VERSION "dbc-export 1 2026.26.6.5"

NS_ :

BS_:

BU_: APP APS BMS CC CMP CMPD CP DAS DI DIF DIR EPBL EPBR EVSE FC GTW HCML HCMR HVP ICR PCS PCS2 PLG PM PMF PMR PTC SCCM SCM SCS SDCR TAS UMC V2G VC VCBATT VCBATT0 VCBATT1 VCBATT2 VCFRONT VCFRONT1 VCFRONT2 VCLEFT VCRIGHT VCSEC

BO_ 1017 VCSEC_alertMatrix: 8 VCSEC
 SG_ VCSEC_matrixIndex M : 0|4@1+ (1,0) [0|15] "" Vector__XXX
 SG_ VCSEC_a001_WatchdogReset m0 : 4|1@1+ (1,0) [0|1] "" Vector__XXX
 SG_ VCSEC_a002_PowerLossReset m0 : 5|1@1+ (1,0) [0|1] "" Vector__XXX
 SG_ VCSEC_a003_SWAssertion m0 : 6|1@1+ (1,0) [0|1] "" Vector__XXX
 SG_ VCSEC_a005_CANTXError m0 : 8|1@1+ (1,0) [0|1] "" Vector__XXX
 SG_ VCSEC_a006_CANTX_cyclicError m0 : 9|1@1+ (1,0) [0|1] "" Vector__XXX
 SG_ VCSEC_a010_ExtSupplyVoltError m0 : 13|1@1+ (1,0) [0|1] "" Vector__XXX
 SG_ VCSEC_a012_CPUReset m0 : 15|1@1+ (1,0) [0|1] "" Vector__XXX
 SG_ VCSEC_a013_AlertManagerFault m0 : 16|1@1+ (1,0) [0|1] "" Vector__XXX
 SG_ VCSEC_a015_NVMMError m0 : 18|1@1+ (1,0) [0|1] "" Vector__XXX
 SG_ VCSEC_a016_NVMMRecordError m0 : 19|1@1+ (1,0) [0|1] "" Vector__XXX
 SG_ VCSEC_a017_NVMMStatusDbg m0 : 20|1@1+ (1,0) [0|1] "" Vector__XXX
 SG_ VCSEC_a021_TaskSchedulerError m0 : 24|1@1+ (1,0) [0|1] "" Vector__XXX
 SG_ VCSEC_a022_TaskInitError m0 : 25|1@1+ (1,0) [0|1] "" Vector__XXX
 SG_ VCSEC_a029_CoreDump m0 : 32|1@1+ (1,0) [0|1] "" Vector__XXX
 SG_ VCSEC_a030_ECULogUploadRequest m0 : 33|1@1+ (1,0) [0|1] "" Vector__XXX
 SG_ VCSEC_a031_UDSActive m0 : 34|1@1+ (1,0) [0|1] "" Vector__XXX
 SG_ VCSEC_a041_HighCPULoad m0 : 44|1@1+ (1,0) [0|1] "" Vector__XXX
 SG_ VCSEC_a042_HighStackUsage m0 : 45|1@1+ (1,0) [0|1] "" Vector__XXX
 SG_ VCSEC_a043_Task1msError m0 : 46|1@1+ (1,0) [0|1] "" Vector__XXX
 SG_ VCSEC_a044_Task10msError m0 : 47|1@1+ (1,0) [0|1] "" Vector__XXX
 SG_ VCSEC_a045_Task100msError m0 : 48|1@1+ (1,0) [0|1] "" Vector__XXX
 SG_ VCSEC_a046_Task1000msError m0 : 49|1@1+ (1,0) [0|1] "" Vector__XXX
 SG_ VCSEC_a057_HVP_MIA m0 : 60|1@1+ (1,0) [0|1] "" Vector__XXX
 SG_ VCSEC_a058_inputRHighSyncDebug m0 : 61|1@1+ (1,0) [0|1] "" Vector__XXX
 SG_ VCSEC_a059_inputResistanceHigh m0 : 62|1@1+ (1,0) [0|1] "" Vector__XXX
 SG_ VCSEC_a060_engineeringBuild m0 : 63|1@1+ (1,0) [0|1] "" Vector__XXX
 SG_ VCSEC_a061_XCPConnected m1 : 4|1@1+ (1,0) [0|1] "" Vector__XXX
 SG_ VCSEC_a062_XCPWasConnected m1 : 5|1@1+ (1,0) [0|1] "" Vector__XXX
 SG_ VCSEC_a063_SwitchFault m1 : 6|1@1+ (1,0) [0|1] "" Vector__XXX
 SG_ VCSEC_a064_busSleepReqTimeout m1 : 7|1@1+ (1,0) [0|1] "" Vector__XXX
 SG_ VCSEC_a082_VCRIGHT_IPC_MIA m1 : 25|1@1+ (1,0) [0|1] "" Vector__XXX
 SG_ VCSEC_a083_VCLEFT_IPC_MIA m1 : 26|1@1+ (1,0) [0|1] "" Vector__XXX
 SG_ VCSEC_a084_TPMS_MIA m1 : 27|1@1+ (1,0) [0|1] "" Vector__XXX
 SG_ VCSEC_a085_CCCM_MIA m1 : 28|1@1+ (1,0) [0|1] "" Vector__XXX
 SG_ VCSEC_a086_VCBATT_MIA m1 : 29|1@1+ (1,0) [0|1] "" Vector__XXX
 SG_ VCSEC_a087_DIREL_MIA m1 : 30|1@1+ (1,0) [0|1] "" Vector__XXX
 SG_ VCSEC_a088_DIRER_MIA m1 : 31|1@1+ (1,0) [0|1] "" Vector__XXX
 SG_ VCSEC_a089_IBST_MIA m1 : 32|1@1+ (1,0) [0|1] "" Vector__XXX
 SG_ VCSEC_a090_APS_MIA m1 : 33|1@1+ (1,0) [0|1] "" Vector__XXX
 SG_ VCSEC_a091_CMPD_MIA m1 : 34|1@1+ (1,0) [0|1] "" Vector__XXX
 SG_ VCSEC_a092_VCSEATD_MIA m1 : 35|1@1+ (1,0) [0|1] "" Vector__XXX
 SG_ VCSEC_a093_VCSEATP_MIA m1 : 36|1@1+ (1,0) [0|1] "" Vector__XXX
 SG_ VCSEC_a094_EPAS3P_MIA m1 : 37|1@1+ (1,0) [0|1] "" Vector__XXX
 SG_ VCSEC_a095_CHG_MIA m1 : 38|1@1+ (1,0) [0|1] "" Vector__XXX
 SG_ VCSEC_a096_OCS1P_MIA m1 : 39|1@1+ (1,0) [0|1] "" Vector__XXX
 SG_ VCSEC_a097_CMP_MIA m1 : 40|1@1+ (1,0) [0|1] "" Vector__XXX
 SG_ VCSEC_a098_DIR_MIA m1 : 41|1@1+ (1,0) [0|1] "" Vector__XXX
 SG_ VCSEC_a099_PARK_MIA m1 : 42|1@1+ (1,0) [0|1] "" Vector__XXX
 SG_ VCSEC_a100_CANbus_MIA m1 : 43|1@1+ (1,0) [0|1] "" Vector__XXX
 SG_ VCSEC_a101_PM_MIA m1 : 44|1@1+ (1,0) [0|1] "" Vector__XXX
 SG_ VCSEC_a102_PTC_MIA m1 : 45|1@1+ (1,0) [0|1] "" Vector__XXX
 SG_ VCSEC_a103_CP_MIA m1 : 46|1@1+ (1,0) [0|1] "" Vector__XXX
 SG_ VCSEC_a104_DAS_MIA m1 : 47|1@1+ (1,0) [0|1] "" Vector__XXX
 SG_ VCSEC_a105_TAS_MIA m1 : 48|1@1+ (1,0) [0|1] "" Vector__XXX
 SG_ VCSEC_a106_PCS_MIA m1 : 49|1@1+ (1,0) [0|1] "" Vector__XXX
 SG_ VCSEC_a107_BMS_MIA m1 : 50|1@1+ (1,0) [0|1] "" Vector__XXX
 SG_ VCSEC_a108_DIF_MIA m1 : 51|1@1+ (1,0) [0|1] "" Vector__XXX
 SG_ VCSEC_a109_RCM_MIA m1 : 52|1@1+ (1,0) [0|1] "" Vector__XXX
 SG_ VCSEC_a110_GTW_MIA m1 : 53|1@1+ (1,0) [0|1] "" Vector__XXX
 SG_ VCSEC_a111_EPBR_MIA m1 : 54|1@1+ (1,0) [0|1] "" Vector__XXX
 SG_ VCSEC_a112_EPBL_MIA m1 : 55|1@1+ (1,0) [0|1] "" Vector__XXX
 SG_ VCSEC_a113_UI_MIA m1 : 56|1@1+ (1,0) [0|1] "" Vector__XXX
 SG_ VCSEC_a114_ESP_MIA m1 : 57|1@1+ (1,0) [0|1] "" Vector__XXX
 SG_ VCSEC_a115_VCSEC_MIA m1 : 58|1@1+ (1,0) [0|1] "" Vector__XXX
 SG_ VCSEC_a116_VCRIGHT_MIA m1 : 59|1@1+ (1,0) [0|1] "" Vector__XXX
 SG_ VCSEC_a117_VCLEFT_MIA m1 : 60|1@1+ (1,0) [0|1] "" Vector__XXX
 SG_ VCSEC_a118_VCFRONT_MIA m1 : 61|1@1+ (1,0) [0|1] "" Vector__XXX
 SG_ VCSEC_a119_SCCM_MIA m1 : 62|1@1+ (1,0) [0|1] "" Vector__XXX
 SG_ VCSEC_a120_DI_DRIVE_MIA m1 : 63|1@1+ (1,0) [0|1] "" Vector__XXX
 SG_ VCSEC_a121_ICR_MIA m2 : 4|1@1+ (1,0) [0|1] "" Vector__XXX
 SG_ VCSEC_a133_alarmTriggered m2 : 16|1@1+ (1,0) [0|1] "" Vector__XXX
 SG_ VCSEC_a134_noVINLoaded m2 : 17|1@1+ (1,0) [0|1] "" Vector__XXX
 SG_ VCSEC_a135_centerEndpointBusy m2 : 18|1@1+ (1,0) [0|1] "" Vector__XXX
 SG_ VCSEC_a136_leftEndpointBusy m2 : 19|1@1+ (1,0) [0|1] "" Vector__XXX
 SG_ VCSEC_a137_rightEndpointBusy m2 : 20|1@1+ (1,0) [0|1] "" Vector__XXX
 SG_ VCSEC_a138_rearEndpointBusy m2 : 21|1@1+ (1,0) [0|1] "" Vector__XXX
 SG_ VCSEC_a140_nfcAuthentication m2 : 23|1@1+ (1,0) [0|1] "" Vector__XXX
 SG_ VCSEC_a141_tooFewKeysOnWhitelist m2 : 24|1@1+ (1,0) [0|1] "" Vector__XXX
 SG_ VCSEC_a142_bleGattAlertC m2 : 25|1@1+ (1,0) [0|1] "" Vector__XXX
 SG_ VCSEC_a143_bleGattAlertL m2 : 26|1@1+ (1,0) [0|1] "" Vector__XXX
 SG_ VCSEC_a144_bleGattAlertR m2 : 27|1@1+ (1,0) [0|1] "" Vector__XXX
 SG_ VCSEC_a145_bleGattAlertRe m2 : 28|1@1+ (1,0) [0|1] "" Vector__XXX
 SG_ VCSEC_a147_protobufRXTimeout m2 : 30|1@1+ (1,0) [0|1] "" Vector__XXX
 SG_ VCSEC_a148_keyWhitelistFull m2 : 31|1@1+ (1,0) [0|1] "" Vector__XXX
 SG_ VCSEC_a149_attrsWentMissingL m2 : 32|1@1+ (1,0) [0|1] "" Vector__XXX
 SG_ VCSEC_a150_attrsWentMissingR m2 : 33|1@1+ (1,0) [0|1] "" Vector__XXX
 SG_ VCSEC_a151_attrsWentMissingRe m2 : 34|1@1+ (1,0) [0|1] "" Vector__XXX
 SG_ VCSEC_a153_srvcCmdTimeoutC m2 : 36|1@1+ (1,0) [0|1] "" Vector__XXX
 SG_ VCSEC_a154_srvcCmdTimeoutL m2 : 37|1@1+ (1,0) [0|1] "" Vector__XXX
 SG_ VCSEC_a155_srvcCmdTimeoutR m2 : 38|1@1+ (1,0) [0|1] "" Vector__XXX
 SG_ VCSEC_a156_srvcCmdTimeoutRe m2 : 39|1@1+ (1,0) [0|1] "" Vector__XXX
 SG_ VCSEC_a158_hciDebugC m2 : 41|1@1+ (1,0) [0|1] "" Vector__XXX
 SG_ VCSEC_a159_hciDebugL m2 : 42|1@1+ (1,0) [0|1] "" Vector__XXX
 SG_ VCSEC_a161_hciDebugR m2 : 44|1@1+ (1,0) [0|1] "" Vector__XXX
 SG_ VCSEC_a162_hciDebugRe m2 : 45|1@1+ (1,0) [0|1] "" Vector__XXX
 SG_ VCSEC_a164_attrsWentMissingC m2 : 47|1@1+ (1,0) [0|1] "" Vector__XXX
 SG_ VCSEC_a165_ephemeralKeyGenerated m2 : 48|1@1+ (1,0) [0|1] "" Vector__XXX
 SG_ VCSEC_a166_BLECenterPowerCycled m2 : 49|1@1+ (1,0) [0|1] "" Vector__XXX
 SG_ VCSEC_a167_BLECenterSoftReset m2 : 50|1@1+ (1,0) [0|1] "" Vector__XXX
 SG_ VCSEC_a168_BLELeftSoftReset m2 : 51|1@1+ (1,0) [0|1] "" Vector__XXX
 SG_ VCSEC_a169_BLERightSoftReset m2 : 52|1@1+ (1,0) [0|1] "" Vector__XXX
 SG_ VCSEC_a170_BLERearSoftReset m2 : 53|1@1+ (1,0) [0|1] "" Vector__XXX
 SG_ VCSEC_a172_BLEUnexpectedResetC m2 : 55|1@1+ (1,0) [0|1] "" Vector__XXX
 SG_ VCSEC_a173_BLEUnexpectedResetL m2 : 56|1@1+ (1,0) [0|1] "" Vector__XXX
 SG_ VCSEC_a174_BLEUnexpectedResetRi m2 : 57|1@1+ (1,0) [0|1] "" Vector__XXX
 SG_ VCSEC_a175_BLEUnexpectedResetRe m2 : 58|1@1+ (1,0) [0|1] "" Vector__XXX
 SG_ VCSEC_a177_whitelistAddedKey m2 : 60|1@1+ (1,0) [0|1] "" Vector__XXX
 SG_ VCSEC_a178_whitelistRemovedKey m2 : 61|1@1+ (1,0) [0|1] "" Vector__XXX
 SG_ VCSEC_a179_InfotainmentNotPaired m2 : 62|1@1+ (1,0) [0|1] "" Vector__XXX
 SG_ VCSEC_a180_wlistRemovedPermissio m2 : 63|1@1+ (1,0) [0|1] "" Vector__XXX
 SG_ VCSEC_a181_signedMessageFault m3 : 4|1@1+ (1,0) [0|1] "" Vector__XXX
 SG_ VCSEC_a182_cryptoHighStackUsage m3 : 5|1@1+ (1,0) [0|1] "" Vector__XXX
 SG_ VCSEC_a183_centerEndpointRFMia m3 : 6|1@1+ (1,0) [0|1] "" Vector__XXX
 SG_ VCSEC_a184_driverEndpointRFMia m3 : 7|1@1+ (1,0) [0|1] "" Vector__XXX
 SG_ VCSEC_a185_passengerEndpointRFMi m3 : 8|1@1+ (1,0) [0|1] "" Vector__XXX
 SG_ VCSEC_a186_rearEndpointRFMia m3 : 9|1@1+ (1,0) [0|1] "" Vector__XXX
 SG_ VCSEC_a187_badConnectionDropped m3 : 10|1@1+ (1,0) [0|1] "" Vector__XXX
 SG_ VCSEC_a188_protobufDecodeError m3 : 11|1@1+ (1,0) [0|1] "" Vector__XXX
 SG_ VCSEC_a189_protoExpLengthTooLarg m3 : 12|1@1+ (1,0) [0|1] "" Vector__XXX
 SG_ VCSEC_a190_protoTooManyBytes m3 : 13|1@1+ (1,0) [0|1] "" Vector__XXX
 SG_ VCSEC_a191_macIDWlistingFailedC m3 : 14|1@1+ (1,0) [0|1] "" Vector__XXX
 SG_ VCSEC_a192_macIDWlistingFailedL m3 : 15|1@1+ (1,0) [0|1] "" Vector__XXX
 SG_ VCSEC_a193_macIDWlistingFailedRi m3 : 16|1@1+ (1,0) [0|1] "" Vector__XXX
 SG_ VCSEC_a194_macIDWlistingFailedRe m3 : 17|1@1+ (1,0) [0|1] "" Vector__XXX
 SG_ VCSEC_a195_keyMissingInDrive m3 : 18|1@1+ (1,0) [0|1] "" Vector__XXX
 SG_ VCSEC_a196_protobufTXTimeout m3 : 19|1@1+ (1,0) [0|1] "" Vector__XXX
 SG_ VCSEC_a197_indicationFault m3 : 20|1@1+ (1,0) [0|1] "" Vector__XXX
 SG_ VCSEC_a198_BPillarNFCReaderMIA m3 : 21|1@1+ (1,0) [0|1] "" Vector__XXX
 SG_ VCSEC_a199_CenterNFCReaderMIA m3 : 22|1@1+ (1,0) [0|1] "" Vector__XXX
 SG_ VCSEC_a200_centerEndpointLostCom m3 : 23|1@1+ (1,0) [0|1] "" Vector__XXX
 SG_ VCSEC_a201_leftEndpointLostComm m3 : 24|1@1+ (1,0) [0|1] "" Vector__XXX
 SG_ VCSEC_a202_rightEndpointLostComm m3 : 25|1@1+ (1,0) [0|1] "" Vector__XXX
 SG_ VCSEC_a203_rearEndpointLostComm m3 : 26|1@1+ (1,0) [0|1] "" Vector__XXX
 SG_ VCSEC_a204_SharedSecretsWritten m3 : 27|1@1+ (1,0) [0|1] "" Vector__XXX
 SG_ VCSEC_a205_MTUUpdateNotConfirmed m3 : 28|1@1+ (1,0) [0|1] "" Vector__XXX
 SG_ VCSEC_a206_BLELeftAssertFailure m3 : 29|1@1+ (1,0) [0|1] "" Vector__XXX
 SG_ VCSEC_a207_BLERightAssertFailure m3 : 30|1@1+ (1,0) [0|1] "" Vector__XXX
 SG_ VCSEC_a208_BLERearAssertFailure m3 : 31|1@1+ (1,0) [0|1] "" Vector__XXX
 SG_ VCSEC_a209_BLECenterAssertFailur m3 : 32|1@1+ (1,0) [0|1] "" Vector__XXX
 SG_ VCSEC_a210_keyDeviceBatteryLow m3 : 33|1@1+ (1,0) [0|1] "" Vector__XXX
 SG_ VCSEC_a211_handlePullWithoutAuth m3 : 34|1@1+ (1,0) [0|1] "" Vector__XXX
 SG_ VCSEC_a212_snifferRSSIMIA m3 : 35|1@1+ (1,0) [0|1] "" Vector__XXX
 SG_ VCSEC_a213_gattTimeoutWithExptdC m3 : 36|1@1+ (1,0) [0|1] "" Vector__XXX
 SG_ VCSEC_a214_gattServFalseWaitToBo m3 : 37|1@1+ (1,0) [0|1] "" Vector__XXX
 SG_ VCSEC_a215_TPMSUnexpectedDisconn m3 : 38|1@1+ (1,0) [0|1] "" Vector__XXX
 SG_ VCSEC_a216_TPMSUnexpectedDisconn m3 : 39|1@1+ (1,0) [0|1] "" Vector__XXX
 SG_ VCSEC_a217_TPMSUnexpectedDisconn m3 : 40|1@1+ (1,0) [0|1] "" Vector__XXX
 SG_ VCSEC_a218_TPMSUnexpectedDisconn m3 : 41|1@1+ (1,0) [0|1] "" Vector__XXX
 SG_ VCSEC_a219_TPMSSensorPairingRemo m3 : 42|1@1+ (1,0) [0|1] "" Vector__XXX
 SG_ VCSEC_a220_TPMSSensorPairingNotC m3 : 43|1@1+ (1,0) [0|1] "" Vector__XXX
 SG_ VCSEC_a221_TPMSSoftWarning m3 : 44|1@1+ (1,0) [0|1] "" Vector__XXX
 SG_ VCSEC_a222_TPMSSystemMalfunction m3 : 45|1@1+ (1,0) [0|1] "" Vector__XXX
 SG_ VCSEC_a223_TPMSSensorConnectionC m3 : 46|1@1+ (1,0) [0|1] "" Vector__XXX
 SG_ VCSEC_a224_TPMSSensorConnectionC m3 : 47|1@1+ (1,0) [0|1] "" Vector__XXX
 SG_ VCSEC_a225_TPMSSensorConnectionC m3 : 48|1@1+ (1,0) [0|1] "" Vector__XXX
 SG_ VCSEC_a226_TPMSSensorConnectionC m3 : 49|1@1+ (1,0) [0|1] "" Vector__XXX
 SG_ VCSEC_a227_connectionWithoutLink m3 : 50|1@1+ (1,0) [0|1] "" Vector__XXX
 SG_ VCSEC_a228_TPMSHardWarning m3 : 51|1@1+ (1,0) [0|1] "" Vector__XXX
 SG_ VCSEC_a235_presentWithoutHandleP m3 : 58|1@1+ (1,0) [0|1] "" Vector__XXX
 SG_ VCSEC_a236_keyIdentificationMaxA m3 : 59|1@1+ (1,0) [0|1] "" Vector__XXX
 SG_ VCSEC_a237_keyNotReadyToReceiveI m3 : 60|1@1+ (1,0) [0|1] "" Vector__XXX
 SG_ VCSEC_a238_TPMSLocationsUpdated m3 : 61|1@1+ (1,0) [0|1] "" Vector__XXX
 SG_ VCSEC_a239_TPMSIdleConnection m3 : 62|1@1+ (1,0) [0|1] "" Vector__XXX
 SG_ VCSEC_a240_noKeysPaired m3 : 63|1@1+ (1,0) [0|1] "" Vector__XXX
 SG_ VCSEC_a241_TPMSUpdateStartedSens m4 : 4|1@1+ (1,0) [0|1] "" Vector__XXX
 SG_ VCSEC_a242_TPMSUpdateStartedSens m4 : 5|1@1+ (1,0) [0|1] "" Vector__XXX
 SG_ VCSEC_a243_TPMSUpdateStartedSens m4 : 6|1@1+ (1,0) [0|1] "" Vector__XXX
 SG_ VCSEC_a244_TPMSUpdateStartedSens m4 : 7|1@1+ (1,0) [0|1] "" Vector__XXX
 SG_ VCSEC_a245_TPMSUpdateInterrupted m4 : 8|1@1+ (1,0) [0|1] "" Vector__XXX
 SG_ VCSEC_a246_TPMSUpdateInterrupted m4 : 9|1@1+ (1,0) [0|1] "" Vector__XXX
 SG_ VCSEC_a247_TPMSUpdateInterrupted m4 : 10|1@1+ (1,0) [0|1] "" Vector__XXX
 SG_ VCSEC_a248_TPMSUpdateInterrupted m4 : 11|1@1+ (1,0) [0|1] "" Vector__XXX
 SG_ VCSEC_a249_TPMSUpdateCompleteSen m4 : 12|1@1+ (1,0) [0|1] "" Vector__XXX
 SG_ VCSEC_a250_TPMSUpdateCompleteSen m4 : 13|1@1+ (1,0) [0|1] "" Vector__XXX
 SG_ VCSEC_a251_TPMSUpdateCompleteSen m4 : 14|1@1+ (1,0) [0|1] "" Vector__XXX
 SG_ VCSEC_a252_TPMSUpdateCompleteSen m4 : 15|1@1+ (1,0) [0|1] "" Vector__XXX
 SG_ VCSEC_a254_whitelistUpdatedKey m4 : 17|1@1+ (1,0) [0|1] "" Vector__XXX
 SG_ VCSEC_a255_wlistUpdatedPermissio m4 : 18|1@1+ (1,0) [0|1] "" Vector__XXX
 SG_ VCSEC_a256_whitelistOperationFai m4 : 19|1@1+ (1,0) [0|1] "" Vector__XXX
 SG_ VCSEC_a257_connectedKeyIsExpirin m4 : 20|1@1+ (1,0) [0|1] "" Vector__XXX
 SG_ VCSEC_a258_keyIsExpiring m4 : 21|1@1+ (1,0) [0|1] "" Vector__XXX
 SG_ VCSEC_a260_prsntPhoneKeyDisconne m4 : 23|1@1+ (1,0) [0|1] "" Vector__XXX
 SG_ VCSEC_a261_TPMSFactoryLearnActiv m4 : 24|1@1+ (1,0) [0|1] "" Vector__XXX
 SG_ VCSEC_a262_flowControlBackedUp m4 : 25|1@1+ (1,0) [0|1] "" Vector__XXX
 SG_ VCSEC_a263_dispatchCouldNotBeCom m4 : 26|1@1+ (1,0) [0|1] "" Vector__XXX
 SG_ VCSEC_a264_noOnePopulatedMessage m4 : 27|1@1+ (1,0) [0|1] "" Vector__XXX
 SG_ VCSEC_a265_tooManyPopulatedMessa m4 : 28|1@1+ (1,0) [0|1] "" Vector__XXX
 SG_ VCSEC_a266_TPMSSoftWarningFrontL m4 : 29|1@1+ (1,0) [0|1] "" Vector__XXX
 SG_ VCSEC_a267_TPMSSoftWarningFrontR m4 : 30|1@1+ (1,0) [0|1] "" Vector__XXX
 SG_ VCSEC_a268_TPMSSoftWarningRearLe m4 : 31|1@1+ (1,0) [0|1] "" Vector__XXX
 SG_ VCSEC_a269_TPMSSoftWarningRearRi m4 : 32|1@1+ (1,0) [0|1] "" Vector__XXX
 SG_ VCSEC_a270_TPMSHardWarningFrontL m4 : 33|1@1+ (1,0) [0|1] "" Vector__XXX
 SG_ VCSEC_a271_TPMSHardWarningFrontR m4 : 34|1@1+ (1,0) [0|1] "" Vector__XXX
 SG_ VCSEC_a272_TPMSHardWarningRearLe m4 : 35|1@1+ (1,0) [0|1] "" Vector__XXX
 SG_ VCSEC_a273_TPMSHardWarningRearRi m4 : 36|1@1+ (1,0) [0|1] "" Vector__XXX
 SG_ VCSEC_a274_handlePullWithoutAuth m4 : 37|1@1+ (1,0) [0|1] "" Vector__XXX
 SG_ VCSEC_a275_childSeatNotConnected m4 : 38|1@1+ (1,0) [0|1] "" Vector__XXX
 SG_ VCSEC_a276_childSeatNotConnected m4 : 39|1@1+ (1,0) [0|1] "" Vector__XXX
 SG_ VCSEC_a277_childSeatBatteryIsLow m4 : 40|1@1+ (1,0) [0|1] "" Vector__XXX
 SG_ VCSEC_a280_TPMSLowBattery0 m4 : 43|1@1+ (1,0) [0|1] "" Vector__XXX
 SG_ VCSEC_a281_TPMSLowBattery1 m4 : 44|1@1+ (1,0) [0|1] "" Vector__XXX
 SG_ VCSEC_a282_TPMSLowBattery2 m4 : 45|1@1+ (1,0) [0|1] "" Vector__XXX
 SG_ VCSEC_a283_TPMSLowBattery3 m4 : 46|1@1+ (1,0) [0|1] "" Vector__XXX
 SG_ VCSEC_a300_scheduleItKeyAdded m4 : 63|1@1+ (1,0) [0|1] "" Vector__XXX
 SG_ VCSEC_a301_imposterDetected m5 : 4|1@1+ (1,0) [0|1] "" Vector__XXX
 SG_ VCSEC_a302_unfused m5 : 5|1@1+ (1,0) [0|1] "" Vector__XXX
 SG_ VCSEC_a303_KeyfobUpdateInterrupt m5 : 6|1@1+ (1,0) [0|1] "" Vector__XXX
 SG_ VCSEC_a304_KeyfobUpdateComplete m5 : 7|1@1+ (1,0) [0|1] "" Vector__XXX
 SG_ VCSEC_a305_ATTFlowControlViolate m5 : 8|1@1+ (1,0) [0|1] "" Vector__XXX
 SG_ VCSEC_a306_KeyfobAdvReceivedWhil m5 : 9|1@1+ (1,0) [0|1] "" Vector__XXX
 SG_ VCSEC_a307_ATTTimeout m5 : 10|1@1+ (1,0) [0|1] "" Vector__XXX
 SG_ VCSEC_a308_NonConnectableAdvRece m5 : 11|1@1+ (1,0) [0|1] "" Vector__XXX
 SG_ VCSEC_a309_serviceKeyConditionsN m5 : 12|1@1+ (1,0) [0|1] "" Vector__XXX
 SG_ VCSEC_a310_chargePortFilterFalse m5 : 13|1@1+ (1,0) [0|1] "" Vector__XXX
 SG_ VCSEC_a311_moreThanThreeKeysPres m5 : 14|1@1+ (1,0) [0|1] "" Vector__XXX
 SG_ VCSEC_a312_unexpectedBLEDisconne m5 : 15|1@1+ (1,0) [0|1] "" Vector__XXX
 SG_ VCSEC_a315_bleBondingEvent m5 : 18|1@1+ (1,0) [0|1] "" Vector__XXX
 SG_ VCSEC_a316_ltkRequestRejected m5 : 19|1@1+ (1,0) [0|1] "" Vector__XXX
 SG_ VCSEC_a401_rearLeftEndpointLostC m6 : 44|1@1+ (1,0) [0|1] "" Vector__XXX
 SG_ VCSEC_a402_rearRightEndpointLost m6 : 45|1@1+ (1,0) [0|1] "" Vector__XXX
 SG_ VCSEC_a404_NFCCradleEndpointLost m6 : 47|1@1+ (1,0) [0|1] "" Vector__XXX
 SG_ VCSEC_a406_hciDebugRL m6 : 49|1@1+ (1,0) [0|1] "" Vector__XXX
 SG_ VCSEC_a407_hciDebugRR m6 : 50|1@1+ (1,0) [0|1] "" Vector__XXX
 SG_ VCSEC_a408_hciDebugNFCC m6 : 51|1@1+ (1,0) [0|1] "" Vector__XXX
 SG_ VCSEC_a411_leftRearEndpointBusy m6 : 54|1@1+ (1,0) [0|1] "" Vector__XXX
 SG_ VCSEC_a412_rightRearEndpointBusy m6 : 55|1@1+ (1,0) [0|1] "" Vector__XXX
 SG_ VCSEC_a413_NFCCradleEndpointBusy m6 : 56|1@1+ (1,0) [0|1] "" Vector__XXX
 SG_ VCSEC_a416_BLECradleNFCSoftReset m6 : 59|1@1+ (1,0) [0|1] "" Vector__XXX
 SG_ VCSEC_a417_BLERearLeftSoftReset m6 : 60|1@1+ (1,0) [0|1] "" Vector__XXX
 SG_ VCSEC_a418_BLERearRightSoftReset m6 : 61|1@1+ (1,0) [0|1] "" Vector__XXX
 SG_ VCSEC_a420_BLEUnexpectedResetNFC m6 : 63|1@1+ (1,0) [0|1] "" Vector__XXX
 SG_ VCSEC_a421_BLEUnexpectedResetRL m7 : 4|1@1+ (1,0) [0|1] "" Vector__XXX
 SG_ VCSEC_a422_BLEUnexpectedResetRR m7 : 5|1@1+ (1,0) [0|1] "" Vector__XXX
 SG_ VCSEC_a425_BLENFCCradleAssertFai m7 : 8|1@1+ (1,0) [0|1] "" Vector__XXX
 SG_ VCSEC_a426_BLERearLeftAssertFail m7 : 9|1@1+ (1,0) [0|1] "" Vector__XXX
 SG_ VCSEC_a427_BLERearRightAssertFai m7 : 10|1@1+ (1,0) [0|1] "" Vector__XXX
 SG_ VCSEC_a428_UWBCenterUpdateInterr m7 : 11|1@1+ (1,0) [0|1] "" Vector__XXX
 SG_ VCSEC_a429_UWBLeftUpdateInterrup m7 : 12|1@1+ (1,0) [0|1] "" Vector__XXX
 SG_ VCSEC_a430_UWBRightUpdateInterru m7 : 13|1@1+ (1,0) [0|1] "" Vector__XXX
 SG_ VCSEC_a432_UWBRearLeftUpdateInte m7 : 15|1@1+ (1,0) [0|1] "" Vector__XXX
 SG_ VCSEC_a433_UWBRearRightUpdateInt m7 : 16|1@1+ (1,0) [0|1] "" Vector__XXX
 SG_ VCSEC_a434_UWBRadioConfigUpdated m7 : 17|1@1+ (1,0) [0|1] "" Vector__XXX
 SG_ VCSEC_a435_NFCCardPresentWhileCh m7 : 18|1@1+ (1,0) [0|1] "" Vector__XXX
 SG_ VCSEC_a436_uhfHWDoesNotMatchCoun m7 : 19|1@1+ (1,0) [0|1] "" Vector__XXX
 SG_ VCSEC_a437_NearbyInteractionDebu m7 : 20|1@1+ (1,0) [0|1] "" Vector__XXX
 SG_ VCSEC_a438_UWBRearUpdateInterrup m7 : 21|1@1+ (1,0) [0|1] "" Vector__XXX
 SG_ VCSEC_a453_passiveDisabled m7 : 36|1@1+ (1,0) [0|1] "" Vector__XXX
 SG_ VCSEC_a454_TPMSOverPressureWarni m7 : 37|1@1+ (1,0) [0|1] "" Vector__XXX
 SG_ VCSEC_a455_TPMSOverPressureWarni m7 : 38|1@1+ (1,0) [0|1] "" Vector__XXX
 SG_ VCSEC_a456_TPMSOverPressureWarni m7 : 39|1@1+ (1,0) [0|1] "" Vector__XXX
 SG_ VCSEC_a457_TPMSOverPressureWarni m7 : 40|1@1+ (1,0) [0|1] "" Vector__XXX
 SG_ VCSEC_a458_TPMSOverPressureWarni m7 : 41|1@1+ (1,0) [0|1] "" Vector__XXX
 SG_ VCSEC_a459_TPMSCertCheckFailedSe m7 : 42|1@1+ (1,0) [0|1] "" Vector__XXX
 SG_ VCSEC_a460_TPMSCertCheckFailedSe m7 : 43|1@1+ (1,0) [0|1] "" Vector__XXX
 SG_ VCSEC_a461_TPMSCertCheckFailedSe m7 : 44|1@1+ (1,0) [0|1] "" Vector__XXX
 SG_ VCSEC_a462_TPMSCertCheckFailedSe m7 : 45|1@1+ (1,0) [0|1] "" Vector__XXX
 SG_ VCSEC_a465_UWBRearLeftKeyVerific m7 : 48|1@1+ (1,0) [0|1] "" Vector__XXX
 SG_ VCSEC_a466_UWBRearRightKeyVerifi m7 : 49|1@1+ (1,0) [0|1] "" Vector__XXX
 SG_ VCSEC_a467_UWBCenterKeyVerificat m7 : 50|1@1+ (1,0) [0|1] "" Vector__XXX
 SG_ VCSEC_a468_UWBRearKeyVerificatio m7 : 51|1@1+ (1,0) [0|1] "" Vector__XXX
 SG_ VCSEC_a469_UWBLeftKeyVerificatio m7 : 52|1@1+ (1,0) [0|1] "" Vector__XXX
 SG_ VCSEC_a470_UWBRightKeyVerificati m7 : 53|1@1+ (1,0) [0|1] "" Vector__XXX
 SG_ VCSEC_a472_peerRemovedInformatio m7 : 55|1@1+ (1,0) [0|1] "" Vector__XXX
 SG_ VCSEC_a473_handlePullWithoutAuth m7 : 56|1@1+ (1,0) [0|1] "" Vector__XXX
 SG_ VCSEC_a474_handlePullWithoutAuth m7 : 57|1@1+ (1,0) [0|1] "" Vector__XXX
 SG_ VCSEC_a475_handlePullWithoutAuth m7 : 58|1@1+ (1,0) [0|1] "" Vector__XXX
 SG_ VCSEC_a476_handlePullWithoutAuth m7 : 59|1@1+ (1,0) [0|1] "" Vector__XXX
 SG_ VCSEC_a477_phoneStartedBonding m7 : 60|1@1+ (1,0) [0|1] "" Vector__XXX
 SG_ VCSEC_a478_handlePullWithoutAuth m7 : 61|1@1+ (1,0) [0|1] "" Vector__XXX
 SG_ VCSEC_a479_handlePullWithoutAuth m7 : 62|1@1+ (1,0) [0|1] "" Vector__XXX
 SG_ VCSEC_a480_handlePullWithoutAuth m7 : 63|1@1+ (1,0) [0|1] "" Vector__XXX
 SG_ VCSEC_a481_handlePullWithoutAuth m8 : 4|1@1+ (1,0) [0|1] "" Vector__XXX
 SG_ VCSEC_a482_VINChanged m8 : 5|1@1+ (1,0) [0|1] "" Vector__XXX
 SG_ VCSEC_a483_highThermalGradiantDe m8 : 6|1@1+ (1,0) [0|1] "" Vector__XXX
 SG_ VCSEC_a484_UWBLeftUpdateTriggere m8 : 7|1@1+ (1,0) [0|1] "" Vector__XXX
 SG_ VCSEC_a485_UWBCenterUpdateTrigge m8 : 8|1@1+ (1,0) [0|1] "" Vector__XXX
 SG_ VCSEC_a486_UWBRightUpdateTrigger m8 : 9|1@1+ (1,0) [0|1] "" Vector__XXX
 SG_ VCSEC_a487_unrecognizedProto m8 : 10|1@1+ (1,0) [0|1] "" Vector__XXX
 SG_ VCSEC_a488_FiraRangingRejected m8 : 11|1@1+ (1,0) [0|1] "" Vector__XXX
 SG_ VCSEC_a489_UWBRearLeftUpdateTrig m8 : 12|1@1+ (1,0) [0|1] "" Vector__XXX
 SG_ VCSEC_a490_UWBRearRightUpdateTri m8 : 13|1@1+ (1,0) [0|1] "" Vector__XXX
 SG_ VCSEC_a494_UWBRearUpdateTriggere m8 : 17|1@1+ (1,0) [0|1] "" Vector__XXX
 SG_ VCSEC_a495_handlePullWithoutAuth m8 : 18|1@1+ (1,0) [0|1] "" Vector__XXX
 SG_ VCSEC_a496_handlePullWithoutAuth m8 : 19|1@1+ (1,0) [0|1] "" Vector__XXX
 SG_ VCSEC_a497_incorrectEndpointInst m8 : 20|1@1+ (1,0) [0|1] "" Vector__XXX
 SG_ VCSEC_a498_TPMSFeature0Reached m8 : 21|1@1+ (1,0) [0|1] "" Vector__XXX
 SG_ VCSEC_a499_TPMSAssertFailure0 m8 : 22|1@1+ (1,0) [0|1] "" Vector__XXX
 SG_ VCSEC_a500_TPMSAssertFailure1 m8 : 23|1@1+ (1,0) [0|1] "" Vector__XXX
 SG_ VCSEC_a501_TPMSAssertFailure2 m8 : 24|1@1+ (1,0) [0|1] "" Vector__XXX
 SG_ VCSEC_a502_TPMSAssertFailure3 m8 : 25|1@1+ (1,0) [0|1] "" Vector__XXX
 SG_ VCSEC_a503_CANMsgMACVerification m8 : 26|1@1+ (1,0) [0|1] "" Vector__XXX
 SG_ VCSEC_a504_CANMsgMACVerification m8 : 27|1@1+ (1,0) [0|1] "" Vector__XXX
 SG_ VCSEC_a505_CANMsgMACVerification m8 : 28|1@1+ (1,0) [0|1] "" Vector__XXX
 SG_ VCSEC_a510_watchKeyOffWrist m8 : 33|1@1+ (1,0) [0|1] "" Vector__XXX
 SG_ VCSEC_a511_phoneKeyStationary m8 : 34|1@1+ (1,0) [0|1] "" Vector__XXX
 SG_ VCSEC_a513_TPMSConnectionStatsNo m8 : 36|1@1+ (1,0) [0|1] "" Vector__XXX
 SG_ VCSEC_a514_TPMSConnectionStatsNo m8 : 37|1@1+ (1,0) [0|1] "" Vector__XXX
 SG_ VCSEC_a515_TPMSConnectionStatsNo m8 : 38|1@1+ (1,0) [0|1] "" Vector__XXX
 SG_ VCSEC_a516_TPMSConnectionStatsNo m8 : 39|1@1+ (1,0) [0|1] "" Vector__XXX
 SG_ VCSEC_a517_TPMSOutOfRangePressur m8 : 40|1@1+ (1,0) [0|1] "" Vector__XXX
 SG_ VCSEC_a518_TPMSOutOfRangePressur m8 : 41|1@1+ (1,0) [0|1] "" Vector__XXX
 SG_ VCSEC_a519_TPMSOutOfRangePressur m8 : 42|1@1+ (1,0) [0|1] "" Vector__XXX
 SG_ VCSEC_a520_TPMSOutOfRangePressur m8 : 43|1@1+ (1,0) [0|1] "" Vector__XXX
 SG_ VCSEC_a521_TPMSSensorLowConfiden m8 : 44|1@1+ (1,0) [0|1] "" Vector__XXX
 SG_ VCSEC_a522_TPMSSensorLowConfiden m8 : 45|1@1+ (1,0) [0|1] "" Vector__XXX
 SG_ VCSEC_a523_TPMSSensorLowConfiden m8 : 46|1@1+ (1,0) [0|1] "" Vector__XXX
 SG_ VCSEC_a524_TPMSSensorLowConfiden m8 : 47|1@1+ (1,0) [0|1] "" Vector__XXX
 SG_ VCSEC_a525_TPMSLocalizationMulti m8 : 48|1@1+ (1,0) [0|1] "" Vector__XXX
 SG_ VCSEC_a526_TPMSLocalizationMulti m8 : 49|1@1+ (1,0) [0|1] "" Vector__XXX
 SG_ VCSEC_a527_TPMSLocalizationMulti m8 : 50|1@1+ (1,0) [0|1] "" Vector__XXX
 SG_ VCSEC_a528_TPMSLocalizationMulti m8 : 51|1@1+ (1,0) [0|1] "" Vector__XXX
 SG_ VCSEC_a529_TPMSTireServiceDetect m8 : 52|1@1+ (1,0) [0|1] "" Vector__XXX
 SG_ VCSEC_a540_dummyAlertMax m8 : 63|1@1+ (1,0) [0|1] "" Vector__XXX

BO_ 825 VCSEC_authentication: 8 VCSEC
 SG_ VCSEC_BLEConnectionCounter : 0|4@1+ (1,0) [0|15] "" Vector__XXX
 SG_ VCSEC_authRejectionReason : 4|3@1+ (1,0) [0|7] "" Vector__XXX
 SG_ VCSEC_IDRequested : 7|1@1+ (1,0) [0|1] "" Vector__XXX
 SG_ VCSEC_operationMode : 8|2@1+ (1,0) [0|3] "" Vector__XXX
 SG_ VCSEC_vehicleLockStatus : 12|4@1+ (1,0) [1|15] "" Vector__XXX
 SG_ VCSEC_authenticationStatus : 16|2@1+ (1,0) [0|3] "" Vector__XXX
 SG_ VCSEC_chargePortLockStatus : 18|1@1+ (1,0) [0|1] "" Vector__XXX
 SG_ VCSEC_leftFrontLockStatus : 19|1@1+ (1,0) [0|1] "" Vector__XXX
 SG_ VCSEC_leftRearLockStatus : 20|1@1+ (1,0) [0|1] "" Vector__XXX
 SG_ VCSEC_rightFrontLockStatus : 21|1@1+ (1,0) [0|1] "" Vector__XXX
 SG_ VCSEC_rightRearLockStatus : 22|1@1+ (1,0) [0|1] "" Vector__XXX
 SG_ VCSEC_trunkLockStatus : 23|1@1+ (1,0) [0|1] "" Vector__XXX
 SG_ VCSEC_lockRequestType : 24|5@1+ (1,0) [0|31] "" Vector__XXX
 SG_ VCSEC_summonRequest : 29|3@1+ (1,0) [0|7] "" Vector__XXX
 SG_ VCSEC_3rdPartyPLGRequest : 32|2@1+ (1,0) [0|2] "" Vector__XXX
 SG_ VCSEC_3rdPartyFrunkPLGRequest : 34|2@1+ (1,0) [0|2] "" Vector__XXX
 SG_ VCSEC_MCUCommandType : 36|3@1+ (1,0) [0|7] "" Vector__XXX
 SG_ VCSEC_frunkLockStatus : 39|1@1+ (1,0) [0|1] "" Vector__XXX
 SG_ VCSEC_usingModifiedMACAddress : 40|1@1+ (1,0) [0|1] "" Vector__XXX
 SG_ VCSEC_isKeyWithinSummonRange : 41|1@1+ (1,0) [0|1] "" Vector__XXX
 SG_ VCSEC_isBLEDeviceWithinSummonRan : 42|1@1+ (1,0) [0|1] "" Vector__XXX
 SG_ VCSEC_alarmStatus : 43|4@1+ (1,0) [0|14] "" Vector__XXX
 SG_ VCSEC_serviceDiagnosticRequest : 47|1@1+ (1,0) [0|1] "" Vector__XXX
 SG_ VCSEC_immobilizerState : 48|3@1+ (1,0) [0|7] "" Vector__XXX
 SG_ VCSEC_lockIndicationRequest : 51|3@1+ (1,0) [1|7] "" Vector__XXX
 SG_ VCSEC_simpleLockStatus : 54|2@1+ (1,0) [1|3] "" Vector__XXX
 SG_ VCSEC_keyChannelIndexed : 56|4@1+ (1,0) [0|14] "" Vector__XXX
 SG_ VCSEC_authRequested : 60|1@1+ (1,0) [0|1] "" Vector__XXX
 SG_ VCSEC_remoteStartActive : 61|2@1+ (1,0) [0|3] "" Vector__XXX
 SG_ VCSEC_keyPairDesired : 63|1@1+ (1,0) [0|1] "" Vector__XXX

BO_ 1817 VCSEC_debug100ms: 8 VCSEC
 SG_ VCSEC_debug100msIndex M : 0|5@1+ (1,0) [0|31] "" Vector__XXX
 SG_ VCSEC_walkAwayLockKeyState m0 : 5|2@1+ (1,0) [0|3] "" Vector__XXX
 SG_ VCSEC_thresholdOffsetVersion m0 : 8|3@1+ (1,0) [0|7] "" Vector__XXX
 SG_ VCSEC_walkAwayLockState m0 : 11|3@1+ (1,0) [0|7] "" Vector__XXX
 SG_ VCSEC_rssi0WLEntry m0 : 16|5@1+ (1,0) [0|31] "" Vector__XXX
 SG_ VCSEC_endpointLayout m0 : 21|2@1+ (1,0) [0|3] "" Vector__XXX
 SG_ VCSEC_rssi1WLEntry m0 : 24|5@1+ (1,0) [0|31] "" Vector__XXX
 SG_ VCSEC_rssi2WLEntry m0 : 32|5@1+ (1,0) [0|31] "" Vector__XXX
 SG_ VCSEC_walkUpUnlockState m0 : 37|3@1+ (1,0) [0|7] "" Vector__XXX
 SG_ VCSEC_algoHighThreshLeft m0 : 40|1@1+ (1,0) [0|1] "" Vector__XXX
 SG_ VCSEC_algoHighThreshRight m0 : 41|1@1+ (1,0) [0|1] "" Vector__XXX
 SG_ VCSEC_algoHighThreshCenter m0 : 42|1@1+ (1,0) [0|1] "" Vector__XXX
 SG_ VCSEC_pollingReason m0 : 43|4@1+ (1,0) [0|15] "" Vector__XXX
 SG_ VCSEC_numberOfPubKeysOnWhitelist m0 : 48|5@1+ (1,0) [0|31] "" Vector__XXX
 SG_ VCSEC_thermalDetectState m0 : 53|2@1+ (1,0) [0|3] "" Vector__XXX
 SG_ VCSEC_chargeHandleMitigationActi m0 : 55|1@1+ (1,0) [0|1] "" Vector__XXX
 SG_ VCSEC_smartTrunkMitigatedKeyCoun m5 : 8|5@1+ (1,0) [0|31] "" Vector__XXX
 SG_ VCSEC_UWB3WLEntry m5 : 21|5@1+ (1,0) [0|31] "" Vector__XXX
 SG_ VCSEC_device0Offset m5 : 26|6@1- (0.5,0) [-16|15.5] "dBm" Vector__XXX
 SG_ VCSEC_device1Offset m5 : 32|6@1- (0.5,0) [-16|15.5] "dBm" Vector__XXX
 SG_ VCSEC_device2Offset m5 : 40|6@1- (0.5,0) [-16|15.5] "dBm" Vector__XXX
 SG_ VCSEC_connection0BondingState m7 : 8|4@1+ (1,0) [0|15] "" Vector__XXX
 SG_ VCSEC_connection1BondingState m7 : 12|4@1+ (1,0) [0|15] "" Vector__XXX
 SG_ VCSEC_connection2BondingState m7 : 16|4@1+ (1,0) [0|15] "" Vector__XXX
 SG_ VCSEC_connection0UWBAvailability m7 : 24|5@1+ (1,0) [0|31] "" Vector__XXX
 SG_ VCSEC_connection1UWBAvailability m7 : 32|5@1+ (1,0) [0|31] "" Vector__XXX
 SG_ VCSEC_connection2UWBAvailability m7 : 40|5@1+ (1,0) [0|31] "" Vector__XXX
 SG_ VCSEC_NISessionStateCenter0 m8 : 8|5@1+ (1,0) [0|31] "" Vector__XXX
 SG_ VCSEC_NISessionStateLeft0 m8 : 16|5@1+ (1,0) [0|31] "" Vector__XXX
 SG_ VCSEC_NISessionStateRight0 m8 : 24|5@1+ (1,0) [0|31] "" Vector__XXX
 SG_ VCSEC_NISessionStateRearLeft0 m8 : 29|5@1+ (1,0) [0|31] "" Vector__XXX
 SG_ VCSEC_NISessionStateRearRight0 m8 : 34|5@1+ (1,0) [0|31] "" Vector__XXX
 SG_ VCSEC_NISessionStateRear0 m8 : 39|5@1+ (1,0) [0|31] "" Vector__XXX
 SG_ VCSEC_NISessionStateCenter1 m8 : 44|5@1+ (1,0) [0|31] "" Vector__XXX
 SG_ VCSEC_NISessionStateLeft1 m8 : 49|5@1+ (1,0) [0|31] "" Vector__XXX
 SG_ VCSEC_NISessionStateRight1 m8 : 54|5@1+ (1,0) [0|31] "" Vector__XXX
 SG_ VCSEC_NISessionStateRearLeft1 m8 : 59|5@1+ (1,0) [0|31] "" Vector__XXX
 SG_ VCSEC_NISessionStateRearRight1 m9 : 8|5@1+ (1,0) [0|31] "" Vector__XXX
 SG_ VCSEC_NISessionStateRear1 m9 : 16|5@1+ (1,0) [0|31] "" Vector__XXX
 SG_ VCSEC_NISessionStateCenter2 m9 : 24|5@1+ (1,0) [0|31] "" Vector__XXX
 SG_ VCSEC_NISessionStateLeft2 m9 : 32|5@1+ (1,0) [0|31] "" Vector__XXX
 SG_ VCSEC_NISessionStateRight2 m9 : 40|5@1+ (1,0) [0|31] "" Vector__XXX
 SG_ VCSEC_NISessionStateRearLeft2 m9 : 48|5@1+ (1,0) [0|31] "" Vector__XXX
 SG_ VCSEC_NISessionStateRearRight2 m9 : 53|5@1+ (1,0) [0|31] "" Vector__XXX
 SG_ VCSEC_NISessionStateRear2 m9 : 58|5@1+ (1,0) [0|31] "" Vector__XXX
 SG_ VCSEC_NISessionStateLeft3 m10 : 8|5@1+ (1,0) [0|31] "" Vector__XXX
 SG_ VCSEC_NISessionStateRight3 m10 : 16|5@1+ (1,0) [0|31] "" Vector__XXX
 SG_ VCSEC_NISessionStateRearRight3 m10 : 24|5@1+ (1,0) [0|31] "" Vector__XXX
 SG_ VCSEC_NISessionStateRearLeft3 m10 : 32|5@1+ (1,0) [0|31] "" Vector__XXX
 SG_ VCSEC_NISessionStateCenter3 m10 : 40|5@1+ (1,0) [0|31] "" Vector__XXX

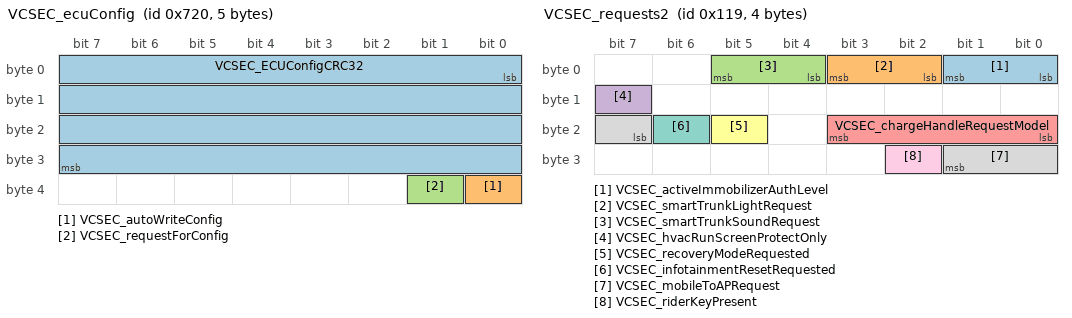
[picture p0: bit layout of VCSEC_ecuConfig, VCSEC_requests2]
BO_ 1824 VCSEC_ecuConfig: 5 VCSEC
 SG_ VCSEC_ECUConfigCRC32 : 0|32@1+ (1,0) [0|4294967295] "" Vector__XXX
 SG_ VCSEC_autoWriteConfig : 32|1@1+ (1,0) [0|1] "" Vector__XXX
 SG_ VCSEC_requestForConfig : 33|1@1+ (1,0) [0|1] "" Vector__XXX

BO_ 793 VCSEC_info: 8 VCSEC
 SG_ VCSEC_infoIndex M : 0|8@1+ (1,0) [0|255] "" Vector__XXX
 SG_ VCSEC_infoBuildType m10 : 8|3@1+ (1,0) [0|7] "" Vector__XXX
 SG_ VCSEC_infoBuildConfigId m10 : 16|16@1+ (1,0) [0|65535] "" Vector__XXX
 SG_ VCSEC_infoHardwareId m10 : 32|16@1+ (1,0) [0|65535] "" Vector__XXX
 SG_ VCSEC_infoComponentId m10 : 48|16@1+ (1,0) [0|65535] "" Vector__XXX
 SG_ VCSEC_infoPcbaId m11 : 8|8@1+ (1,0) [0|255] "" Vector__XXX
 SG_ VCSEC_infoAssemblyId m11 : 16|8@1+ (1,0) [0|254] "" Vector__XXX
 SG_ VCSEC_infoUsageId m11 : 32|16@1+ (1,0) [0|65535] "" Vector__XXX
 SG_ VCSEC_infoSubUsageId m11 : 48|16@1+ (1,0) [0|65535] "" Vector__XXX
 SG_ VCSEC_infoAppCrc m13 : 32|32@1+ (1,0) [0|4294967295] "" Vector__XXX
 SG_ VCSEC_infoSubcomponent1 m16 : 32|32@1+ (1,0) [0|4294967295] "" Vector__XXX
 SG_ VCSEC_infoAppGitHash m17 : 8|56@1+ (1,0) [0|7.20575940379e+16] "" Vector__XXX
 SG_ VCSEC_infoBootGitHash m18 : 8|56@1+ (1,0) [0|7.20575940379e+16] "" Vector__XXX
 SG_ VCSEC_infoPlatformType m19 : 8|8@1+ (1,0) [0|255] "" Vector__XXX
 SG_ VCSEC_infoBootUdsProtoVersion m20 : 8|16@1+ (1,0) [0|65535] "" Vector__XXX
 SG_ VCSEC_infoBootCrc m20 : 24|32@1+ (1,0) [0|4294967295] "" Vector__XXX
 SG_ VCSEC_infoSubcomponent2 m23 : 32|32@1+ (1,0) [0|4294967295] "" Vector__XXX
 SG_ VCSEC_infoSubcomponent3 m24 : 32|32@1+ (1,0) [0|4294967295] "" Vector__XXX
 SG_ VCSEC_infoSubcomponent4 m31 : 32|32@1+ (1,0) [0|4294967295] "" Vector__XXX

BO_ 505 VCSEC_requests: 8 VCSEC
 SG_ VCSEC_chargePortRequest : 0|2@1+ (1,0) [0|2] "" Vector__XXX
 SG_ VCSEC_presentHandles : 4|1@1+ (1,0) [0|1] "" Vector__XXX
 SG_ VCSEC_frontLeftClosureRequest : 5|3@1+ (1,0) [0|7] "" Vector__XXX
 SG_ VCSEC_frontRightClosureRequest : 8|3@1+ (1,0) [0|7] "" Vector__XXX
 SG_ VCSEC_rearLeftClosureRequest : 11|3@1+ (1,0) [0|7] "" Vector__XXX
 SG_ VCSEC_rearRightClosureRequest : 14|3@1+ (1,0) [0|7] "" Vector__XXX
 SG_ VCSEC_rearTrunkClosureRequest : 17|3@1+ (1,0) [0|7] "" Vector__XXX
 SG_ VCSEC_frontLeftRequestReason : 20|3@1+ (1,0) [0|7] "" Vector__XXX
 SG_ VCSEC_frontRightRequestReason : 23|3@1+ (1,0) [0|7] "" Vector__XXX
 SG_ VCSEC_rearLeftRequestReason : 26|3@1+ (1,0) [0|7] "" Vector__XXX
 SG_ VCSEC_rearRightRequestReason : 29|3@1+ (1,0) [0|7] "" Vector__XXX
 SG_ VCSEC_rearTrunkRequestReason : 32|3@1+ (1,0) [0|7] "" Vector__XXX
 SG_ VCSEC_rdMapDumpRequested : 35|1@1+ (1,0) [0|1] "" Vector__XXX
 SG_ VCSEC_driveAttemptedWithoutAuth : 36|4@1+ (1,0) [0|15] "" Vector__XXX
 SG_ VCSEC_closeAllStatus : 41|2@1+ (1,0) [0|3] "" Vector__XXX
 SG_ VCSEC_snapshotRequested : 43|4@1+ (1,0) [0|15] "" Vector__XXX
 SG_ VCSEC_chargeportRequestReason : 47|3@1+ (1,0) [0|7] "" Vector__XXX
 SG_ VCSEC_frontTrunkClosureRequest : 51|3@1+ (1,0) [0|7] "" Vector__XXX
 SG_ VCSEC_frontTrunkRequestReason : 54|3@1+ (1,0) [0|7] "" Vector__XXX

BO_ 281 VCSEC_requests2: 4 VCSEC
 SG_ VCSEC_activeImmobilizerAuthLevel : 0|2@1+ (1,0) [0|3] "" Vector__XXX
 SG_ VCSEC_smartTrunkLightRequest : 2|2@1+ (1,0) [0|3] "" Vector__XXX
 SG_ VCSEC_smartTrunkSoundRequest : 4|2@1+ (1,0) [0|3] "" Vector__XXX
 SG_ VCSEC_hvacRunScreenProtectOnly : 15|1@1+ (1,0) [0|1] "" Vector__XXX
 SG_ VCSEC_chargeHandleRequestModel : 16|4@1+ (1,0) [0|15] "" Vector__XXX
 SG_ VCSEC_recoveryModeRequested : 21|1@1+ (1,0) [0|1] "" Vector__XXX
 SG_ VCSEC_infotainmentResetRequested : 22|1@1+ (1,0) [0|1] "" Vector__XXX
 SG_ VCSEC_mobileToAPRequest : 23|3@1+ (1,0) [0|7] "" Vector__XXX
 SG_ VCSEC_riderKeyPresent : 26|1@1+ (1,0) [0|1] "" Vector__XXX

BO_ 1547 VCSEC_udsResponse: 8 VCSEC
 SG_ VCSEC_udsResponseData : 7|64@0+ (1,0) [0|1.84467440737e+19] "" Vector__XXX

BO_ 1850 VC_LVBMS_brickMeasurements: 8 VC
 SG_ VC_LVBMS_brickMeasurementsMultip M : 0|6@1+ (1,0) [0|63] "" Vector__XXX
 SG_ VC_LVBMS_brickVoltage1 m0 : 8|13@1+ (0.001,0) [0|6.535] "V" Vector__XXX
 SG_ VC_LVBMS_brickVoltage2 m0 : 24|13@1+ (0.001,0) [0|6.535] "V" Vector__XXX
 SG_ VC_LVBMS_brickVoltage3 m0 : 37|13@1+ (0.001,0) [0|6.535] "V" Vector__XXX
 SG_ VC_LVBMS_brickVoltage4 m0 : 50|13@1+ (0.001,0) [0|6.535] "V" Vector__XXX
 SG_ VC_LVBMS_brickBalancingAh1 m1 : 8|24@1+ (0.001,0) [0|16777.214] "Ah" Vector__XXX
 SG_ VC_LVBMS_brickBalancingAh2 m1 : 32|24@1+ (0.001,0) [0|16777.214] "Ah" Vector__XXX
 SG_ VC_LVBMS_brickBalancingState1 m1 : 56|1@1+ (1,0) [0|1] "" Vector__XXX
 SG_ VC_LVBMS_brickBalancingState2 m1 : 57|1@1+ (1,0) [0|1] "" Vector__XXX
 SG_ VC_LVBMS_brickBalancingAh3 m2 : 8|24@1+ (0.001,0) [0|16777.214] "Ah" Vector__XXX
 SG_ VC_LVBMS_brickBalancingAh4 m2 : 32|24@1+ (0.001,0) [0|16777.214] "Ah" Vector__XXX
 SG_ VC_LVBMS_brickBalancingState3 m2 : 56|1@1+ (1,0) [0|1] "" Vector__XXX
 SG_ VC_LVBMS_brickBalancingState4 m2 : 57|1@1+ (1,0) [0|1] "" Vector__XXX

BO_ 1655 VC_LVBMS_statusHigh: 8 VC
 SG_ VC_lvbmsStatusHighIndex M : 0|3@1+ (1,0) [0|7] "" Vector__XXX
 SG_ VC_LVBMS_packCurrent m0 : 3|22@1+ (0.001,-2000) [-2000|2194.302] "A" Vector__XXX
 SG_ VC_LVBMS_packVoltage m0 : 25|16@1+ (0.001,0) [0|65.534] "V" Vector__XXX
 SG_ VC_LVBMS_packTemperature m0 : 41|9@1+ (0.5,-50) [-50|205] "degC" Vector__XXX
 SG_ VC_LVBMS_MOSTemperature m0 : 50|12@1+ (0.5,-50) [-50|1997] "degC" Vector__XXX
 SG_ VC_LVBMS_sumCellVoltage m1 : 8|16@1+ (0.001,0) [0|65.534] "V" Vector__XXX
 SG_ VC_LVBMS_maxBrickVoltage m1 : 24|13@1+ (0.001,0) [0|8.19] "V" Vector__XXX
 SG_ VC_LVBMS_maxBrickVoltageIndex m1 : 40|8@1+ (1,0) [0|254] "" Vector__XXX
 SG_ VC_totalLVLoadCurrent m2 : 8|14@1- (0.1,0) [-200|400] "A" Vector__XXX
 SG_ VC_LVPackChargeCurrentLimit m2 : 22|12@1+ (0.1,0) [0|400] "A" Vector__XXX
 SG_ VC_LVPackCurrent m2 : 34|14@1- (0.1,0) [-200|400] "A" Vector__XXX
 SG_ VC_LVBMS_estimatedPackOcv m2 : 48|16@1+ (0.001,0) [0|65.535] "V" Vector__XXX
 SG_ VC_LVBMS_voltageTarget m3 : 3|16@1+ (0.001,0) [0|65.534] "V" Vector__XXX
 SG_ VC_LVBMS_currentTarget m3 : 19|18@1+ (0.001,-122) [-120|120] "A" Vector__XXX
 SG_ VC_LVBMS_maxAllowedChargeCurrent m3 : 37|13@1+ (0.1,0) [0|819] "A" Vector__XXX
 SG_ VC_LVBMS_maxAllowedDischargeCurr m3 : 50|13@1+ (0.1,0) [0|819] "A" Vector__XXX
 SG_ VC_LVBMS_MOSCommand m4 : 3|1@1+ (1,0) [0|1] "" Vector__XXX
 SG_ VC_LVBMS_ClearErrorCntrCommand m4 : 4|1@1+ (1,0) [0|1] "" Vector__XXX
 SG_ VC_LVBMS_ClearHistoricFaultComma m4 : 5|1@1+ (1,0) [0|1] "" Vector__XXX
 SG_ VC_LVBMS_ResetLVBMSCommand m4 : 6|1@1+ (1,0) [0|1] "" Vector__XXX
 SG_ VC_LVBMS_EnterHibernationCommand m4 : 7|1@1+ (1,0) [0|1] "" Vector__XXX
 SG_ VC_LVBMS_ECPAState m4 : 8|2@1+ (1,0) [0|2] "" Vector__XXX
 SG_ VC_LVBMS_MOSState m4 : 10|2@1+ (1,0) [0|2] "" Vector__XXX
 SG_ VC_LVBMS_VehicleState m4 : 12|2@1+ (1,0) [0|3] "" Vector__XXX
 SG_ VC_LVBMS_LINWakeDisabled m4 : 14|1@1+ (1,0) [0|1] "" Vector__XXX
 SG_ VC_LVBMS_chargeType m4 : 16|3@1+ (1,0) [0|7] "" Vector__XXX
 SG_ VC_LVBMS_cellAndArcProtEnabled m4 : 19|1@1+ (1,0) [0|1] "" Vector__XXX
 SG_ VC_LVBMS_avgBrickVoltage m4 : 24|13@1+ (0.001,0) [0|8.19] "V" Vector__XXX
 SG_ VC_LVBMS_minBrickVoltage m4 : 40|13@1+ (0.001,0) [0|8.19] "V" Vector__XXX
 SG_ VC_LVBMS_minBrickVoltageIndex m4 : 56|8@1+ (1,0) [0|254] "" Vector__XXX

BO_ 1816 VC_LVBMS_statusLow: 8 VC
 SG_ VC_lvbmsStatusLowIndex M : 0|3@1+ (1,0) [0|7] "" Vector__XXX
 SG_ VC_LVBMS_SOC m0 : 3|10@1+ (0.1,0) [0|102.2] "%" Vector__XXX
 SG_ VC_LVBMS_SOE m0 : 16|7@1+ (1,0) [0|126] "%" Vector__XXX
 SG_ VC_LVBMS_SOH m0 : 24|7@1+ (1,0) [0|126] "%" Vector__XXX
 SG_ VC_LVBMS_CellOVLevel1 m0 : 31|1@1+ (1,0) [0|1] "" Vector__XXX
 SG_ VC_LVBMS_CellOVLevel2 m0 : 32|1@1+ (1,0) [0|1] "" Vector__XXX
 SG_ VC_LVBMS_CellOVLevel3 m0 : 33|1@1+ (1,0) [0|1] "" Vector__XXX
 SG_ VC_LVBMS_CellUVLevel1 m0 : 34|1@1+ (1,0) [0|1] "" Vector__XXX
 SG_ VC_LVBMS_CellUVLevel2 m0 : 35|1@1+ (1,0) [0|1] "" Vector__XXX
 SG_ VC_LVBMS_ModuleOTLevel1 m0 : 36|1@1+ (1,0) [0|1] "" Vector__XXX
 SG_ VC_LVBMS_PackOVLevel1 m0 : 37|1@1+ (1,0) [0|1] "" Vector__XXX
 SG_ VC_LVBMS_PackOVLevel2 m0 : 38|1@1+ (1,0) [0|1] "" Vector__XXX
 SG_ VC_LVBMS_DischrgOCLevel1 m0 : 39|1@1+ (1,0) [0|1] "" Vector__XXX
 SG_ VC_LVBMS_DischrgOCLevel2 m0 : 40|1@1+ (1,0) [0|1] "" Vector__XXX
 SG_ VC_LVBMS_ChrgOCLevel1 m0 : 41|1@1+ (1,0) [0|1] "" Vector__XXX
 SG_ VC_LVBMS_ChrgOCLevel2 m0 : 42|1@1+ (1,0) [0|1] "" Vector__XXX
 SG_ VC_LVBMS_MOSFETOTLevel1 m0 : 43|1@1+ (1,0) [0|1] "" Vector__XXX
 SG_ VC_LVBMS_KBValueLostFault m0 : 44|1@1+ (1,0) [0|1] "" Vector__XXX
 SG_ VC_LVBMS_BalanceCircuitFault m0 : 45|1@1+ (1,0) [0|1] "" Vector__XXX
 SG_ VC_LVBMS_MOSStateFault m0 : 46|1@1+ (1,0) [0|1] "" Vector__XXX
 SG_ VC_LVBMS_NTCTempDiffWarnLevel1 m0 : 47|1@1+ (1,0) [0|1] "" Vector__XXX
 SG_ VC_LVBMS_DeepDischargeFlag m0 : 48|1@1+ (1,0) [0|1] "" Vector__XXX
 SG_ VC_LVBMS_SamplingError m0 : 49|1@1+ (1,0) [0|1] "" Vector__XXX
 SG_ VC_LVBMS_MosfetStuckCloseError m0 : 50|1@1+ (1,0) [0|1] "" Vector__XXX
 SG_ VC_LVBMS_MosfetStuckOpenError m0 : 51|1@1+ (1,0) [0|1] "" Vector__XXX
 SG_ VC_LVBMS_AvgSleepCurrent m1 : 8|16@1+ (0.01,-200) [-200|455.34] "A" Vector__XXX
 SG_ VC_LVBMS_TimeSlept m1 : 24|24@1+ (1,0) [0|16777214] "min" Vector__XXX
 SG_ VC_LVBMS_SOP m1 : 48|8@1+ (20,0) [0|5080] "W" Vector__XXX
 SG_ VC_LVBMS_AhCharged m2 : 8|32@1+ (0.001,0) [0|4294967.294] "Ah" Vector__XXX
 SG_ VC_LVBMS_MinSleepCurrent m2 : 40|16@1+ (0.01,-200) [-200|455.34] "A" Vector__XXX
 SG_ VC_LVBMS_AhDischarged m3 : 8|32@1+ (0.001,0) [0|4294967.294] "Ah" Vector__XXX
 SG_ VC_LVBMS_MaxSleepCurrent m3 : 40|16@1+ (0.01,-200) [-200|455.34] "A" Vector__XXX
 SG_ VC_LVBMS_sumCellVoltageFiltered m4 : 8|16@1+ (0.001,0) [0|65.534] "V" Vector__XXX
 SG_ VC_LVBMS_maxCellSOC m4 : 24|10@1+ (0.1,0) [0|102.2] "%" Vector__XXX
 SG_ VC_LVBMS_minCellSOC m4 : 34|10@1+ (0.1,0) [0|102.2] "%" Vector__XXX
 SG_ VC_LVBMS_staticSOCCorrection m4 : 44|1@1+ (1,0) [0|1] "" Vector__XXX
 SG_ VC_LVBMS_dynamicSOCCorrection m4 : 45|1@1+ (1,0) [0|1] "" Vector__XXX
 SG_ VC_LVBMS_usableEnergyAvailable m4 : 48|12@1+ (1,0) [0|4000] "Wh" Vector__XXX
 SG_ VC_LVBMS_brakeTelltale m4 : 60|2@1+ (1,0) [0|3] "" Vector__XXX

BO_ 1089 VC_pcsInterface: 8 VC
 SG_ VC_pcsInterfaceMuxIndex M : 48|1@1+ (1,0) [0|1] "" Vector__XXX
 SG_ VC_pcsInterfaceCounter : 50|4@1+ (1,0) [0|15] "" Vector__XXX
 SG_ VC_pcsInterfaceChecksum : 56|8@1+ (1,0) [0|255] "" Vector__XXX
 SG_ VC_pcsLVVoltageTarget m0 : 0|13@1+ (0.01,0) [0|65.535] "V" Vector__XXX
 SG_ VC_pcsLVMinVoltageLimit m0 : 13|13@1+ (0.01,0) [0|65.535] "V" Vector__XXX
 SG_ VC_pcsLVMaxVoltageLimit m0 : 27|13@1+ (0.01,0) [0|65.535] "V" Vector__XXX
 SG_ VC_goodForPCSPowerCycle m0 : 46|1@1+ (1,0) [0|1] "" Vector__XXX
 SG_ VC_LVBatteryCannotSupportVehicle m0 : 47|1@1+ (1,0) [0|1] "" Vector__XXX
 SG_ VC_pcsResistanceFiltered m1 : 0|16@1+ (0.01,0) [0|655.34] "mOhm" Vector__XXX
 SG_ VC_pcsLVMaxDchrgCurrentLimit m1 : 16|12@1+ (0.1,0) [0|400] "A" Vector__XXX
 SG_ VC_defaultPcsLVVoltageTarget m1 : 28|13@1+ (0.01,0) [0|65.535] "V" Vector__XXX
 SG_ VC_lvHwProtSelfTestActive m1 : 41|1@1+ (1,0) [0|1] "" Vector__XXX
 SG_ VC_lvBatteryDischargeRequest m1 : 42|1@1+ (1,0) [0|1] "" Vector__XXX

BO_ 1091 VC_pcsManagement: 6 VC
 SG_ VC_pcsManagementChecksum : 0|8@1+ (1,0) [0|255] "" Vector__XXX
 SG_ VC_pcsManagementCounter : 8|4@1+ (1,0) [0|15] "" Vector__XXX
 SG_ VC_pcsManagementMuxIndex M : 12|1@1+ (1,0) [0|1] "" Vector__XXX
 SG_ VC_dcdcLVVoltageTargetMax m0 : 16|10@1+ (0.1,0) [0|102.3] "V" Vector__XXX
 SG_ VC_dcdcLVVoltageTargetMin m0 : 26|10@1+ (0.1,0) [0|102.3] "V" Vector__XXX
 SG_ VC_dcdcLVInputPowerLimit m0 : 36|8@1+ (50,0) [0|12750] "W" Vector__XXX

BO_ 1107 VEH_billing: 4 GTW
 SG_ VEH_pricebookId : 0|32@1+ (1,0) [0|4294967295] "" Vector__XXX

BO_ 1651 VEH_isoTpToEvse: 8 GTW
 SG_ VEH_isoTpToEvseData : 0|64@1+ (1,0) [0|1.84467440737e+19] "" Vector__XXX

BO_ 1029 VINbroadcast: 8 Vector__XXX
 SG_ VIN_muxID M : 0|8@1+ (1,0) [0|255] "" Vector__XXX
 SG_ VIN_char01 m16 : 40|8@1+ (1,0) [0|255] "" Vector__XXX
 SG_ VIN_char02 m16 : 48|8@1+ (1,0) [0|255] "" Vector__XXX
 SG_ VIN_char03 m16 : 56|8@1+ (1,0) [0|255] "" Vector__XXX
 SG_ VIN_char04 m17 : 8|8@1+ (1,0) [0|255] "" Vector__XXX
 SG_ VIN_char05 m17 : 16|8@1+ (1,0) [0|255] "" Vector__XXX
 SG_ VIN_char06 m17 : 24|8@1+ (1,0) [0|255] "" Vector__XXX
 SG_ VIN_char07 m17 : 32|8@1+ (1,0) [0|255] "" Vector__XXX
 SG_ VIN_char08 m17 : 40|8@1+ (1,0) [0|255] "" Vector__XXX
 SG_ VIN_char09 m17 : 48|8@1+ (1,0) [0|255] "" Vector__XXX
 SG_ VIN_char10 m17 : 56|8@1+ (1,0) [0|255] "" Vector__XXX
 SG_ VIN_char11 m18 : 8|8@1+ (1,0) [0|255] "" Vector__XXX
 SG_ VIN_char12 m18 : 16|8@1+ (1,0) [0|255] "" Vector__XXX
 SG_ VIN_char13 m18 : 24|8@1+ (1,0) [0|255] "" Vector__XXX
 SG_ VIN_char14 m18 : 32|8@1+ (1,0) [0|255] "" Vector__XXX
 SG_ VIN_char15 m18 : 40|8@1+ (1,0) [0|255] "" Vector__XXX
 SG_ VIN_char16 m18 : 48|8@1+ (1,0) [0|255] "" Vector__XXX
 SG_ VIN_char17 m18 : 56|8@1+ (1,0) [0|255] "" Vector__XXX

BO_TX_BU_ 1017 : VCSEC;
BO_TX_BU_ 825 : VCSEC;
BO_TX_BU_ 1817 : VCSEC;
BO_TX_BU_ 1824 : VCSEC;
BO_TX_BU_ 793 : VCSEC;
BO_TX_BU_ 505 : VCSEC;
BO_TX_BU_ 281 : VCSEC;
BO_TX_BU_ 1547 : VCSEC;
BO_TX_BU_ 1850 : VC;
BO_TX_BU_ 1655 : VC;
BO_TX_BU_ 1816 : VC;
BO_TX_BU_ 1089 : VC;
BO_TX_BU_ 1091 : VC;
BO_TX_BU_ 1107 : GTW;
BO_TX_BU_ 1651 : GTW;
CM_ BO_ 1017 "Vehicle security controller message: alert matrix; frame length from the layout, not yet observed on a vehicle bus";
CM_ SG_ 1017 VCSEC_matrixIndex "Vehicle security controller: matrix index";
CM_ SG_ 1017 VCSEC_a001_WatchdogReset "Vehicle security controller: a001 watchdog reset";
CM_ SG_ 1017 VCSEC_a002_PowerLossReset "Vehicle security controller: a002 power loss reset";
CM_ SG_ 1017 VCSEC_a003_SWAssertion "Vehicle security controller: a003 SW assertion";
CM_ SG_ 1017 VCSEC_a005_CANTXError "Vehicle security controller: a005 CANTX error";
CM_ SG_ 1017 VCSEC_a006_CANTX_cyclicError "Vehicle security controller: a006 CANTX cyclic error";
CM_ SG_ 1017 VCSEC_a010_ExtSupplyVoltError "Vehicle security controller: a010 ext supply volt error";
CM_ SG_ 1017 VCSEC_a012_CPUReset "Vehicle security controller: a012 CPU reset";
CM_ SG_ 1017 VCSEC_a013_AlertManagerFault "Vehicle security controller: a013 alert manager fault";
CM_ SG_ 1017 VCSEC_a015_NVMMError "Vehicle security controller: a015 NVMM error";
CM_ SG_ 1017 VCSEC_a016_NVMMRecordError "Vehicle security controller: a016 NVMM record error";
CM_ SG_ 1017 VCSEC_a017_NVMMStatusDbg "Vehicle security controller: a017 NVMM status dbg";
CM_ SG_ 1017 VCSEC_a021_TaskSchedulerError "Vehicle security controller: a021 task scheduler error";
CM_ SG_ 1017 VCSEC_a022_TaskInitError "Vehicle security controller: a022 task init error";
CM_ SG_ 1017 VCSEC_a029_CoreDump "Vehicle security controller: a029 core dump";
CM_ SG_ 1017 VCSEC_a030_ECULogUploadRequest "Vehicle security controller: a030 ECU log upload request";
CM_ SG_ 1017 VCSEC_a031_UDSActive "Vehicle security controller: a031 UDS active";
CM_ SG_ 1017 VCSEC_a041_HighCPULoad "Vehicle security controller: a041 high CPU load";
CM_ SG_ 1017 VCSEC_a042_HighStackUsage "Vehicle security controller: a042 high stack usage";
CM_ SG_ 1017 VCSEC_a043_Task1msError "Vehicle security controller: a043 task1ms error";
CM_ SG_ 1017 VCSEC_a044_Task10msError "Vehicle security controller: a044 task10ms error";
CM_ SG_ 1017 VCSEC_a045_Task100msError "Vehicle security controller: a045 task100ms error";
CM_ SG_ 1017 VCSEC_a046_Task1000msError "Vehicle security controller: a046 task1000ms error";
CM_ SG_ 1017 VCSEC_a057_HVP_MIA "Vehicle security controller: a057 HVP MIA";
CM_ SG_ 1017 VCSEC_a058_inputRHighSyncDebug "Vehicle security controller: a058 input r high sync debug";
CM_ SG_ 1017 VCSEC_a059_inputResistanceHigh "Vehicle security controller: a059 input resistance high";
CM_ SG_ 1017 VCSEC_a060_engineeringBuild "Vehicle security controller: a060 engineering build";
CM_ SG_ 1017 VCSEC_a061_XCPConnected "Vehicle security controller: a061 XCP connected";
CM_ SG_ 1017 VCSEC_a062_XCPWasConnected "Vehicle security controller: a062 XCP was connected";
CM_ SG_ 1017 VCSEC_a063_SwitchFault "Vehicle security controller: a063 switch fault";
CM_ SG_ 1017 VCSEC_a064_busSleepReqTimeout "Vehicle security controller: a064 bus sleep req timeout";
CM_ SG_ 1017 VCSEC_a082_VCRIGHT_IPC_MIA "Vehicle security controller: a082 VCRIGHT IPC MIA";
CM_ SG_ 1017 VCSEC_a083_VCLEFT_IPC_MIA "Vehicle security controller: a083 VCLEFT IPC MIA";
CM_ SG_ 1017 VCSEC_a084_TPMS_MIA "Vehicle security controller: a084 TPMS MIA";
CM_ SG_ 1017 VCSEC_a085_CCCM_MIA "Vehicle security controller: a085 CCCM MIA";
CM_ SG_ 1017 VCSEC_a086_VCBATT_MIA "Vehicle security controller: a086 VCBATT MIA";
CM_ SG_ 1017 VCSEC_a087_DIREL_MIA "Vehicle security controller: a087 DIREL MIA";
CM_ SG_ 1017 VCSEC_a088_DIRER_MIA "Vehicle security controller: a088 DIRER MIA";
CM_ SG_ 1017 VCSEC_a089_IBST_MIA "Vehicle security controller: a089 IBST MIA";
CM_ SG_ 1017 VCSEC_a090_APS_MIA "Vehicle security controller: a090 APS MIA";
CM_ SG_ 1017 VCSEC_a091_CMPD_MIA "Vehicle security controller: a091 CMPD MIA";
CM_ SG_ 1017 VCSEC_a092_VCSEATD_MIA "Vehicle security controller: a092 VCSEATD MIA";
CM_ SG_ 1017 VCSEC_a093_VCSEATP_MIA "Vehicle security controller: a093 VCSEATP MIA";
CM_ SG_ 1017 VCSEC_a094_EPAS3P_MIA "Vehicle security controller: a094 EPAS3 p MIA";
CM_ SG_ 1017 VCSEC_a095_CHG_MIA "Vehicle security controller: a095 CHG MIA";
CM_ SG_ 1017 VCSEC_a096_OCS1P_MIA "Vehicle security controller: a096 OCS1 p MIA";
CM_ SG_ 1017 VCSEC_a097_CMP_MIA "Vehicle security controller: a097 CMP MIA";
CM_ SG_ 1017 VCSEC_a098_DIR_MIA "Vehicle security controller: a098 DIR MIA";
CM_ SG_ 1017 VCSEC_a099_PARK_MIA "Vehicle security controller: a099 PARK MIA";
CM_ SG_ 1017 VCSEC_a100_CANbus_MIA "Vehicle security controller: a100 CA nbus MIA";
CM_ SG_ 1017 VCSEC_a101_PM_MIA "Vehicle security controller: a101 PM MIA";
CM_ SG_ 1017 VCSEC_a102_PTC_MIA "Vehicle security controller: a102 PTC MIA";
CM_ SG_ 1017 VCSEC_a103_CP_MIA "Vehicle security controller: a103 CP MIA";
CM_ SG_ 1017 VCSEC_a104_DAS_MIA "Vehicle security controller: a104 DAS MIA";
CM_ SG_ 1017 VCSEC_a105_TAS_MIA "Vehicle security controller: a105 TAS MIA";
CM_ SG_ 1017 VCSEC_a106_PCS_MIA "Vehicle security controller: a106 PCS MIA";
CM_ SG_ 1017 VCSEC_a107_BMS_MIA "Vehicle security controller: a107 BMS MIA";
CM_ SG_ 1017 VCSEC_a108_DIF_MIA "Vehicle security controller: a108 DIF MIA";
CM_ SG_ 1017 VCSEC_a109_RCM_MIA "Vehicle security controller: a109 RCM MIA";
CM_ SG_ 1017 VCSEC_a110_GTW_MIA "Vehicle security controller: a110 GTW MIA";
CM_ SG_ 1017 VCSEC_a111_EPBR_MIA "Vehicle security controller: a111 EPBR MIA";
CM_ SG_ 1017 VCSEC_a112_EPBL_MIA "Vehicle security controller: a112 EPBL MIA";
CM_ SG_ 1017 VCSEC_a113_UI_MIA "Vehicle security controller: a113 UI MIA";
CM_ SG_ 1017 VCSEC_a114_ESP_MIA "Vehicle security controller: a114 ESP MIA";
CM_ SG_ 1017 VCSEC_a115_VCSEC_MIA "Vehicle security controller: a115 VCSEC MIA";
CM_ SG_ 1017 VCSEC_a116_VCRIGHT_MIA "Vehicle security controller: a116 VCRIGHT MIA";
CM_ SG_ 1017 VCSEC_a117_VCLEFT_MIA "Vehicle security controller: a117 VCLEFT MIA";
CM_ SG_ 1017 VCSEC_a118_VCFRONT_MIA "Vehicle security controller: a118 VCFRONT MIA";
CM_ SG_ 1017 VCSEC_a119_SCCM_MIA "Vehicle security controller: a119 SCCM MIA";
CM_ SG_ 1017 VCSEC_a120_DI_DRIVE_MIA "Vehicle security controller: a120 DI DRIVE MIA";
CM_ SG_ 1017 VCSEC_a121_ICR_MIA "Vehicle security controller: a121 ICR MIA";
CM_ SG_ 1017 VCSEC_a133_alarmTriggered "Vehicle security controller: a133 alarm triggered";
CM_ SG_ 1017 VCSEC_a134_noVINLoaded "Vehicle security controller: a134 no VIN loaded";
CM_ SG_ 1017 VCSEC_a135_centerEndpointBusy "Vehicle security controller: a135 center endpoint busy";
CM_ SG_ 1017 VCSEC_a136_leftEndpointBusy "Vehicle security controller: a136 left endpoint busy";
CM_ SG_ 1017 VCSEC_a137_rightEndpointBusy "Vehicle security controller: a137 right endpoint busy";
CM_ SG_ 1017 VCSEC_a138_rearEndpointBusy "Vehicle security controller: a138 rear endpoint busy";
CM_ SG_ 1017 VCSEC_a140_nfcAuthentication "Vehicle security controller: a140 nfc authentication";
CM_ SG_ 1017 VCSEC_a141_tooFewKeysOnWhitelist "Vehicle security controller: a141 too few keys on whitelist";
CM_ SG_ 1017 VCSEC_a142_bleGattAlertC "Vehicle security controller: a142 ble gatt alert c";
CM_ SG_ 1017 VCSEC_a143_bleGattAlertL "Vehicle security controller: a143 ble gatt alert l";
CM_ SG_ 1017 VCSEC_a144_bleGattAlertR "Vehicle security controller: a144 ble gatt alert r";
CM_ SG_ 1017 VCSEC_a145_bleGattAlertRe "Vehicle security controller: a145 ble gatt alert re";
CM_ SG_ 1017 VCSEC_a147_protobufRXTimeout "Vehicle security controller: a147 protobuf RX timeout";
CM_ SG_ 1017 VCSEC_a148_keyWhitelistFull "Vehicle security controller: a148 key whitelist full";
CM_ SG_ 1017 VCSEC_a149_attrsWentMissingL "Vehicle security controller: a149 attrs went missing l";
CM_ SG_ 1017 VCSEC_a150_attrsWentMissingR "Vehicle security controller: a150 attrs went missing r";
CM_ SG_ 1017 VCSEC_a151_attrsWentMissingRe "Vehicle security controller: a151 attrs went missing re";
CM_ SG_ 1017 VCSEC_a153_srvcCmdTimeoutC "Vehicle security controller: a153 srvc cmd timeout c";
CM_ SG_ 1017 VCSEC_a154_srvcCmdTimeoutL "Vehicle security controller: a154 srvc cmd timeout l";
CM_ SG_ 1017 VCSEC_a155_srvcCmdTimeoutR "Vehicle security controller: a155 srvc cmd timeout r";
CM_ SG_ 1017 VCSEC_a156_srvcCmdTimeoutRe "Vehicle security controller: a156 srvc cmd timeout re";
CM_ SG_ 1017 VCSEC_a158_hciDebugC "Vehicle security controller: a158 hci debug c";
CM_ SG_ 1017 VCSEC_a159_hciDebugL "Vehicle security controller: a159 hci debug l";
CM_ SG_ 1017 VCSEC_a161_hciDebugR "Vehicle security controller: a161 hci debug r";
CM_ SG_ 1017 VCSEC_a162_hciDebugRe "Vehicle security controller: a162 hci debug re";
CM_ SG_ 1017 VCSEC_a164_attrsWentMissingC "Vehicle security controller: a164 attrs went missing c";
CM_ SG_ 1017 VCSEC_a165_ephemeralKeyGenerated "Vehicle security controller: a165 ephemeral key generated";
CM_ SG_ 1017 VCSEC_a166_BLECenterPowerCycled "Vehicle security controller: a166 BLE center power cycled";
CM_ SG_ 1017 VCSEC_a167_BLECenterSoftReset "Vehicle security controller: a167 BLE center soft reset";
CM_ SG_ 1017 VCSEC_a168_BLELeftSoftReset "Vehicle security controller: a168 BLE left soft reset";
CM_ SG_ 1017 VCSEC_a169_BLERightSoftReset "Vehicle security controller: a169 BLE right soft reset";
CM_ SG_ 1017 VCSEC_a170_BLERearSoftReset "Vehicle security controller: a170 BLE rear soft reset";
CM_ SG_ 1017 VCSEC_a172_BLEUnexpectedResetC "Vehicle security controller: a172 BLE unexpected reset c";
CM_ SG_ 1017 VCSEC_a173_BLEUnexpectedResetL "Vehicle security controller: a173 BLE unexpected reset l";
CM_ SG_ 1017 VCSEC_a174_BLEUnexpectedResetRi "Vehicle security controller: a174 BLE unexpected reset ri";
CM_ SG_ 1017 VCSEC_a175_BLEUnexpectedResetRe "Vehicle security controller: a175 BLE unexpected reset re";
CM_ SG_ 1017 VCSEC_a177_whitelistAddedKey "Vehicle security controller: a177 whitelist added key";
CM_ SG_ 1017 VCSEC_a178_whitelistRemovedKey "Vehicle security controller: a178 whitelist removed key";
CM_ SG_ 1017 VCSEC_a179_InfotainmentNotPaired "Vehicle security controller: a179 infotainment not paired";
CM_ SG_ 1017 VCSEC_a180_wlistRemovedPermissio "Vehicle security controller: a180 wlist removed permission";
CM_ SG_ 1017 VCSEC_a181_signedMessageFault "Vehicle security controller: a181 signed message fault";
CM_ SG_ 1017 VCSEC_a182_cryptoHighStackUsage "Vehicle security controller: a182 crypto high stack usage";
CM_ SG_ 1017 VCSEC_a183_centerEndpointRFMia "Vehicle security controller: a183 center endpoint RF mia";
CM_ SG_ 1017 VCSEC_a184_driverEndpointRFMia "Vehicle security controller: a184 driver endpoint RF mia";
CM_ SG_ 1017 VCSEC_a185_passengerEndpointRFMi "Vehicle security controller: a185 passenger endpoint RF mia";
CM_ SG_ 1017 VCSEC_a186_rearEndpointRFMia "Vehicle security controller: a186 rear endpoint RF mia";
CM_ SG_ 1017 VCSEC_a187_badConnectionDropped "Vehicle security controller: a187 bad connection dropped";
CM_ SG_ 1017 VCSEC_a188_protobufDecodeError "Vehicle security controller: a188 protobuf decode error";
CM_ SG_ 1017 VCSEC_a189_protoExpLengthTooLarg "Vehicle security controller: a189 proto exp length too large";
CM_ SG_ 1017 VCSEC_a190_protoTooManyBytes "Vehicle security controller: a190 proto too many bytes";
CM_ SG_ 1017 VCSEC_a191_macIDWlistingFailedC "Vehicle security controller: a191 mac ID wlisting failed c";
CM_ SG_ 1017 VCSEC_a192_macIDWlistingFailedL "Vehicle security controller: a192 mac ID wlisting failed l";
CM_ SG_ 1017 VCSEC_a193_macIDWlistingFailedRi "Vehicle security controller: a193 mac ID wlisting failed ri";
CM_ SG_ 1017 VCSEC_a194_macIDWlistingFailedRe "Vehicle security controller: a194 mac ID wlisting failed re";
CM_ SG_ 1017 VCSEC_a195_keyMissingInDrive "Vehicle security controller: a195 key missing in drive";
CM_ SG_ 1017 VCSEC_a196_protobufTXTimeout "Vehicle security controller: a196 protobuf TX timeout";
CM_ SG_ 1017 VCSEC_a197_indicationFault "Vehicle security controller: a197 indication fault";
CM_ SG_ 1017 VCSEC_a198_BPillarNFCReaderMIA "Vehicle security controller: a198 b pillar NFC reader MIA";
CM_ SG_ 1017 VCSEC_a199_CenterNFCReaderMIA "Vehicle security controller: a199 center NFC reader MIA";
CM_ SG_ 1017 VCSEC_a200_centerEndpointLostCom "Vehicle security controller: a200 center endpoint lost comm";
CM_ SG_ 1017 VCSEC_a201_leftEndpointLostComm "Vehicle security controller: a201 left endpoint lost comm";
CM_ SG_ 1017 VCSEC_a202_rightEndpointLostComm "Vehicle security controller: a202 right endpoint lost comm";
CM_ SG_ 1017 VCSEC_a203_rearEndpointLostComm "Vehicle security controller: a203 rear endpoint lost comm";
CM_ SG_ 1017 VCSEC_a204_SharedSecretsWritten "Vehicle security controller: a204 shared secrets written";
CM_ SG_ 1017 VCSEC_a205_MTUUpdateNotConfirmed "Vehicle security controller: a205 MTU update not confirmed";
CM_ SG_ 1017 VCSEC_a206_BLELeftAssertFailure "Vehicle security controller: a206 BLE left assert failure";
CM_ SG_ 1017 VCSEC_a207_BLERightAssertFailure "Vehicle security controller: a207 BLE right assert failure";
CM_ SG_ 1017 VCSEC_a208_BLERearAssertFailure "Vehicle security controller: a208 BLE rear assert failure";
CM_ SG_ 1017 VCSEC_a209_BLECenterAssertFailur "Vehicle security controller: a209 BLE center assert failure";
CM_ SG_ 1017 VCSEC_a210_keyDeviceBatteryLow "Vehicle security controller: a210 key device battery low";
CM_ SG_ 1017 VCSEC_a211_handlePullWithoutAuth "Vehicle security controller: a211 handle pull without auth";
CM_ SG_ 1017 VCSEC_a212_snifferRSSIMIA "Vehicle security controller: a212 sniffer RSSIMIA";
CM_ SG_ 1017 VCSEC_a213_gattTimeoutWithExptdC "Vehicle security controller: a213 gatt timeout with exptd count";
CM_ SG_ 1017 VCSEC_a214_gattServFalseWaitToBo "Vehicle security controller: a214 gatt serv false wait to boot";
CM_ SG_ 1017 VCSEC_a215_TPMSUnexpectedDisconn "Vehicle security controller: a215 TPMS unexpected disconnect sensor0";
CM_ SG_ 1017 VCSEC_a216_TPMSUnexpectedDisconn "Vehicle security controller: a216 TPMS unexpected disconnect sensor1";
CM_ SG_ 1017 VCSEC_a217_TPMSUnexpectedDisconn "Vehicle security controller: a217 TPMS unexpected disconnect sensor2";
CM_ SG_ 1017 VCSEC_a218_TPMSUnexpectedDisconn "Vehicle security controller: a218 TPMS unexpected disconnect sensor3";
CM_ SG_ 1017 VCSEC_a219_TPMSSensorPairingRemo "Vehicle security controller: a219 TPMS sensor pairing removed";
CM_ SG_ 1017 VCSEC_a220_TPMSSensorPairingNotC "Vehicle security controller: a220 TPMS sensor pairing not completed";
CM_ SG_ 1017 VCSEC_a221_TPMSSoftWarning "Vehicle security controller: a221 TPMS soft warning";
CM_ SG_ 1017 VCSEC_a222_TPMSSystemMalfunction "Vehicle security controller: a222 TPMS system malfunction";
CM_ SG_ 1017 VCSEC_a223_TPMSSensorConnectionC "Vehicle security controller: a223 TPMS sensor connection cycling0";
CM_ SG_ 1017 VCSEC_a224_TPMSSensorConnectionC "Vehicle security controller: a224 TPMS sensor connection cycling1";
CM_ SG_ 1017 VCSEC_a225_TPMSSensorConnectionC "Vehicle security controller: a225 TPMS sensor connection cycling2";
CM_ SG_ 1017 VCSEC_a226_TPMSSensorConnectionC "Vehicle security controller: a226 TPMS sensor connection cycling3";
CM_ SG_ 1017 VCSEC_a227_connectionWithoutLink "Vehicle security controller: a227 connection without link event";
CM_ SG_ 1017 VCSEC_a228_TPMSHardWarning "Vehicle security controller: a228 TPMS hard warning";
CM_ SG_ 1017 VCSEC_a235_presentWithoutHandleP "Vehicle security controller: a235 present without handle pull";
CM_ SG_ 1017 VCSEC_a236_keyIdentificationMaxA "Vehicle security controller: a236 key identification max attempt reached";
CM_ SG_ 1017 VCSEC_a237_keyNotReadyToReceiveI "Vehicle security controller: a237 key not ready to receive ID requests";
CM_ SG_ 1017 VCSEC_a238_TPMSLocationsUpdated "Vehicle security controller: a238 TPMS locations updated";
CM_ SG_ 1017 VCSEC_a239_TPMSIdleConnection "Vehicle security controller: a239 TPMS idle connection";
CM_ SG_ 1017 VCSEC_a240_noKeysPaired "Vehicle security controller: a240 no keys paired";
CM_ SG_ 1017 VCSEC_a241_TPMSUpdateStartedSens "Vehicle security controller: a241 TPMS update started sensor0";
CM_ SG_ 1017 VCSEC_a242_TPMSUpdateStartedSens "Vehicle security controller: a242 TPMS update started sensor1";
CM_ SG_ 1017 VCSEC_a243_TPMSUpdateStartedSens "Vehicle security controller: a243 TPMS update started sensor2";
CM_ SG_ 1017 VCSEC_a244_TPMSUpdateStartedSens "Vehicle security controller: a244 TPMS update started sensor3";
CM_ SG_ 1017 VCSEC_a245_TPMSUpdateInterrupted "Vehicle security controller: a245 TPMS update interrupted sensor0";
CM_ SG_ 1017 VCSEC_a246_TPMSUpdateInterrupted "Vehicle security controller: a246 TPMS update interrupted sensor1";
CM_ SG_ 1017 VCSEC_a247_TPMSUpdateInterrupted "Vehicle security controller: a247 TPMS update interrupted sensor2";
CM_ SG_ 1017 VCSEC_a248_TPMSUpdateInterrupted "Vehicle security controller: a248 TPMS update interrupted sensor3";
CM_ SG_ 1017 VCSEC_a249_TPMSUpdateCompleteSen "Vehicle security controller: a249 TPMS update complete sensor0";
CM_ SG_ 1017 VCSEC_a250_TPMSUpdateCompleteSen "Vehicle security controller: a250 TPMS update complete sensor1";
CM_ SG_ 1017 VCSEC_a251_TPMSUpdateCompleteSen "Vehicle security controller: a251 TPMS update complete sensor2";
CM_ SG_ 1017 VCSEC_a252_TPMSUpdateCompleteSen "Vehicle security controller: a252 TPMS update complete sensor3";
CM_ SG_ 1017 VCSEC_a254_whitelistUpdatedKey "Vehicle security controller: a254 whitelist updated key";
CM_ SG_ 1017 VCSEC_a255_wlistUpdatedPermissio "Vehicle security controller: a255 wlist updated permission";
CM_ SG_ 1017 VCSEC_a256_whitelistOperationFai "Vehicle security controller: a256 whitelist operation fail";
CM_ SG_ 1017 VCSEC_a257_connectedKeyIsExpirin "Vehicle security controller: a257 connected key is expiring";
CM_ SG_ 1017 VCSEC_a258_keyIsExpiring "Vehicle security controller: a258 key is expiring";
CM_ SG_ 1017 VCSEC_a260_prsntPhoneKeyDisconne "Vehicle security controller: a260 prsnt phone key disconnected";
CM_ SG_ 1017 VCSEC_a261_TPMSFactoryLearnActiv "Vehicle security controller: a261 TPMS factory learn active";
CM_ SG_ 1017 VCSEC_a262_flowControlBackedUp "Vehicle security controller: a262 flow control backed up";
CM_ SG_ 1017 VCSEC_a263_dispatchCouldNotBeCom "Vehicle security controller: a263 dispatch could not be completed";
CM_ SG_ 1017 VCSEC_a264_noOnePopulatedMessage "Vehicle security controller: a264 no one populated message";
CM_ SG_ 1017 VCSEC_a265_tooManyPopulatedMessa "Vehicle security controller: a265 too many populated message";
CM_ SG_ 1017 VCSEC_a266_TPMSSoftWarningFrontL "Vehicle security controller: a266 TPMS soft warning front left";
CM_ SG_ 1017 VCSEC_a267_TPMSSoftWarningFrontR "Vehicle security controller: a267 TPMS soft warning front right";
CM_ SG_ 1017 VCSEC_a268_TPMSSoftWarningRearLe "Vehicle security controller: a268 TPMS soft warning rear left";
CM_ SG_ 1017 VCSEC_a269_TPMSSoftWarningRearRi "Vehicle security controller: a269 TPMS soft warning rear right";
CM_ SG_ 1017 VCSEC_a270_TPMSHardWarningFrontL "Vehicle security controller: a270 TPMS hard warning front left";
CM_ SG_ 1017 VCSEC_a271_TPMSHardWarningFrontR "Vehicle security controller: a271 TPMS hard warning front right";
CM_ SG_ 1017 VCSEC_a272_TPMSHardWarningRearLe "Vehicle security controller: a272 TPMS hard warning rear left";
CM_ SG_ 1017 VCSEC_a273_TPMSHardWarningRearRi "Vehicle security controller: a273 TPMS hard warning rear right";
CM_ SG_ 1017 VCSEC_a274_handlePullWithoutAuth "Vehicle security controller: a274 handle pull without auth2";
CM_ SG_ 1017 VCSEC_a275_childSeatNotConnected "Vehicle security controller: a275 child seat not connected at start of drive";
CM_ SG_ 1017 VCSEC_a276_childSeatNotConnected "Vehicle security controller: a276 child seat not connected at end of drive";
CM_ SG_ 1017 VCSEC_a277_childSeatBatteryIsLow "Vehicle security controller: a277 child seat battery is low";
CM_ SG_ 1017 VCSEC_a280_TPMSLowBattery0 "Vehicle security controller: a280 TPMS low battery0";
CM_ SG_ 1017 VCSEC_a281_TPMSLowBattery1 "Vehicle security controller: a281 TPMS low battery1";
CM_ SG_ 1017 VCSEC_a282_TPMSLowBattery2 "Vehicle security controller: a282 TPMS low battery2";
CM_ SG_ 1017 VCSEC_a283_TPMSLowBattery3 "Vehicle security controller: a283 TPMS low battery3";
CM_ SG_ 1017 VCSEC_a300_scheduleItKeyAdded "Vehicle security controller: a300 schedule it key added";
CM_ SG_ 1017 VCSEC_a301_imposterDetected "Vehicle security controller: a301 imposter detected";
CM_ SG_ 1017 VCSEC_a302_unfused "Vehicle security controller: a302 unfused";
CM_ SG_ 1017 VCSEC_a303_KeyfobUpdateInterrupt "Vehicle security controller: a303 keyfob update interrupted";
CM_ SG_ 1017 VCSEC_a304_KeyfobUpdateComplete "Vehicle security controller: a304 keyfob update complete";
CM_ SG_ 1017 VCSEC_a305_ATTFlowControlViolate "Vehicle security controller: a305 ATT flow control violated c";
CM_ SG_ 1017 VCSEC_a306_KeyfobAdvReceivedWhil "Vehicle security controller: a306 keyfob adv received while connected";
CM_ SG_ 1017 VCSEC_a307_ATTTimeout "Vehicle security controller: a307 ATT timeout";
CM_ SG_ 1017 VCSEC_a308_NonConnectableAdvRece "Vehicle security controller: a308 non connectable adv received";
CM_ SG_ 1017 VCSEC_a309_serviceKeyConditionsN "Vehicle security controller: a309 service key conditions not met";
CM_ SG_ 1017 VCSEC_a310_chargePortFilterFalse "Vehicle security controller: a310 charge port filter false positive";
CM_ SG_ 1017 VCSEC_a311_moreThanThreeKeysPres "Vehicle security controller: a311 more than three keys present";
CM_ SG_ 1017 VCSEC_a312_unexpectedBLEDisconne "Vehicle security controller: a312 unexpected BLE disconnect";
CM_ SG_ 1017 VCSEC_a315_bleBondingEvent "Vehicle security controller: a315 ble bonding event";
CM_ SG_ 1017 VCSEC_a316_ltkRequestRejected "Vehicle security controller: a316 ltk request rejected";
CM_ SG_ 1017 VCSEC_a401_rearLeftEndpointLostC "Vehicle security controller: a401 rear left endpoint lost comm";
CM_ SG_ 1017 VCSEC_a402_rearRightEndpointLost "Vehicle security controller: a402 rear right endpoint lost comm";
CM_ SG_ 1017 VCSEC_a404_NFCCradleEndpointLost "Vehicle security controller: a404 NFC cradle endpoint lost comm";
CM_ SG_ 1017 VCSEC_a406_hciDebugRL "Vehicle security controller: a406 hci debug RL";
CM_ SG_ 1017 VCSEC_a407_hciDebugRR "Vehicle security controller: a407 hci debug RR";
CM_ SG_ 1017 VCSEC_a408_hciDebugNFCC "Vehicle security controller: a408 hci debug NFCC";
CM_ SG_ 1017 VCSEC_a411_leftRearEndpointBusy "Vehicle security controller: a411 left rear endpoint busy";
CM_ SG_ 1017 VCSEC_a412_rightRearEndpointBusy "Vehicle security controller: a412 right rear endpoint busy";
CM_ SG_ 1017 VCSEC_a413_NFCCradleEndpointBusy "Vehicle security controller: a413 NFC cradle endpoint busy";
CM_ SG_ 1017 VCSEC_a416_BLECradleNFCSoftReset "Vehicle security controller: a416 BLE cradle NFC soft reset";
CM_ SG_ 1017 VCSEC_a417_BLERearLeftSoftReset "Vehicle security controller: a417 BLE rear left soft reset";
CM_ SG_ 1017 VCSEC_a418_BLERearRightSoftReset "Vehicle security controller: a418 BLE rear right soft reset";
CM_ SG_ 1017 VCSEC_a420_BLEUnexpectedResetNFC "Vehicle security controller: a420 BLE unexpected reset NFC cradle";
CM_ SG_ 1017 VCSEC_a421_BLEUnexpectedResetRL "Vehicle security controller: a421 BLE unexpected reset RL";
CM_ SG_ 1017 VCSEC_a422_BLEUnexpectedResetRR "Vehicle security controller: a422 BLE unexpected reset RR";
CM_ SG_ 1017 VCSEC_a425_BLENFCCradleAssertFai "Vehicle security controller: a425 BLENFC cradle assert failure";
CM_ SG_ 1017 VCSEC_a426_BLERearLeftAssertFail "Vehicle security controller: a426 BLE rear left assert failure";
CM_ SG_ 1017 VCSEC_a427_BLERearRightAssertFai "Vehicle security controller: a427 BLE rear right assert failure";
CM_ SG_ 1017 VCSEC_a428_UWBCenterUpdateInterr "Vehicle security controller: a428 UWB center update interrupted";
CM_ SG_ 1017 VCSEC_a429_UWBLeftUpdateInterrup "Vehicle security controller: a429 UWB left update interrupted";
CM_ SG_ 1017 VCSEC_a430_UWBRightUpdateInterru "Vehicle security controller: a430 UWB right update interrupted";
CM_ SG_ 1017 VCSEC_a432_UWBRearLeftUpdateInte "Vehicle security controller: a432 UWB rear left update interrupted";
CM_ SG_ 1017 VCSEC_a433_UWBRearRightUpdateInt "Vehicle security controller: a433 UWB rear right update interrupted";
CM_ SG_ 1017 VCSEC_a434_UWBRadioConfigUpdated "Vehicle security controller: a434 UWB radio config updated";
CM_ SG_ 1017 VCSEC_a435_NFCCardPresentWhileCh "Vehicle security controller: a435 NFC card present while charging";
CM_ SG_ 1017 VCSEC_a436_uhfHWDoesNotMatchCoun "Vehicle security controller: a436 uhf HW does not match country";
CM_ SG_ 1017 VCSEC_a437_NearbyInteractionDebu "Vehicle security controller: a437 nearby interaction debug";
CM_ SG_ 1017 VCSEC_a438_UWBRearUpdateInterrup "Vehicle security controller: a438 UWB rear update interrupted";
CM_ SG_ 1017 VCSEC_a453_passiveDisabled "Vehicle security controller: a453 passive disabled";
CM_ SG_ 1017 VCSEC_a454_TPMSOverPressureWarni "Vehicle security controller: a454 TPMS over pressure warning";
CM_ SG_ 1017 VCSEC_a455_TPMSOverPressureWarni "Vehicle security controller: a455 TPMS over pressure warning front left";
CM_ SG_ 1017 VCSEC_a456_TPMSOverPressureWarni "Vehicle security controller: a456 TPMS over pressure warning front right";
CM_ SG_ 1017 VCSEC_a457_TPMSOverPressureWarni "Vehicle security controller: a457 TPMS over pressure warning rear left";
CM_ SG_ 1017 VCSEC_a458_TPMSOverPressureWarni "Vehicle security controller: a458 TPMS over pressure warning rear right";
CM_ SG_ 1017 VCSEC_a459_TPMSCertCheckFailedSe "Vehicle security controller: a459 TPMS cert check failed sensor0";
CM_ SG_ 1017 VCSEC_a460_TPMSCertCheckFailedSe "Vehicle security controller: a460 TPMS cert check failed sensor1";
CM_ SG_ 1017 VCSEC_a461_TPMSCertCheckFailedSe "Vehicle security controller: a461 TPMS cert check failed sensor2";
CM_ SG_ 1017 VCSEC_a462_TPMSCertCheckFailedSe "Vehicle security controller: a462 TPMS cert check failed sensor3";
CM_ SG_ 1017 VCSEC_a465_UWBRearLeftKeyVerific "Vehicle security controller: a465 UWB rear left key verification failure";
CM_ SG_ 1017 VCSEC_a466_UWBRearRightKeyVerifi "Vehicle security controller: a466 UWB rear right key verification failure";
CM_ SG_ 1017 VCSEC_a467_UWBCenterKeyVerificat "Vehicle security controller: a467 UWB center key verification failure";
CM_ SG_ 1017 VCSEC_a468_UWBRearKeyVerificatio "Vehicle security controller: a468 UWB rear key verification failure";
CM_ SG_ 1017 VCSEC_a469_UWBLeftKeyVerificatio "Vehicle security controller: a469 UWB left key verification failure";
CM_ SG_ 1017 VCSEC_a470_UWBRightKeyVerificati "Vehicle security controller: a470 UWB right key verification failure";
CM_ SG_ 1017 VCSEC_a472_peerRemovedInformatio "Vehicle security controller: a472 peer removed information";
CM_ SG_ 1017 VCSEC_a473_handlePullWithoutAuth "Vehicle security controller: a473 handle pull without auth3";
CM_ SG_ 1017 VCSEC_a474_handlePullWithoutAuth "Vehicle security controller: a474 handle pull without auth4";
CM_ SG_ 1017 VCSEC_a475_handlePullWithoutAuth "Vehicle security controller: a475 handle pull without auth5";
CM_ SG_ 1017 VCSEC_a476_handlePullWithoutAuth "Vehicle security controller: a476 handle pull without auth6";
CM_ SG_ 1017 VCSEC_a477_phoneStartedBonding "Vehicle security controller: a477 phone started bonding";
CM_ SG_ 1017 VCSEC_a478_handlePullWithoutAuth "Vehicle security controller: a478 handle pull without auth7";
CM_ SG_ 1017 VCSEC_a479_handlePullWithoutAuth "Vehicle security controller: a479 handle pull without auth NI state dev0";
CM_ SG_ 1017 VCSEC_a480_handlePullWithoutAuth "Vehicle security controller: a480 handle pull without auth NI state dev1";
CM_ SG_ 1017 VCSEC_a481_handlePullWithoutAuth "Vehicle security controller: a481 handle pull without auth NI state dev2";
CM_ SG_ 1017 VCSEC_a482_VINChanged "Vehicle security controller: a482 VIN changed";
CM_ SG_ 1017 VCSEC_a483_highThermalGradiantDe "Vehicle security controller: a483 high thermal gradiant detected";
CM_ SG_ 1017 VCSEC_a484_UWBLeftUpdateTriggere "Vehicle security controller: a484 UWB left update triggered";
CM_ SG_ 1017 VCSEC_a485_UWBCenterUpdateTrigge "Vehicle security controller: a485 UWB center update triggered";
CM_ SG_ 1017 VCSEC_a486_UWBRightUpdateTrigger "Vehicle security controller: a486 UWB right update triggered";
CM_ SG_ 1017 VCSEC_a487_unrecognizedProto "Vehicle security controller: a487 unrecognized proto";
CM_ SG_ 1017 VCSEC_a488_FiraRangingRejected "Vehicle security controller: a488 fira ranging rejected";
CM_ SG_ 1017 VCSEC_a489_UWBRearLeftUpdateTrig "Vehicle security controller: a489 UWB rear left update triggered";
CM_ SG_ 1017 VCSEC_a490_UWBRearRightUpdateTri "Vehicle security controller: a490 UWB rear right update triggered";
CM_ SG_ 1017 VCSEC_a494_UWBRearUpdateTriggere "Vehicle security controller: a494 UWB rear update triggered";
CM_ SG_ 1017 VCSEC_a495_handlePullWithoutAuth "Vehicle security controller: a495 handle pull without auth i OS";
CM_ SG_ 1017 VCSEC_a496_handlePullWithoutAuth "Vehicle security controller: a496 handle pull without auth android";
CM_ SG_ 1017 VCSEC_a497_incorrectEndpointInst "Vehicle security controller: a497 incorrect endpoint installation";
CM_ SG_ 1017 VCSEC_a498_TPMSFeature0Reached "Vehicle security controller: a498 TPMS feature0 reached";
CM_ SG_ 1017 VCSEC_a499_TPMSAssertFailure0 "Vehicle security controller: a499 TPMS assert failure0";
CM_ SG_ 1017 VCSEC_a500_TPMSAssertFailure1 "Vehicle security controller: a500 TPMS assert failure1";
CM_ SG_ 1017 VCSEC_a501_TPMSAssertFailure2 "Vehicle security controller: a501 TPMS assert failure2";
CM_ SG_ 1017 VCSEC_a502_TPMSAssertFailure3 "Vehicle security controller: a502 TPMS assert failure3";
CM_ SG_ 1017 VCSEC_a503_CANMsgMACVerification "Vehicle security controller: a503 CAN msg MAC verification failure";
CM_ SG_ 1017 VCSEC_a504_CANMsgMACVerification "Vehicle security controller: a504 CAN msg MAC verification key not provisioned";
CM_ SG_ 1017 VCSEC_a505_CANMsgMACVerification "Vehicle security controller: a505 CAN msg MAC verification key mismatch";
CM_ SG_ 1017 VCSEC_a510_watchKeyOffWrist "Vehicle security controller: a510 watch key off wrist";
CM_ SG_ 1017 VCSEC_a511_phoneKeyStationary "Vehicle security controller: a511 phone key stationary";
CM_ SG_ 1017 VCSEC_a513_TPMSConnectionStatsNo "Vehicle security controller: a513 TPMS connection stats not received0";
CM_ SG_ 1017 VCSEC_a514_TPMSConnectionStatsNo "Vehicle security controller: a514 TPMS connection stats not received1";
CM_ SG_ 1017 VCSEC_a515_TPMSConnectionStatsNo "Vehicle security controller: a515 TPMS connection stats not received2";
CM_ SG_ 1017 VCSEC_a516_TPMSConnectionStatsNo "Vehicle security controller: a516 TPMS connection stats not received3";
CM_ SG_ 1017 VCSEC_a517_TPMSOutOfRangePressur "Vehicle security controller: a517 TPMS out of range pressure received0";
CM_ SG_ 1017 VCSEC_a518_TPMSOutOfRangePressur "Vehicle security controller: a518 TPMS out of range pressure received1";
CM_ SG_ 1017 VCSEC_a519_TPMSOutOfRangePressur "Vehicle security controller: a519 TPMS out of range pressure received2";
CM_ SG_ 1017 VCSEC_a520_TPMSOutOfRangePressur "Vehicle security controller: a520 TPMS out of range pressure received3";
CM_ SG_ 1017 VCSEC_a521_TPMSSensorLowConfiden "Vehicle security controller: a521 TPMS sensor low confidence sensor localization0";
CM_ SG_ 1017 VCSEC_a522_TPMSSensorLowConfiden "Vehicle security controller: a522 TPMS sensor low confidence sensor localization1";
CM_ SG_ 1017 VCSEC_a523_TPMSSensorLowConfiden "Vehicle security controller: a523 TPMS sensor low confidence sensor localization2";
CM_ SG_ 1017 VCSEC_a524_TPMSSensorLowConfiden "Vehicle security controller: a524 TPMS sensor low confidence sensor localization3";
CM_ SG_ 1017 VCSEC_a525_TPMSLocalizationMulti "Vehicle security controller: a525 TPMS localization multiple sensors for position FL";
CM_ SG_ 1017 VCSEC_a526_TPMSLocalizationMulti "Vehicle security controller: a526 TPMS localization multiple sensors for position FR";
CM_ SG_ 1017 VCSEC_a527_TPMSLocalizationMulti "Vehicle security controller: a527 TPMS localization multiple sensors for position RL";
CM_ SG_ 1017 VCSEC_a528_TPMSLocalizationMulti "Vehicle security controller: a528 TPMS localization multiple sensors for position RR";
CM_ SG_ 1017 VCSEC_a529_TPMSTireServiceDetect "Vehicle security controller: a529 TPMS tire service detected";
CM_ SG_ 1017 VCSEC_a540_dummyAlertMax "Vehicle security controller: a540 dummy alert max";
CM_ BO_ 825 "Vehicle security controller message: authentication; frame length from the layout, not yet observed on a vehicle bus";
CM_ SG_ 825 VCSEC_BLEConnectionCounter "The number of devices connected to the host Bluetooth endpoint.";
CM_ SG_ 825 VCSEC_authRejectionReason "Reason it was rejected";
CM_ SG_ 825 VCSEC_IDRequested "Vehicle security controller: ID requested";
CM_ SG_ 825 VCSEC_operationMode "Reports the operation mode of the vehicle.";
CM_ SG_ 825 VCSEC_vehicleLockStatus "Lock status of the vehicle; raw 0 = signal not available (SNA)";
CM_ SG_ 825 VCSEC_authenticationStatus "Reports the vehicle authentication status.";
CM_ SG_ 825 VCSEC_chargePortLockStatus "Lock status of the charge port.";
CM_ SG_ 825 VCSEC_leftFrontLockStatus "Lock status of the left front door.";
CM_ SG_ 825 VCSEC_leftRearLockStatus "Lock status of the left rear door.";
CM_ SG_ 825 VCSEC_rightFrontLockStatus "Lock status of the right front door.";
CM_ SG_ 825 VCSEC_rightRearLockStatus "Lock status of right rear door.";
CM_ SG_ 825 VCSEC_trunkLockStatus "Lock status of the trunk.";
CM_ SG_ 825 VCSEC_lockRequestType "Reports the type of lock and unlock request received.";
CM_ SG_ 825 VCSEC_summonRequest "Reports the Summon request state; raw 5 = signal not available (SNA)";
CM_ SG_ 825 VCSEC_3rdPartyPLGRequest "Vehicle security controller: 3rd party PLG request; raw 3 = signal not available (SNA)";
CM_ SG_ 825 VCSEC_3rdPartyFrunkPLGRequest "Vehicle security controller: 3rd party frunk PLG request; raw 3 = signal not available (SNA)";
CM_ SG_ 825 VCSEC_MCUCommandType "Vehicle security controller: MCU command type";
CM_ SG_ 825 VCSEC_frunkLockStatus "Lock status of the frunk";
CM_ SG_ 825 VCSEC_usingModifiedMACAddress "Vehicle security controller: using modified MAC address";
CM_ SG_ 825 VCSEC_isKeyWithinSummonRange "Key is within the range of the car where summon can be enabled";
CM_ SG_ 825 VCSEC_isBLEDeviceWithinSummonRan "Indicates whether a Bluetooth Low Energy (BLE) device is within the range where Summon can be enabled.";
CM_ SG_ 825 VCSEC_alarmStatus "Reports the vehicle alarm status; raw 15 = signal not available (SNA)";
CM_ SG_ 825 VCSEC_serviceDiagnosticRequest "Vehicle security controller: service diagnostic request";
CM_ SG_ 825 VCSEC_immobilizerState "State of the immobilizer.";
CM_ SG_ 825 VCSEC_lockIndicationRequest "Requests to turn on vehicle turn indicators based on lock and unlock states; raw 0 = signal not available (SNA)";
CM_ SG_ 825 VCSEC_simpleLockStatus "Vehicle lock status with simplfied two states: lock and unlock; raw 0 = signal not available (SNA)";
CM_ SG_ 825 VCSEC_keyChannelIndexed "Vehicle security controller: key channel indexed; raw 15 = signal not available (SNA)";
CM_ SG_ 825 VCSEC_authRequested "An authentication request was sent from the security controller to the authentication device.";
CM_ SG_ 825 VCSEC_remoteStartActive "Indicates when a remote start request terminated by the Vehicle Security Controller (VCSEC) is active.";
CM_ SG_ 825 VCSEC_keyPairDesired "Vehicle security controller: key pair desired";
CM_ BO_ 1817 "Vehicle security controller message: debug100ms; frame length from the layout, not yet observed on a vehicle bus";
CM_ SG_ 1817 VCSEC_debug100msIndex "Vehicle security controller: debug100ms index";
CM_ SG_ 1817 VCSEC_walkAwayLockKeyState "Walk away lock key state of the vehicle";
CM_ SG_ 1817 VCSEC_thresholdOffsetVersion "Vehicle security controller: threshold offset version";
CM_ SG_ 1817 VCSEC_walkAwayLockState "Walk away lock state of the vehicle";
CM_ SG_ 1817 VCSEC_rssi0WLEntry "Whitelist entry of the rssi0 device";
CM_ SG_ 1817 VCSEC_endpointLayout "Vehicle security controller: endpoint layout";
CM_ SG_ 1817 VCSEC_rssi1WLEntry "Whitelist entry of the rssi1 device";
CM_ SG_ 1817 VCSEC_rssi2WLEntry "Whitelist entry of the rssi2 device";
CM_ SG_ 1817 VCSEC_walkUpUnlockState "Status of walk up unlock state";
CM_ SG_ 1817 VCSEC_algoHighThreshLeft "Vehicle security controller: algo high thresh left";
CM_ SG_ 1817 VCSEC_algoHighThreshRight "Vehicle security controller: algo high thresh right";
CM_ SG_ 1817 VCSEC_algoHighThreshCenter "Vehicle security controller: algo high thresh center";
CM_ SG_ 1817 VCSEC_pollingReason "Reason that the vehicle is currently polling for location";
CM_ SG_ 1817 VCSEC_numberOfPubKeysOnWhitelist "Number of public keys on keys whitelist.";
CM_ SG_ 1817 VCSEC_thermalDetectState "Reports the current state of thermal detection.";
CM_ SG_ 1817 VCSEC_chargeHandleMitigationActi "Vehicle security controller: charge handle mitigation active";
CM_ SG_ 1817 VCSEC_smartTrunkMitigatedKeyCoun "Vehicle security controller: smart trunk mitigated key count";
CM_ SG_ 1817 VCSEC_UWB3WLEntry "Whitelist entry of UWB3 device, phone that requested robotaxi and is not connected over BLE";
CM_ SG_ 1817 VCSEC_device0Offset "Vehicle security controller: device0 offset";
CM_ SG_ 1817 VCSEC_device1Offset "Vehicle security controller: device1 offset";
CM_ SG_ 1817 VCSEC_device2Offset "Vehicle security controller: device2 offset";
CM_ SG_ 1817 VCSEC_connection0BondingState "state of the GAP bonding statemachine";
CM_ SG_ 1817 VCSEC_connection1BondingState "state of the GAP bonding statemachine";
CM_ SG_ 1817 VCSEC_connection2BondingState "state of the GAP bonding statemachine";
CM_ SG_ 1817 VCSEC_connection0UWBAvailability "state of the UWB availability on the BLE connection";
CM_ SG_ 1817 VCSEC_connection1UWBAvailability "state of the UWB availability on the BLE connection";
CM_ SG_ 1817 VCSEC_connection2UWBAvailability "state of the UWB availability on the BLE connection";
CM_ SG_ 1817 VCSEC_NISessionStateCenter0 "Vehicle security controller: NI session state center0";
CM_ SG_ 1817 VCSEC_NISessionStateLeft0 "Vehicle security controller: NI session state left0";
CM_ SG_ 1817 VCSEC_NISessionStateRight0 "Vehicle security controller: NI session state right0";
CM_ SG_ 1817 VCSEC_NISessionStateRearLeft0 "Vehicle security controller: NI session state rear left0";
CM_ SG_ 1817 VCSEC_NISessionStateRearRight0 "Vehicle security controller: NI session state rear right0";
CM_ SG_ 1817 VCSEC_NISessionStateRear0 "Vehicle security controller: NI session state rear0";
CM_ SG_ 1817 VCSEC_NISessionStateCenter1 "Vehicle security controller: NI session state center1";
CM_ SG_ 1817 VCSEC_NISessionStateLeft1 "Vehicle security controller: NI session state left1";
CM_ SG_ 1817 VCSEC_NISessionStateRight1 "Vehicle security controller: NI session state right1";
CM_ SG_ 1817 VCSEC_NISessionStateRearLeft1 "Vehicle security controller: NI session state rear left1";
CM_ SG_ 1817 VCSEC_NISessionStateRearRight1 "Vehicle security controller: NI session state rear right1";
CM_ SG_ 1817 VCSEC_NISessionStateRear1 "Vehicle security controller: NI session state rear1";
CM_ SG_ 1817 VCSEC_NISessionStateCenter2 "Vehicle security controller: NI session state center2";
CM_ SG_ 1817 VCSEC_NISessionStateLeft2 "Vehicle security controller: NI session state left2";
CM_ SG_ 1817 VCSEC_NISessionStateRight2 "Vehicle security controller: NI session state right2";
CM_ SG_ 1817 VCSEC_NISessionStateRearLeft2 "Vehicle security controller: NI session state rear left2";
CM_ SG_ 1817 VCSEC_NISessionStateRearRight2 "Vehicle security controller: NI session state rear right2";
CM_ SG_ 1817 VCSEC_NISessionStateRear2 "Vehicle security controller: NI session state rear2";
CM_ SG_ 1817 VCSEC_NISessionStateLeft3 "Vehicle security controller: NI session state left3";
CM_ SG_ 1817 VCSEC_NISessionStateRight3 "Vehicle security controller: NI session state right3";
CM_ SG_ 1817 VCSEC_NISessionStateRearRight3 "Vehicle security controller: NI session state rear right3";
CM_ SG_ 1817 VCSEC_NISessionStateRearLeft3 "Vehicle security controller: NI session state rear left3";
CM_ SG_ 1817 VCSEC_NISessionStateCenter3 "Vehicle security controller: NI session state center3";
CM_ BO_ 1824 "Vehicle security controller message: ecu config; frame length from the layout, not yet observed on a vehicle bus";
CM_ SG_ 1824 VCSEC_ECUConfigCRC32 "Vehicle security controller: ECU config CRC32";
CM_ SG_ 1824 VCSEC_autoWriteConfig "Vehicle security controller: auto write config";
CM_ SG_ 1824 VCSEC_requestForConfig "Vehicle security controller: request for config";
CM_ BO_ 793 "Vehicle security controller message: info; frame length from the layout, not yet observed on a vehicle bus";
CM_ SG_ 793 VCSEC_infoIndex "Vehicle security controller: info index";
CM_ SG_ 793 VCSEC_infoBuildType "Vehicle security controller: info build type";
CM_ SG_ 793 VCSEC_infoBuildConfigId "Vehicle security controller: info build config id";
CM_ SG_ 793 VCSEC_infoHardwareId "Vehicle security controller: info hardware id";
CM_ SG_ 793 VCSEC_infoComponentId "Vehicle security controller: info component id";
CM_ SG_ 793 VCSEC_infoPcbaId "Vehicle security controller: info pcba id";
CM_ SG_ 793 VCSEC_infoAssemblyId "Vehicle security controller: info assembly id; raw 255 = signal not available (SNA)";
CM_ SG_ 793 VCSEC_infoUsageId "Vehicle security controller: info usage id";
CM_ SG_ 793 VCSEC_infoSubUsageId "Vehicle security controller: info sub usage id";
CM_ SG_ 793 VCSEC_infoAppCrc "Vehicle security controller: info app crc";
CM_ SG_ 793 VCSEC_infoSubcomponent1 "Vehicle security controller: info subcomponent1";
CM_ SG_ 793 VCSEC_infoAppGitHash "Vehicle security controller: info app git hash";
CM_ SG_ 793 VCSEC_infoBootGitHash "Vehicle security controller: info boot git hash";
CM_ SG_ 793 VCSEC_infoPlatformType "Vehicle security controller: info platform type";
CM_ SG_ 793 VCSEC_infoBootUdsProtoVersion "Vehicle security controller: info boot uds proto version";
CM_ SG_ 793 VCSEC_infoBootCrc "Vehicle security controller: info boot crc";
CM_ SG_ 793 VCSEC_infoSubcomponent2 "Vehicle security controller: info subcomponent2";
CM_ SG_ 793 VCSEC_infoSubcomponent3 "Vehicle security controller: info subcomponent3";
CM_ SG_ 793 VCSEC_infoSubcomponent4 "Vehicle security controller: info subcomponent4";
CM_ BO_ 505 "Vehicle security controller message: requests; frame length from the layout, not yet observed on a vehicle bus";
CM_ SG_ 505 VCSEC_chargePortRequest "Open and close requests of the charge port door; raw 3 = signal not available (SNA)";
CM_ SG_ 505 VCSEC_presentHandles "VCSEC command to present the handles. Applicable to Model S.";
CM_ SG_ 505 VCSEC_frontLeftClosureRequest "VCSEC command to present the front left door.";
CM_ SG_ 505 VCSEC_frontRightClosureRequest "VCSEC command to present the front right door.";
CM_ SG_ 505 VCSEC_rearLeftClosureRequest "open and close requests of the left rear door.";
CM_ SG_ 505 VCSEC_rearRightClosureRequest "open and close requests of the right rear door.";
CM_ SG_ 505 VCSEC_rearTrunkClosureRequest "VCSEC command to operate the rear trunk.";
CM_ SG_ 505 VCSEC_frontLeftRequestReason "VCSEC reason to present the front left door.";
CM_ SG_ 505 VCSEC_frontRightRequestReason "VCSEC reason to present the front right door.";
CM_ SG_ 505 VCSEC_rearLeftRequestReason "open and close request reason of the left rear door.";
CM_ SG_ 505 VCSEC_rearRightRequestReason "open and close request reason of the right rear door.";
CM_ SG_ 505 VCSEC_rearTrunkRequestReason "VCSEC reason for command to operate the rear trunk.";
CM_ SG_ 505 VCSEC_rdMapDumpRequested "Vehicle security controller: rd map dump requested";
CM_ SG_ 505 VCSEC_driveAttemptedWithoutAuth "Driver is attempting shift into drive wihout a key present";
CM_ SG_ 505 VCSEC_closeAllStatus "Vehicle security controller: close all status";
CM_ SG_ 505 VCSEC_snapshotRequested "Vehicle security controller: snapshot requested";
CM_ SG_ 505 VCSEC_chargeportRequestReason "VCSEC reason to open the chargeport door.";
CM_ SG_ 505 VCSEC_frontTrunkClosureRequest "VCSEC command to operate front trunk.";
CM_ SG_ 505 VCSEC_frontTrunkRequestReason "VCSEC reason to present the front left door.";
CM_ BO_ 281 "Vehicle security controller message: requests2; frame length from the layout, not yet observed on a vehicle bus";
CM_ SG_ 281 VCSEC_activeImmobilizerAuthLevel "The level of auth VCSEC will respond with when the Drive Inverter asks for auth";
CM_ SG_ 281 VCSEC_smartTrunkLightRequest "Request to signal indication lights for the smart trunk feature";
CM_ SG_ 281 VCSEC_smartTrunkSoundRequest "Vehicle security controller: smart trunk sound request";
CM_ SG_ 281 VCSEC_hvacRunScreenProtectOnly "Vehicle security controller: hvac run screen protect only";
CM_ SG_ 281 VCSEC_chargeHandleRequestModel "Vehicle security controller: charge handle request model";
CM_ SG_ 281 VCSEC_recoveryModeRequested "Vehicle security controller: recovery mode requested";
CM_ SG_ 281 VCSEC_infotainmentResetRequested "Vehicle security controller: infotainment reset requested";
CM_ SG_ 281 VCSEC_mobileToAPRequest "Vehicle security controller: mobile to AP request";
CM_ SG_ 281 VCSEC_riderKeyPresent "Vehicle security controller: rider key present";
CM_ BO_ 1547 "Vehicle security controller message: uds response; frame length from the layout, not yet observed on a vehicle bus";
CM_ SG_ 1547 VCSEC_udsResponseData "Vehicle security controller: uds response data";
CM_ BO_ 1850 "VC ECU message: LVBMS brick measurements; frame length from the layout, not yet observed on a vehicle bus";
CM_ SG_ 1850 VC_LVBMS_brickMeasurementsMultip "VC ECU: LVBMS brick measurements multiplexer";
CM_ SG_ 1850 VC_LVBMS_brickVoltage1 "Voltage of a low voltage battery brick; raw 8191 = signal not available (SNA)";
CM_ SG_ 1850 VC_LVBMS_brickVoltage2 "Voltage of a low voltage battery brick; raw 8191 = signal not available (SNA)";
CM_ SG_ 1850 VC_LVBMS_brickVoltage3 "Voltage of a low voltage battery brick; raw 8191 = signal not available (SNA)";
CM_ SG_ 1850 VC_LVBMS_brickVoltage4 "Voltage of a low voltage battery brick; raw 8191 = signal not available (SNA)";
CM_ SG_ 1850 VC_LVBMS_brickBalancingAh1 "Ah count of a low voltage battery brick; raw 16777215 = signal not available (SNA)";
CM_ SG_ 1850 VC_LVBMS_brickBalancingAh2 "Ah count of a low voltage battery brick; raw 16777215 = signal not available (SNA)";
CM_ SG_ 1850 VC_LVBMS_brickBalancingState1 "VC ECU: LVBMS brick balancing state1";
CM_ SG_ 1850 VC_LVBMS_brickBalancingState2 "VC ECU: LVBMS brick balancing state2";
CM_ SG_ 1850 VC_LVBMS_brickBalancingAh3 "Ah count of a low voltage battery brick; raw 16777215 = signal not available (SNA)";
CM_ SG_ 1850 VC_LVBMS_brickBalancingAh4 "Ah count of a low voltage battery brick; raw 16777215 = signal not available (SNA)";
CM_ SG_ 1850 VC_LVBMS_brickBalancingState3 "VC ECU: LVBMS brick balancing state3";
CM_ SG_ 1850 VC_LVBMS_brickBalancingState4 "VC ECU: LVBMS brick balancing state4";
CM_ BO_ 1655 "VC ECU message: LVBMS status high; frame length observed on a vehicle bus";
CM_ SG_ 1655 VC_lvbmsStatusHighIndex "VC ECU: lvbms status high index";
CM_ SG_ 1655 VC_LVBMS_packCurrent "Electrical current into the low voltage battery; raw 4194303 = signal not available (SNA)";
CM_ SG_ 1655 VC_LVBMS_packVoltage "Voltage of the low voltage battery; raw 65535 = signal not available (SNA)";
CM_ SG_ 1655 VC_LVBMS_packTemperature "Temperature of the low voltage battery; raw 511 = signal not available (SNA)";
CM_ SG_ 1655 VC_LVBMS_MOSTemperature "Temperature of the MOSFET on the low voltage battery; raw 4095 = signal not available (SNA)";
CM_ SG_ 1655 VC_LVBMS_sumCellVoltage "Sum of the cell voltage of the low voltage battery; raw 65535 = signal not available (SNA)";
CM_ SG_ 1655 VC_LVBMS_maxBrickVoltage "Maximum cell voltage in the low voltage battery; raw 8191 = signal not available (SNA)";
CM_ SG_ 1655 VC_LVBMS_maxBrickVoltageIndex "VC ECU: LVBMS max brick voltage index; raw 255 = signal not available (SNA)";
CM_ SG_ 1655 VC_totalLVLoadCurrent "Total LV load current of the vehicle.";
CM_ SG_ 1655 VC_LVPackChargeCurrentLimit "Charge current limit for the LV battery pack.";
CM_ SG_ 1655 VC_LVPackCurrent "Current of the LV battery pack.";
CM_ SG_ 1655 VC_LVBMS_estimatedPackOcv "VC ECU: LVBMS estimated pack ocv";
CM_ SG_ 1655 VC_LVBMS_voltageTarget "Voltage target of the LV battery; raw 65535 = signal not available (SNA)";
CM_ SG_ 1655 VC_LVBMS_currentTarget "Target current requested by the LV battery; raw 262143 = signal not available (SNA)";
CM_ SG_ 1655 VC_LVBMS_maxAllowedChargeCurrent "Maximum allowed charge current of the battery; raw 8191 = signal not available (SNA)";
CM_ SG_ 1655 VC_LVBMS_maxAllowedDischargeCurr "Maximum allowed discharge current of the battery; raw 8191 = signal not available (SNA)";
CM_ SG_ 1655 VC_LVBMS_MOSCommand "Current state of the MOS command to the LV battery";
CM_ SG_ 1655 VC_LVBMS_ClearErrorCntrCommand "VC ECU: LVBMS clear error cntr command";
CM_ SG_ 1655 VC_LVBMS_ClearHistoricFaultComma "VC ECU: LVBMS clear historic fault command";
CM_ SG_ 1655 VC_LVBMS_ResetLVBMSCommand "Reset command issued to LVBMS, commanded by VC";
CM_ SG_ 1655 VC_LVBMS_EnterHibernationCommand "VC ECU: LVBMS enter hibernation command";
CM_ SG_ 1655 VC_LVBMS_ECPAState "Current state of the E-CPA on the LV battery; raw 3 = signal not available (SNA)";
CM_ SG_ 1655 VC_LVBMS_MOSState "Current state of the MOS on the LV battery; raw 3 = signal not available (SNA)";
CM_ SG_ 1655 VC_LVBMS_VehicleState "VC ECU: LVBMS vehicle state";
CM_ SG_ 1655 VC_LVBMS_LINWakeDisabled "VC ECU: LVBMS LIN wake disabled";
CM_ SG_ 1655 VC_LVBMS_chargeType "VC ECU: LVBMS charge type; raw 4 = signal not available (SNA)";
CM_ SG_ 1655 VC_LVBMS_cellAndArcProtEnabled "Indicates whether the VC has commanded cell protections to be active";
CM_ SG_ 1655 VC_LVBMS_avgBrickVoltage "Average voltage of all cells in the low voltage battery; raw 8191 = signal not available (SNA)";
CM_ SG_ 1655 VC_LVBMS_minBrickVoltage "Minimum cell voltage in the low voltage battery; raw 8191 = signal not available (SNA)";
CM_ SG_ 1655 VC_LVBMS_minBrickVoltageIndex "VC ECU: LVBMS min brick voltage index; raw 255 = signal not available (SNA)";
CM_ BO_ 1816 "VC ECU message: LVBMS status low; frame length observed on a vehicle bus";
CM_ SG_ 1816 VC_lvbmsStatusLowIndex "VC ECU: lvbms status low index";
CM_ SG_ 1816 VC_LVBMS_SOC "State of charge reported by the low voltage battery sensor; raw 1023 = signal not available (SNA)";
CM_ SG_ 1816 VC_LVBMS_SOE "State of energy reported by the low voltage battery; raw 127 = signal not available (SNA)";
CM_ SG_ 1816 VC_LVBMS_SOH "State of health reported by the low voltage battery; raw 127 = signal not available (SNA)";
CM_ SG_ 1816 VC_LVBMS_CellOVLevel1 "VC ECU: LVBMS cell OV level1";
CM_ SG_ 1816 VC_LVBMS_CellOVLevel2 "VC ECU: LVBMS cell OV level2";
CM_ SG_ 1816 VC_LVBMS_CellOVLevel3 "VC ECU: LVBMS cell OV level3";
CM_ SG_ 1816 VC_LVBMS_CellUVLevel1 "VC ECU: LVBMS cell UV level1";
CM_ SG_ 1816 VC_LVBMS_CellUVLevel2 "VC ECU: LVBMS cell UV level2";
CM_ SG_ 1816 VC_LVBMS_ModuleOTLevel1 "VC ECU: LVBMS module OT level1";
CM_ SG_ 1816 VC_LVBMS_PackOVLevel1 "VC ECU: LVBMS pack OV level1";
CM_ SG_ 1816 VC_LVBMS_PackOVLevel2 "Pack Over Voltage Level 2 flag status";
CM_ SG_ 1816 VC_LVBMS_DischrgOCLevel1 "VC ECU: LVBMS dischrg OC level1";
CM_ SG_ 1816 VC_LVBMS_DischrgOCLevel2 "Discharge Over Current Level 2 flag status";
CM_ SG_ 1816 VC_LVBMS_ChrgOCLevel1 "VC ECU: LVBMS chrg OC level1";
CM_ SG_ 1816 VC_LVBMS_ChrgOCLevel2 "Charge Over Current Level 2 flag status";
CM_ SG_ 1816 VC_LVBMS_MOSFETOTLevel1 "VC ECU: LVBMS MOSFETOT level1";
CM_ SG_ 1816 VC_LVBMS_KBValueLostFault "Loss of CATL specific internal value flag status. Lost value causes offset in current sensor reading.";
CM_ SG_ 1816 VC_LVBMS_BalanceCircuitFault "Balance Circuit Fault flag status";
CM_ SG_ 1816 VC_LVBMS_MOSStateFault "Mosfet fault state flag status. Not to be confused with VC_LVBMS_MOSState.";
CM_ SG_ 1816 VC_LVBMS_NTCTempDiffWarnLevel1 "VC ECU: LVBMS NTC temp diff warn level1";
CM_ SG_ 1816 VC_LVBMS_DeepDischargeFlag "Deep Discharge flag status";
CM_ SG_ 1816 VC_LVBMS_SamplingError "Sampling Error flag status";
CM_ SG_ 1816 VC_LVBMS_MosfetStuckCloseError "Mosfet Stuck Close flag status";
CM_ SG_ 1816 VC_LVBMS_MosfetStuckOpenError "Mosfet Stuck Open flag status";
CM_ SG_ 1816 VC_LVBMS_AvgSleepCurrent "Low voltage battery average sleep current; raw 65535 = signal not available (SNA)";
CM_ SG_ 1816 VC_LVBMS_TimeSlept "VC ECU: LVBMS time slept; raw 16777215 = signal not available (SNA)";
CM_ SG_ 1816 VC_LVBMS_SOP "VC ECU: LVBMS SOP; raw 255 = signal not available (SNA)";
CM_ SG_ 1816 VC_LVBMS_AhCharged "Low voltage battery charge state; raw 4294967295 = signal not available (SNA)";
CM_ SG_ 1816 VC_LVBMS_MinSleepCurrent "VC ECU: LVBMS min sleep current; raw 65535 = signal not available (SNA)";
CM_ SG_ 1816 VC_LVBMS_AhDischarged "Low voltage battery charge state; raw 4294967295 = signal not available (SNA)";
CM_ SG_ 1816 VC_LVBMS_MaxSleepCurrent "VC ECU: LVBMS max sleep current; raw 65535 = signal not available (SNA)";
CM_ SG_ 1816 VC_LVBMS_sumCellVoltageFiltered "VC ECU: LVBMS sum cell voltage filtered; raw 65535 = signal not available (SNA)";
CM_ SG_ 1816 VC_LVBMS_maxCellSOC "SOC estimate of the highest SOC cell; raw 1023 = signal not available (SNA)";
CM_ SG_ 1816 VC_LVBMS_minCellSOC "SOC estimate of the lowest SOC cell; raw 1023 = signal not available (SNA)";
CM_ SG_ 1816 VC_LVBMS_staticSOCCorrection "Flag indicating the LVBMS is performing static SOC correction.";
CM_ SG_ 1816 VC_LVBMS_dynamicSOCCorrection "Flag indicating the LVBMS is performing dynamic SOC correction.";
CM_ SG_ 1816 VC_LVBMS_usableEnergyAvailable "Available/remaining usable pack energy; raw 4095 = signal not available (SNA)";
CM_ SG_ 1816 VC_LVBMS_brakeTelltale "VC ECU: LVBMS brake telltale";
CM_ BO_ 1089 "VC ECU message: pcs interface; frame length observed on a vehicle bus";
CM_ SG_ 1089 VC_pcsInterfaceMuxIndex "VC ECU: pcs interface mux index";
CM_ SG_ 1089 VC_pcsInterfaceCounter "VC ECU: pcs interface counter";
CM_ SG_ 1089 VC_pcsInterfaceChecksum "VC ECU: pcs interface checksum";
CM_ SG_ 1089 VC_pcsLVVoltageTarget "VC ECU: pcs LV voltage target";
CM_ SG_ 1089 VC_pcsLVMinVoltageLimit "VC ECU: pcs LV min voltage limit";
CM_ SG_ 1089 VC_pcsLVMaxVoltageLimit "VC ECU: pcs LV max voltage limit";
CM_ SG_ 1089 VC_goodForPCSPowerCycle "VC ECU: good for PCS power cycle";
CM_ SG_ 1089 VC_LVBatteryCannotSupportVehicle "VC ECU: LV battery cannot support vehicle";
CM_ SG_ 1089 VC_pcsResistanceFiltered "VC ECU: pcs resistance filtered; raw 65535 = signal not available (SNA)";
CM_ SG_ 1089 VC_pcsLVMaxDchrgCurrentLimit "VC ECU: pcs LV max dchrg current limit";
CM_ SG_ 1089 VC_defaultPcsLVVoltageTarget "VC ECU: default pcs LV voltage target";
CM_ SG_ 1089 VC_lvHwProtSelfTestActive "Reports whether Low Voltage (LV) Hardware (HW) protection self-tests are running or about to run due to a retry.";
CM_ SG_ 1089 VC_lvBatteryDischargeRequest "VC ECU: lv battery discharge request";
CM_ BO_ 1091 "VC ECU message: pcs management; frame length observed on a vehicle bus";
CM_ SG_ 1091 VC_pcsManagementChecksum "VC ECU: pcs management checksum";
CM_ SG_ 1091 VC_pcsManagementCounter "VC ECU: pcs management counter";
CM_ SG_ 1091 VC_pcsManagementMuxIndex "VC ECU: pcs management mux index";
CM_ SG_ 1091 VC_dcdcLVVoltageTargetMax "VC ECU: dcdc LV voltage target max";
CM_ SG_ 1091 VC_dcdcLVVoltageTargetMin "VC ECU: dcdc LV voltage target min";
CM_ SG_ 1091 VC_dcdcLVInputPowerLimit "VC ECU: dcdc LV input power limit";
CM_ BO_ 1107 "VEH ECU message: billing; forwarded onto this bus by the gateway; frame length observed on a vehicle bus";
CM_ SG_ 1107 VEH_pricebookId "VEH ECU: pricebook id";
CM_ BO_ 1651 "VEH ECU message: iso tp to evse; forwarded onto this bus by the gateway; frame length from the layout, not yet observed on a vehicle bus";
CM_ SG_ 1651 VEH_isoTpToEvseData "VEH ECU: iso tp to evse data";
CM_ BO_ 1029 "Vector__XXX ECU message: VI nbroadcast; frame length observed on a vehicle bus";
CM_ SG_ 1029 VIN_muxID "Page index of the vehicle identification number text (16 = characters 1-3, 17 = characters 4-10, 18 = characters 11-17)";
CM_ SG_ 1029 VIN_char01 "Vehicle identification number, character 1 (ASCII)";
CM_ SG_ 1029 VIN_char02 "Vehicle identification number, character 2 (ASCII)";
CM_ SG_ 1029 VIN_char03 "Vehicle identification number, character 3 (ASCII)";
CM_ SG_ 1029 VIN_char04 "Vehicle identification number, character 4 (ASCII)";
CM_ SG_ 1029 VIN_char05 "Vehicle identification number, character 5 (ASCII)";
CM_ SG_ 1029 VIN_char06 "Vehicle identification number, character 6 (ASCII)";
CM_ SG_ 1029 VIN_char07 "Vehicle identification number, character 7 (ASCII)";
CM_ SG_ 1029 VIN_char08 "Vehicle identification number, character 8 (ASCII)";
CM_ SG_ 1029 VIN_char09 "Vehicle identification number, character 9 (ASCII)";
CM_ SG_ 1029 VIN_char10 "Vehicle identification number, character 10 (ASCII)";
CM_ SG_ 1029 VIN_char11 "Vehicle identification number, character 11 (ASCII)";
CM_ SG_ 1029 VIN_char12 "Vehicle identification number, character 12 (ASCII)";
CM_ SG_ 1029 VIN_char13 "Vehicle identification number, character 13 (ASCII)";
CM_ SG_ 1029 VIN_char14 "Vehicle identification number, character 14 (ASCII)";
CM_ SG_ 1029 VIN_char15 "Vehicle identification number, character 15 (ASCII)";
CM_ SG_ 1029 VIN_char16 "Vehicle identification number, character 16 (ASCII)";
CM_ SG_ 1029 VIN_char17 "Vehicle identification number, character 17 (ASCII)";
BA_DEF_ BO_ "GenMsgCycleTime" INT 0 3600000;
BA_DEF_ BO_ "GenMsgSendType" ENUM "Cyclic","NotUsed","NotUsed","NotUsed","NotUsed","NotUsed","NotUsed","IfActive","NoMsgSendType","NotUsed";
BA_DEF_ BO_ "VFrameFormat" ENUM "StandardCAN","ExtendedCAN","reserved","J1939PG","reserved","reserved","reserved","reserved","reserved","reserved","reserved","reserved","reserved","reserved","StandardCAN_FD","ExtendedCAN_FD";
BA_DEF_ BO_ "CANFD_BRS" ENUM "0","1";
BA_DEF_ SG_ "GenSigSNA" STRING;
BA_DEF_ SG_ "SystemSignalLongSymbol" STRING;
BA_DEF_ SG_ "Confidence" ENUM "validated","plausible","layout-only","contradicted";
BA_DEF_DEF_ "GenMsgCycleTime" 0;
BA_DEF_DEF_ "GenMsgSendType" "NoMsgSendType";
BA_DEF_DEF_ "VFrameFormat" "StandardCAN";
BA_DEF_DEF_ "CANFD_BRS" "1";
BA_DEF_DEF_ "GenSigSNA" "";
BA_DEF_DEF_ "SystemSignalLongSymbol" "";
BA_DEF_DEF_ "Confidence" "layout-only";
BA_ "GenMsgCycleTime" BO_ 1017 100;
BA_ "GenMsgSendType" BO_ 1017 0;
BA_ "GenMsgCycleTime" BO_ 825 100;
BA_ "GenMsgSendType" BO_ 825 0;
BA_ "GenMsgCycleTime" BO_ 1817 50;
BA_ "GenMsgSendType" BO_ 1817 0;
BA_ "GenMsgCycleTime" BO_ 1824 10000;
BA_ "GenMsgSendType" BO_ 1824 0;
BA_ "GenMsgCycleTime" BO_ 793 1000;
BA_ "GenMsgSendType" BO_ 793 0;
BA_ "GenMsgCycleTime" BO_ 505 100;
BA_ "GenMsgSendType" BO_ 505 0;
BA_ "GenMsgCycleTime" BO_ 281 100;
BA_ "GenMsgSendType" BO_ 281 0;
BA_ "GenMsgCycleTime" BO_ 1850 1000;
BA_ "GenMsgSendType" BO_ 1850 0;
BA_ "GenMsgCycleTime" BO_ 1655 40;
BA_ "GenMsgSendType" BO_ 1655 0;
BA_ "GenMsgCycleTime" BO_ 1816 200;
BA_ "GenMsgSendType" BO_ 1816 0;
BA_ "GenMsgCycleTime" BO_ 1089 50;
BA_ "GenMsgSendType" BO_ 1089 0;
BA_ "GenMsgCycleTime" BO_ 1091 500;
BA_ "GenMsgSendType" BO_ 1091 0;
BA_ "GenMsgCycleTime" BO_ 1107 1000;
BA_ "GenMsgSendType" BO_ 1107 0;
BA_ "GenMsgCycleTime" BO_ 1029 1000;
BA_ "GenMsgSendType" BO_ 1029 0;
BA_ "Confidence" SG_ 1017 VCSEC_matrixIndex 0;
BA_ "SystemSignalLongSymbol" SG_ 1017 VCSEC_a180_wlistRemovedPermissio "VCSEC_a180_wlistRemovedPermission";
BA_ "SystemSignalLongSymbol" SG_ 1017 VCSEC_a185_passengerEndpointRFMi "VCSEC_a185_passengerEndpointRFMia";
BA_ "SystemSignalLongSymbol" SG_ 1017 VCSEC_a189_protoExpLengthTooLarg "VCSEC_a189_protoExpLengthTooLarge";
BA_ "SystemSignalLongSymbol" SG_ 1017 VCSEC_a200_centerEndpointLostCom "VCSEC_a200_centerEndpointLostComm";
BA_ "Confidence" SG_ 1017 VCSEC_a201_leftEndpointLostComm 0;
BA_ "Confidence" SG_ 1017 VCSEC_a202_rightEndpointLostComm 0;
BA_ "Confidence" SG_ 1017 VCSEC_a203_rearEndpointLostComm 0;
BA_ "SystemSignalLongSymbol" SG_ 1017 VCSEC_a209_BLECenterAssertFailur "VCSEC_a209_BLECenterAssertFailure";
BA_ "SystemSignalLongSymbol" SG_ 1017 VCSEC_a213_gattTimeoutWithExptdC "VCSEC_a213_gattTimeoutWithExptdCount";
BA_ "SystemSignalLongSymbol" SG_ 1017 VCSEC_a214_gattServFalseWaitToBo "VCSEC_a214_gattServFalseWaitToBoot";
BA_ "SystemSignalLongSymbol" SG_ 1017 VCSEC_a215_TPMSUnexpectedDisconn "VCSEC_a215_TPMSUnexpectedDisconnectSensor0";
BA_ "SystemSignalLongSymbol" SG_ 1017 VCSEC_a216_TPMSUnexpectedDisconn "VCSEC_a216_TPMSUnexpectedDisconnectSensor1";
BA_ "SystemSignalLongSymbol" SG_ 1017 VCSEC_a217_TPMSUnexpectedDisconn "VCSEC_a217_TPMSUnexpectedDisconnectSensor2";
BA_ "SystemSignalLongSymbol" SG_ 1017 VCSEC_a218_TPMSUnexpectedDisconn "VCSEC_a218_TPMSUnexpectedDisconnectSensor3";
BA_ "SystemSignalLongSymbol" SG_ 1017 VCSEC_a219_TPMSSensorPairingRemo "VCSEC_a219_TPMSSensorPairingRemoved";
BA_ "SystemSignalLongSymbol" SG_ 1017 VCSEC_a220_TPMSSensorPairingNotC "VCSEC_a220_TPMSSensorPairingNotCompleted";
BA_ "SystemSignalLongSymbol" SG_ 1017 VCSEC_a223_TPMSSensorConnectionC "VCSEC_a223_TPMSSensorConnectionCycling0";
BA_ "SystemSignalLongSymbol" SG_ 1017 VCSEC_a224_TPMSSensorConnectionC "VCSEC_a224_TPMSSensorConnectionCycling1";
BA_ "SystemSignalLongSymbol" SG_ 1017 VCSEC_a225_TPMSSensorConnectionC "VCSEC_a225_TPMSSensorConnectionCycling2";
BA_ "SystemSignalLongSymbol" SG_ 1017 VCSEC_a226_TPMSSensorConnectionC "VCSEC_a226_TPMSSensorConnectionCycling3";
BA_ "SystemSignalLongSymbol" SG_ 1017 VCSEC_a227_connectionWithoutLink "VCSEC_a227_connectionWithoutLinkEvent";
BA_ "SystemSignalLongSymbol" SG_ 1017 VCSEC_a235_presentWithoutHandleP "VCSEC_a235_presentWithoutHandlePull";
BA_ "SystemSignalLongSymbol" SG_ 1017 VCSEC_a236_keyIdentificationMaxA "VCSEC_a236_keyIdentificationMaxAttemptReached";
BA_ "SystemSignalLongSymbol" SG_ 1017 VCSEC_a237_keyNotReadyToReceiveI "VCSEC_a237_keyNotReadyToReceiveIDRequests";
BA_ "SystemSignalLongSymbol" SG_ 1017 VCSEC_a241_TPMSUpdateStartedSens "VCSEC_a241_TPMSUpdateStartedSensor0";
BA_ "SystemSignalLongSymbol" SG_ 1017 VCSEC_a242_TPMSUpdateStartedSens "VCSEC_a242_TPMSUpdateStartedSensor1";
BA_ "SystemSignalLongSymbol" SG_ 1017 VCSEC_a243_TPMSUpdateStartedSens "VCSEC_a243_TPMSUpdateStartedSensor2";
BA_ "SystemSignalLongSymbol" SG_ 1017 VCSEC_a244_TPMSUpdateStartedSens "VCSEC_a244_TPMSUpdateStartedSensor3";
BA_ "SystemSignalLongSymbol" SG_ 1017 VCSEC_a245_TPMSUpdateInterrupted "VCSEC_a245_TPMSUpdateInterruptedSensor0";
BA_ "SystemSignalLongSymbol" SG_ 1017 VCSEC_a246_TPMSUpdateInterrupted "VCSEC_a246_TPMSUpdateInterruptedSensor1";
BA_ "SystemSignalLongSymbol" SG_ 1017 VCSEC_a247_TPMSUpdateInterrupted "VCSEC_a247_TPMSUpdateInterruptedSensor2";
BA_ "SystemSignalLongSymbol" SG_ 1017 VCSEC_a248_TPMSUpdateInterrupted "VCSEC_a248_TPMSUpdateInterruptedSensor3";
BA_ "SystemSignalLongSymbol" SG_ 1017 VCSEC_a249_TPMSUpdateCompleteSen "VCSEC_a249_TPMSUpdateCompleteSensor0";
BA_ "SystemSignalLongSymbol" SG_ 1017 VCSEC_a250_TPMSUpdateCompleteSen "VCSEC_a250_TPMSUpdateCompleteSensor1";
BA_ "SystemSignalLongSymbol" SG_ 1017 VCSEC_a251_TPMSUpdateCompleteSen "VCSEC_a251_TPMSUpdateCompleteSensor2";
BA_ "SystemSignalLongSymbol" SG_ 1017 VCSEC_a252_TPMSUpdateCompleteSen "VCSEC_a252_TPMSUpdateCompleteSensor3";
BA_ "SystemSignalLongSymbol" SG_ 1017 VCSEC_a255_wlistUpdatedPermissio "VCSEC_a255_wlistUpdatedPermission";
BA_ "SystemSignalLongSymbol" SG_ 1017 VCSEC_a256_whitelistOperationFai "VCSEC_a256_whitelistOperationFail";
BA_ "SystemSignalLongSymbol" SG_ 1017 VCSEC_a257_connectedKeyIsExpirin "VCSEC_a257_connectedKeyIsExpiring";
BA_ "SystemSignalLongSymbol" SG_ 1017 VCSEC_a260_prsntPhoneKeyDisconne "VCSEC_a260_prsntPhoneKeyDisconnected";
BA_ "SystemSignalLongSymbol" SG_ 1017 VCSEC_a261_TPMSFactoryLearnActiv "VCSEC_a261_TPMSFactoryLearnActive";
BA_ "SystemSignalLongSymbol" SG_ 1017 VCSEC_a263_dispatchCouldNotBeCom "VCSEC_a263_dispatchCouldNotBeCompleted";
BA_ "SystemSignalLongSymbol" SG_ 1017 VCSEC_a265_tooManyPopulatedMessa "VCSEC_a265_tooManyPopulatedMessage";
BA_ "SystemSignalLongSymbol" SG_ 1017 VCSEC_a266_TPMSSoftWarningFrontL "VCSEC_a266_TPMSSoftWarningFrontLeft";
BA_ "SystemSignalLongSymbol" SG_ 1017 VCSEC_a267_TPMSSoftWarningFrontR "VCSEC_a267_TPMSSoftWarningFrontRight";
BA_ "SystemSignalLongSymbol" SG_ 1017 VCSEC_a268_TPMSSoftWarningRearLe "VCSEC_a268_TPMSSoftWarningRearLeft";
BA_ "SystemSignalLongSymbol" SG_ 1017 VCSEC_a269_TPMSSoftWarningRearRi "VCSEC_a269_TPMSSoftWarningRearRight";
BA_ "SystemSignalLongSymbol" SG_ 1017 VCSEC_a270_TPMSHardWarningFrontL "VCSEC_a270_TPMSHardWarningFrontLeft";
BA_ "SystemSignalLongSymbol" SG_ 1017 VCSEC_a271_TPMSHardWarningFrontR "VCSEC_a271_TPMSHardWarningFrontRight";
BA_ "SystemSignalLongSymbol" SG_ 1017 VCSEC_a272_TPMSHardWarningRearLe "VCSEC_a272_TPMSHardWarningRearLeft";
BA_ "SystemSignalLongSymbol" SG_ 1017 VCSEC_a273_TPMSHardWarningRearRi "VCSEC_a273_TPMSHardWarningRearRight";
BA_ "SystemSignalLongSymbol" SG_ 1017 VCSEC_a274_handlePullWithoutAuth "VCSEC_a274_handlePullWithoutAuth2";
BA_ "SystemSignalLongSymbol" SG_ 1017 VCSEC_a275_childSeatNotConnected "VCSEC_a275_childSeatNotConnectedAtStartOfDrive";
BA_ "SystemSignalLongSymbol" SG_ 1017 VCSEC_a276_childSeatNotConnected "VCSEC_a276_childSeatNotConnectedAtEndOfDrive";
BA_ "SystemSignalLongSymbol" SG_ 1017 VCSEC_a303_KeyfobUpdateInterrupt "VCSEC_a303_KeyfobUpdateInterrupted";
BA_ "SystemSignalLongSymbol" SG_ 1017 VCSEC_a305_ATTFlowControlViolate "VCSEC_a305_ATTFlowControlViolatedC";
BA_ "SystemSignalLongSymbol" SG_ 1017 VCSEC_a306_KeyfobAdvReceivedWhil "VCSEC_a306_KeyfobAdvReceivedWhileConnected";
BA_ "SystemSignalLongSymbol" SG_ 1017 VCSEC_a308_NonConnectableAdvRece "VCSEC_a308_NonConnectableAdvReceived";
BA_ "SystemSignalLongSymbol" SG_ 1017 VCSEC_a309_serviceKeyConditionsN "VCSEC_a309_serviceKeyConditionsNotMet";
BA_ "SystemSignalLongSymbol" SG_ 1017 VCSEC_a310_chargePortFilterFalse "VCSEC_a310_chargePortFilterFalsePositive";
BA_ "SystemSignalLongSymbol" SG_ 1017 VCSEC_a311_moreThanThreeKeysPres "VCSEC_a311_moreThanThreeKeysPresent";
BA_ "SystemSignalLongSymbol" SG_ 1017 VCSEC_a312_unexpectedBLEDisconne "VCSEC_a312_unexpectedBLEDisconnect";
BA_ "SystemSignalLongSymbol" SG_ 1017 VCSEC_a401_rearLeftEndpointLostC "VCSEC_a401_rearLeftEndpointLostComm";
BA_ "SystemSignalLongSymbol" SG_ 1017 VCSEC_a402_rearRightEndpointLost "VCSEC_a402_rearRightEndpointLostComm";
BA_ "SystemSignalLongSymbol" SG_ 1017 VCSEC_a404_NFCCradleEndpointLost "VCSEC_a404_NFCCradleEndpointLostComm";
BA_ "SystemSignalLongSymbol" SG_ 1017 VCSEC_a420_BLEUnexpectedResetNFC "VCSEC_a420_BLEUnexpectedResetNFCCradle";
BA_ "SystemSignalLongSymbol" SG_ 1017 VCSEC_a425_BLENFCCradleAssertFai "VCSEC_a425_BLENFCCradleAssertFailure";
BA_ "SystemSignalLongSymbol" SG_ 1017 VCSEC_a426_BLERearLeftAssertFail "VCSEC_a426_BLERearLeftAssertFailure";
BA_ "SystemSignalLongSymbol" SG_ 1017 VCSEC_a427_BLERearRightAssertFai "VCSEC_a427_BLERearRightAssertFailure";
BA_ "SystemSignalLongSymbol" SG_ 1017 VCSEC_a428_UWBCenterUpdateInterr "VCSEC_a428_UWBCenterUpdateInterrupted";
BA_ "SystemSignalLongSymbol" SG_ 1017 VCSEC_a429_UWBLeftUpdateInterrup "VCSEC_a429_UWBLeftUpdateInterrupted";
BA_ "SystemSignalLongSymbol" SG_ 1017 VCSEC_a430_UWBRightUpdateInterru "VCSEC_a430_UWBRightUpdateInterrupted";
BA_ "SystemSignalLongSymbol" SG_ 1017 VCSEC_a432_UWBRearLeftUpdateInte "VCSEC_a432_UWBRearLeftUpdateInterrupted";
BA_ "SystemSignalLongSymbol" SG_ 1017 VCSEC_a433_UWBRearRightUpdateInt "VCSEC_a433_UWBRearRightUpdateInterrupted";
BA_ "SystemSignalLongSymbol" SG_ 1017 VCSEC_a435_NFCCardPresentWhileCh "VCSEC_a435_NFCCardPresentWhileCharging";
BA_ "SystemSignalLongSymbol" SG_ 1017 VCSEC_a436_uhfHWDoesNotMatchCoun "VCSEC_a436_uhfHWDoesNotMatchCountry";
BA_ "SystemSignalLongSymbol" SG_ 1017 VCSEC_a437_NearbyInteractionDebu "VCSEC_a437_NearbyInteractionDebug";
BA_ "SystemSignalLongSymbol" SG_ 1017 VCSEC_a438_UWBRearUpdateInterrup "VCSEC_a438_UWBRearUpdateInterrupted";
BA_ "SystemSignalLongSymbol" SG_ 1017 VCSEC_a454_TPMSOverPressureWarni "VCSEC_a454_TPMSOverPressureWarning";
BA_ "SystemSignalLongSymbol" SG_ 1017 VCSEC_a455_TPMSOverPressureWarni "VCSEC_a455_TPMSOverPressureWarningFrontLeft";
BA_ "SystemSignalLongSymbol" SG_ 1017 VCSEC_a456_TPMSOverPressureWarni "VCSEC_a456_TPMSOverPressureWarningFrontRight";
BA_ "SystemSignalLongSymbol" SG_ 1017 VCSEC_a457_TPMSOverPressureWarni "VCSEC_a457_TPMSOverPressureWarningRearLeft";
BA_ "SystemSignalLongSymbol" SG_ 1017 VCSEC_a458_TPMSOverPressureWarni "VCSEC_a458_TPMSOverPressureWarningRearRight";
BA_ "SystemSignalLongSymbol" SG_ 1017 VCSEC_a459_TPMSCertCheckFailedSe "VCSEC_a459_TPMSCertCheckFailedSensor0";
BA_ "SystemSignalLongSymbol" SG_ 1017 VCSEC_a460_TPMSCertCheckFailedSe "VCSEC_a460_TPMSCertCheckFailedSensor1";
BA_ "SystemSignalLongSymbol" SG_ 1017 VCSEC_a461_TPMSCertCheckFailedSe "VCSEC_a461_TPMSCertCheckFailedSensor2";
BA_ "SystemSignalLongSymbol" SG_ 1017 VCSEC_a462_TPMSCertCheckFailedSe "VCSEC_a462_TPMSCertCheckFailedSensor3";
BA_ "SystemSignalLongSymbol" SG_ 1017 VCSEC_a465_UWBRearLeftKeyVerific "VCSEC_a465_UWBRearLeftKeyVerificationFailure";
BA_ "SystemSignalLongSymbol" SG_ 1017 VCSEC_a466_UWBRearRightKeyVerifi "VCSEC_a466_UWBRearRightKeyVerificationFailure";
BA_ "SystemSignalLongSymbol" SG_ 1017 VCSEC_a467_UWBCenterKeyVerificat "VCSEC_a467_UWBCenterKeyVerificationFailure";
BA_ "SystemSignalLongSymbol" SG_ 1017 VCSEC_a468_UWBRearKeyVerificatio "VCSEC_a468_UWBRearKeyVerificationFailure";
BA_ "SystemSignalLongSymbol" SG_ 1017 VCSEC_a469_UWBLeftKeyVerificatio "VCSEC_a469_UWBLeftKeyVerificationFailure";
BA_ "SystemSignalLongSymbol" SG_ 1017 VCSEC_a470_UWBRightKeyVerificati "VCSEC_a470_UWBRightKeyVerificationFailure";
BA_ "SystemSignalLongSymbol" SG_ 1017 VCSEC_a472_peerRemovedInformatio "VCSEC_a472_peerRemovedInformation";
BA_ "SystemSignalLongSymbol" SG_ 1017 VCSEC_a473_handlePullWithoutAuth "VCSEC_a473_handlePullWithoutAuth3";
BA_ "SystemSignalLongSymbol" SG_ 1017 VCSEC_a474_handlePullWithoutAuth "VCSEC_a474_handlePullWithoutAuth4";
BA_ "SystemSignalLongSymbol" SG_ 1017 VCSEC_a475_handlePullWithoutAuth "VCSEC_a475_handlePullWithoutAuth5";
BA_ "SystemSignalLongSymbol" SG_ 1017 VCSEC_a476_handlePullWithoutAuth "VCSEC_a476_handlePullWithoutAuth6";
BA_ "SystemSignalLongSymbol" SG_ 1017 VCSEC_a478_handlePullWithoutAuth "VCSEC_a478_handlePullWithoutAuth7";
BA_ "SystemSignalLongSymbol" SG_ 1017 VCSEC_a479_handlePullWithoutAuth "VCSEC_a479_handlePullWithoutAuthNIStateDev0";
BA_ "SystemSignalLongSymbol" SG_ 1017 VCSEC_a480_handlePullWithoutAuth "VCSEC_a480_handlePullWithoutAuthNIStateDev1";
BA_ "SystemSignalLongSymbol" SG_ 1017 VCSEC_a481_handlePullWithoutAuth "VCSEC_a481_handlePullWithoutAuthNIStateDev2";
BA_ "SystemSignalLongSymbol" SG_ 1017 VCSEC_a483_highThermalGradiantDe "VCSEC_a483_highThermalGradiantDetected";
BA_ "SystemSignalLongSymbol" SG_ 1017 VCSEC_a484_UWBLeftUpdateTriggere "VCSEC_a484_UWBLeftUpdateTriggered";
BA_ "SystemSignalLongSymbol" SG_ 1017 VCSEC_a485_UWBCenterUpdateTrigge "VCSEC_a485_UWBCenterUpdateTriggered";
BA_ "SystemSignalLongSymbol" SG_ 1017 VCSEC_a486_UWBRightUpdateTrigger "VCSEC_a486_UWBRightUpdateTriggered";
BA_ "SystemSignalLongSymbol" SG_ 1017 VCSEC_a489_UWBRearLeftUpdateTrig "VCSEC_a489_UWBRearLeftUpdateTriggered";
BA_ "SystemSignalLongSymbol" SG_ 1017 VCSEC_a490_UWBRearRightUpdateTri "VCSEC_a490_UWBRearRightUpdateTriggered";
BA_ "SystemSignalLongSymbol" SG_ 1017 VCSEC_a494_UWBRearUpdateTriggere "VCSEC_a494_UWBRearUpdateTriggered";
BA_ "SystemSignalLongSymbol" SG_ 1017 VCSEC_a495_handlePullWithoutAuth "VCSEC_a495_handlePullWithoutAuth_iOS";
BA_ "SystemSignalLongSymbol" SG_ 1017 VCSEC_a496_handlePullWithoutAuth "VCSEC_a496_handlePullWithoutAuth_Android";
BA_ "SystemSignalLongSymbol" SG_ 1017 VCSEC_a497_incorrectEndpointInst "VCSEC_a497_incorrectEndpointInstallation";
BA_ "SystemSignalLongSymbol" SG_ 1017 VCSEC_a503_CANMsgMACVerification "VCSEC_a503_CANMsgMACVerificationFailure";
BA_ "SystemSignalLongSymbol" SG_ 1017 VCSEC_a504_CANMsgMACVerification "VCSEC_a504_CANMsgMACVerificationKeyNotProvisioned";
BA_ "SystemSignalLongSymbol" SG_ 1017 VCSEC_a505_CANMsgMACVerification "VCSEC_a505_CANMsgMACVerificationKeyMismatch";
BA_ "SystemSignalLongSymbol" SG_ 1017 VCSEC_a513_TPMSConnectionStatsNo "VCSEC_a513_TPMSConnectionStatsNotReceived0";
BA_ "SystemSignalLongSymbol" SG_ 1017 VCSEC_a514_TPMSConnectionStatsNo "VCSEC_a514_TPMSConnectionStatsNotReceived1";
BA_ "SystemSignalLongSymbol" SG_ 1017 VCSEC_a515_TPMSConnectionStatsNo "VCSEC_a515_TPMSConnectionStatsNotReceived2";
BA_ "SystemSignalLongSymbol" SG_ 1017 VCSEC_a516_TPMSConnectionStatsNo "VCSEC_a516_TPMSConnectionStatsNotReceived3";
BA_ "SystemSignalLongSymbol" SG_ 1017 VCSEC_a517_TPMSOutOfRangePressur "VCSEC_a517_TPMSOutOfRangePressureReceived0";
BA_ "SystemSignalLongSymbol" SG_ 1017 VCSEC_a518_TPMSOutOfRangePressur "VCSEC_a518_TPMSOutOfRangePressureReceived1";
BA_ "SystemSignalLongSymbol" SG_ 1017 VCSEC_a519_TPMSOutOfRangePressur "VCSEC_a519_TPMSOutOfRangePressureReceived2";
BA_ "SystemSignalLongSymbol" SG_ 1017 VCSEC_a520_TPMSOutOfRangePressur "VCSEC_a520_TPMSOutOfRangePressureReceived3";
BA_ "SystemSignalLongSymbol" SG_ 1017 VCSEC_a521_TPMSSensorLowConfiden "VCSEC_a521_TPMSSensorLowConfidenceSensorLocalization0";
BA_ "SystemSignalLongSymbol" SG_ 1017 VCSEC_a522_TPMSSensorLowConfiden "VCSEC_a522_TPMSSensorLowConfidenceSensorLocalization1";
BA_ "SystemSignalLongSymbol" SG_ 1017 VCSEC_a523_TPMSSensorLowConfiden "VCSEC_a523_TPMSSensorLowConfidenceSensorLocalization2";
BA_ "SystemSignalLongSymbol" SG_ 1017 VCSEC_a524_TPMSSensorLowConfiden "VCSEC_a524_TPMSSensorLowConfidenceSensorLocalization3";
BA_ "SystemSignalLongSymbol" SG_ 1017 VCSEC_a525_TPMSLocalizationMulti "VCSEC_a525_TPMSLocalizationMultipleSensorsForPositionFL";
BA_ "SystemSignalLongSymbol" SG_ 1017 VCSEC_a526_TPMSLocalizationMulti "VCSEC_a526_TPMSLocalizationMultipleSensorsForPositionFR";
BA_ "SystemSignalLongSymbol" SG_ 1017 VCSEC_a527_TPMSLocalizationMulti "VCSEC_a527_TPMSLocalizationMultipleSensorsForPositionRL";
BA_ "SystemSignalLongSymbol" SG_ 1017 VCSEC_a528_TPMSLocalizationMulti "VCSEC_a528_TPMSLocalizationMultipleSensorsForPositionRR";
BA_ "SystemSignalLongSymbol" SG_ 1017 VCSEC_a529_TPMSTireServiceDetect "VCSEC_a529_TPMSTireServiceDetected";
BA_ "Confidence" SG_ 825 VCSEC_BLEConnectionCounter 0;
BA_ "Confidence" SG_ 825 VCSEC_authRejectionReason 0;
BA_ "Confidence" SG_ 825 VCSEC_IDRequested 0;
BA_ "Confidence" SG_ 825 VCSEC_operationMode 0;
BA_ "Confidence" SG_ 825 VCSEC_vehicleLockStatus 0;
BA_ "GenSigSNA" SG_ 825 VCSEC_vehicleLockStatus "0";
BA_ "Confidence" SG_ 825 VCSEC_authenticationStatus 0;
BA_ "Confidence" SG_ 825 VCSEC_chargePortLockStatus 0;
BA_ "Confidence" SG_ 825 VCSEC_leftFrontLockStatus 0;
BA_ "Confidence" SG_ 825 VCSEC_leftRearLockStatus 0;
BA_ "Confidence" SG_ 825 VCSEC_rightFrontLockStatus 0;
BA_ "Confidence" SG_ 825 VCSEC_rightRearLockStatus 0;
BA_ "Confidence" SG_ 825 VCSEC_trunkLockStatus 0;
BA_ "Confidence" SG_ 825 VCSEC_lockRequestType 0;
BA_ "Confidence" SG_ 825 VCSEC_summonRequest 0;
BA_ "GenSigSNA" SG_ 825 VCSEC_summonRequest "5";
BA_ "Confidence" SG_ 825 VCSEC_3rdPartyPLGRequest 0;
BA_ "GenSigSNA" SG_ 825 VCSEC_3rdPartyPLGRequest "3";
BA_ "Confidence" SG_ 825 VCSEC_3rdPartyFrunkPLGRequest 0;
BA_ "GenSigSNA" SG_ 825 VCSEC_3rdPartyFrunkPLGRequest "3";
BA_ "Confidence" SG_ 825 VCSEC_MCUCommandType 0;
BA_ "Confidence" SG_ 825 VCSEC_frunkLockStatus 0;
BA_ "Confidence" SG_ 825 VCSEC_usingModifiedMACAddress 0;
BA_ "Confidence" SG_ 825 VCSEC_isKeyWithinSummonRange 0;
BA_ "Confidence" SG_ 825 VCSEC_isBLEDeviceWithinSummonRan 0;
BA_ "SystemSignalLongSymbol" SG_ 825 VCSEC_isBLEDeviceWithinSummonRan "VCSEC_isBLEDeviceWithinSummonRange";
BA_ "Confidence" SG_ 825 VCSEC_alarmStatus 0;
BA_ "GenSigSNA" SG_ 825 VCSEC_alarmStatus "15";
BA_ "Confidence" SG_ 825 VCSEC_serviceDiagnosticRequest 0;
BA_ "Confidence" SG_ 825 VCSEC_immobilizerState 0;
BA_ "Confidence" SG_ 825 VCSEC_lockIndicationRequest 0;
BA_ "GenSigSNA" SG_ 825 VCSEC_lockIndicationRequest "0";
BA_ "Confidence" SG_ 825 VCSEC_simpleLockStatus 0;
BA_ "GenSigSNA" SG_ 825 VCSEC_simpleLockStatus "0";
BA_ "Confidence" SG_ 825 VCSEC_keyChannelIndexed 0;
BA_ "GenSigSNA" SG_ 825 VCSEC_keyChannelIndexed "15";
BA_ "Confidence" SG_ 825 VCSEC_authRequested 0;
BA_ "Confidence" SG_ 825 VCSEC_remoteStartActive 0;
BA_ "Confidence" SG_ 825 VCSEC_keyPairDesired 0;
BA_ "Confidence" SG_ 1817 VCSEC_debug100msIndex 1;
BA_ "Confidence" SG_ 1817 VCSEC_walkAwayLockKeyState 0;
BA_ "Confidence" SG_ 1817 VCSEC_thresholdOffsetVersion 0;
BA_ "Confidence" SG_ 1817 VCSEC_walkAwayLockState 0;
BA_ "Confidence" SG_ 1817 VCSEC_rssi0WLEntry 0;
BA_ "Confidence" SG_ 1817 VCSEC_endpointLayout 0;
BA_ "Confidence" SG_ 1817 VCSEC_rssi1WLEntry 0;
BA_ "Confidence" SG_ 1817 VCSEC_rssi2WLEntry 0;
BA_ "Confidence" SG_ 1817 VCSEC_walkUpUnlockState 0;
BA_ "Confidence" SG_ 1817 VCSEC_algoHighThreshLeft 0;
BA_ "Confidence" SG_ 1817 VCSEC_algoHighThreshRight 0;
BA_ "Confidence" SG_ 1817 VCSEC_algoHighThreshCenter 0;
BA_ "Confidence" SG_ 1817 VCSEC_pollingReason 0;
BA_ "Confidence" SG_ 1817 VCSEC_numberOfPubKeysOnWhitelist 0;
BA_ "Confidence" SG_ 1817 VCSEC_thermalDetectState 0;
BA_ "Confidence" SG_ 1817 VCSEC_chargeHandleMitigationActi 0;
BA_ "SystemSignalLongSymbol" SG_ 1817 VCSEC_chargeHandleMitigationActi "VCSEC_chargeHandleMitigationActive";
BA_ "Confidence" SG_ 1817 VCSEC_smartTrunkMitigatedKeyCoun 0;
BA_ "SystemSignalLongSymbol" SG_ 1817 VCSEC_smartTrunkMitigatedKeyCoun "VCSEC_smartTrunkMitigatedKeyCount";
BA_ "Confidence" SG_ 1817 VCSEC_UWB3WLEntry 0;
BA_ "Confidence" SG_ 1817 VCSEC_device0Offset 0;
BA_ "Confidence" SG_ 1817 VCSEC_device1Offset 0;
BA_ "Confidence" SG_ 1817 VCSEC_device2Offset 0;
BA_ "Confidence" SG_ 1817 VCSEC_connection0BondingState 0;
BA_ "Confidence" SG_ 1817 VCSEC_connection1BondingState 0;
BA_ "Confidence" SG_ 1817 VCSEC_connection2BondingState 0;
BA_ "Confidence" SG_ 1817 VCSEC_connection0UWBAvailability 0;
BA_ "Confidence" SG_ 1817 VCSEC_connection1UWBAvailability 0;
BA_ "Confidence" SG_ 1817 VCSEC_connection2UWBAvailability 0;
BA_ "Confidence" SG_ 1817 VCSEC_NISessionStateCenter0 0;
BA_ "Confidence" SG_ 1817 VCSEC_NISessionStateLeft0 0;
BA_ "Confidence" SG_ 1817 VCSEC_NISessionStateRight0 0;
BA_ "Confidence" SG_ 1817 VCSEC_NISessionStateRearLeft0 0;
BA_ "Confidence" SG_ 1817 VCSEC_NISessionStateRearRight0 0;
BA_ "Confidence" SG_ 1817 VCSEC_NISessionStateRear0 0;
BA_ "Confidence" SG_ 1817 VCSEC_NISessionStateCenter1 0;
BA_ "Confidence" SG_ 1817 VCSEC_NISessionStateLeft1 0;
BA_ "Confidence" SG_ 1817 VCSEC_NISessionStateRight1 0;
BA_ "Confidence" SG_ 1817 VCSEC_NISessionStateRearLeft1 0;
BA_ "Confidence" SG_ 1817 VCSEC_NISessionStateRearRight1 0;
BA_ "Confidence" SG_ 1817 VCSEC_NISessionStateRear1 0;
BA_ "Confidence" SG_ 1817 VCSEC_NISessionStateCenter2 0;
BA_ "Confidence" SG_ 1817 VCSEC_NISessionStateLeft2 0;
BA_ "Confidence" SG_ 1817 VCSEC_NISessionStateRight2 0;
BA_ "Confidence" SG_ 1817 VCSEC_NISessionStateRearLeft2 0;
BA_ "Confidence" SG_ 1817 VCSEC_NISessionStateRearRight2 0;
BA_ "Confidence" SG_ 1817 VCSEC_NISessionStateRear2 0;
BA_ "Confidence" SG_ 1817 VCSEC_NISessionStateLeft3 0;
BA_ "Confidence" SG_ 1817 VCSEC_NISessionStateRight3 0;
BA_ "Confidence" SG_ 1817 VCSEC_NISessionStateRearRight3 0;
BA_ "Confidence" SG_ 1817 VCSEC_NISessionStateRearLeft3 0;
BA_ "Confidence" SG_ 1817 VCSEC_NISessionStateCenter3 0;
BA_ "Confidence" SG_ 1824 VCSEC_ECUConfigCRC32 0;
BA_ "Confidence" SG_ 1824 VCSEC_autoWriteConfig 0;
BA_ "Confidence" SG_ 1824 VCSEC_requestForConfig 0;
BA_ "Confidence" SG_ 793 VCSEC_infoIndex 1;
BA_ "Confidence" SG_ 793 VCSEC_infoBuildType 0;
BA_ "Confidence" SG_ 793 VCSEC_infoBuildConfigId 0;
BA_ "Confidence" SG_ 793 VCSEC_infoHardwareId 0;
BA_ "Confidence" SG_ 793 VCSEC_infoComponentId 0;
BA_ "Confidence" SG_ 793 VCSEC_infoPcbaId 0;
BA_ "Confidence" SG_ 793 VCSEC_infoAssemblyId 0;
BA_ "GenSigSNA" SG_ 793 VCSEC_infoAssemblyId "255";
BA_ "Confidence" SG_ 793 VCSEC_infoUsageId 0;
BA_ "Confidence" SG_ 793 VCSEC_infoSubUsageId 0;
BA_ "Confidence" SG_ 793 VCSEC_infoAppCrc 0;
BA_ "Confidence" SG_ 793 VCSEC_infoSubcomponent1 0;
BA_ "Confidence" SG_ 793 VCSEC_infoAppGitHash 0;
BA_ "Confidence" SG_ 793 VCSEC_infoBootGitHash 0;
BA_ "Confidence" SG_ 793 VCSEC_infoPlatformType 0;
BA_ "Confidence" SG_ 793 VCSEC_infoBootUdsProtoVersion 0;
BA_ "Confidence" SG_ 793 VCSEC_infoBootCrc 0;
BA_ "Confidence" SG_ 793 VCSEC_infoSubcomponent2 0;
BA_ "Confidence" SG_ 793 VCSEC_infoSubcomponent3 0;
BA_ "Confidence" SG_ 793 VCSEC_infoSubcomponent4 0;
BA_ "Confidence" SG_ 505 VCSEC_chargePortRequest 0;
BA_ "GenSigSNA" SG_ 505 VCSEC_chargePortRequest "3";
BA_ "Confidence" SG_ 505 VCSEC_presentHandles 0;
BA_ "Confidence" SG_ 505 VCSEC_frontLeftClosureRequest 0;
BA_ "Confidence" SG_ 505 VCSEC_frontRightClosureRequest 0;
BA_ "Confidence" SG_ 505 VCSEC_rearLeftClosureRequest 0;
BA_ "Confidence" SG_ 505 VCSEC_rearRightClosureRequest 0;
BA_ "Confidence" SG_ 505 VCSEC_rearTrunkClosureRequest 0;
BA_ "Confidence" SG_ 505 VCSEC_frontLeftRequestReason 0;
BA_ "Confidence" SG_ 505 VCSEC_frontRightRequestReason 0;
BA_ "Confidence" SG_ 505 VCSEC_rearLeftRequestReason 0;
BA_ "Confidence" SG_ 505 VCSEC_rearRightRequestReason 0;
BA_ "Confidence" SG_ 505 VCSEC_rearTrunkRequestReason 0;
BA_ "Confidence" SG_ 505 VCSEC_rdMapDumpRequested 0;
BA_ "Confidence" SG_ 505 VCSEC_driveAttemptedWithoutAuth 0;
BA_ "Confidence" SG_ 505 VCSEC_closeAllStatus 0;
BA_ "Confidence" SG_ 505 VCSEC_snapshotRequested 0;
BA_ "Confidence" SG_ 505 VCSEC_chargeportRequestReason 0;
BA_ "Confidence" SG_ 505 VCSEC_frontTrunkClosureRequest 0;
BA_ "Confidence" SG_ 505 VCSEC_frontTrunkRequestReason 0;
BA_ "Confidence" SG_ 281 VCSEC_activeImmobilizerAuthLevel 0;
BA_ "Confidence" SG_ 281 VCSEC_smartTrunkLightRequest 0;
BA_ "Confidence" SG_ 281 VCSEC_smartTrunkSoundRequest 0;
BA_ "Confidence" SG_ 281 VCSEC_hvacRunScreenProtectOnly 0;
BA_ "Confidence" SG_ 281 VCSEC_chargeHandleRequestModel 0;
BA_ "Confidence" SG_ 281 VCSEC_recoveryModeRequested 0;
BA_ "Confidence" SG_ 281 VCSEC_infotainmentResetRequested 0;
BA_ "Confidence" SG_ 281 VCSEC_mobileToAPRequest 0;
BA_ "Confidence" SG_ 281 VCSEC_riderKeyPresent 0;
BA_ "Confidence" SG_ 1547 VCSEC_udsResponseData 1;
BA_ "Confidence" SG_ 1850 VC_LVBMS_brickMeasurementsMultip 1;
BA_ "SystemSignalLongSymbol" SG_ 1850 VC_LVBMS_brickMeasurementsMultip "VC_LVBMS_brickMeasurementsMultiplexer";
BA_ "Confidence" SG_ 1850 VC_LVBMS_brickVoltage1 0;
BA_ "GenSigSNA" SG_ 1850 VC_LVBMS_brickVoltage1 "8191";
BA_ "Confidence" SG_ 1850 VC_LVBMS_brickVoltage2 0;
BA_ "GenSigSNA" SG_ 1850 VC_LVBMS_brickVoltage2 "8191";
BA_ "Confidence" SG_ 1850 VC_LVBMS_brickVoltage3 0;
BA_ "GenSigSNA" SG_ 1850 VC_LVBMS_brickVoltage3 "8191";
BA_ "Confidence" SG_ 1850 VC_LVBMS_brickVoltage4 0;
BA_ "GenSigSNA" SG_ 1850 VC_LVBMS_brickVoltage4 "8191";
BA_ "Confidence" SG_ 1850 VC_LVBMS_brickBalancingAh1 0;
BA_ "GenSigSNA" SG_ 1850 VC_LVBMS_brickBalancingAh1 "16777215";
BA_ "Confidence" SG_ 1850 VC_LVBMS_brickBalancingAh2 0;
BA_ "GenSigSNA" SG_ 1850 VC_LVBMS_brickBalancingAh2 "16777215";
BA_ "Confidence" SG_ 1850 VC_LVBMS_brickBalancingState1 0;
BA_ "Confidence" SG_ 1850 VC_LVBMS_brickBalancingState2 0;
BA_ "Confidence" SG_ 1850 VC_LVBMS_brickBalancingAh3 0;
BA_ "GenSigSNA" SG_ 1850 VC_LVBMS_brickBalancingAh3 "16777215";
BA_ "Confidence" SG_ 1850 VC_LVBMS_brickBalancingAh4 0;
BA_ "GenSigSNA" SG_ 1850 VC_LVBMS_brickBalancingAh4 "16777215";
BA_ "Confidence" SG_ 1850 VC_LVBMS_brickBalancingState3 0;
BA_ "Confidence" SG_ 1850 VC_LVBMS_brickBalancingState4 0;
BA_ "Confidence" SG_ 1655 VC_lvbmsStatusHighIndex 0;
BA_ "Confidence" SG_ 1655 VC_LVBMS_packCurrent 0;
BA_ "GenSigSNA" SG_ 1655 VC_LVBMS_packCurrent "4194303";
BA_ "Confidence" SG_ 1655 VC_LVBMS_packVoltage 0;
BA_ "GenSigSNA" SG_ 1655 VC_LVBMS_packVoltage "65535";
BA_ "Confidence" SG_ 1655 VC_LVBMS_packTemperature 0;
BA_ "GenSigSNA" SG_ 1655 VC_LVBMS_packTemperature "511";
BA_ "Confidence" SG_ 1655 VC_LVBMS_MOSTemperature 0;
BA_ "GenSigSNA" SG_ 1655 VC_LVBMS_MOSTemperature "4095";
BA_ "Confidence" SG_ 1655 VC_LVBMS_sumCellVoltage 0;
BA_ "GenSigSNA" SG_ 1655 VC_LVBMS_sumCellVoltage "65535";
BA_ "Confidence" SG_ 1655 VC_LVBMS_maxBrickVoltage 0;
BA_ "GenSigSNA" SG_ 1655 VC_LVBMS_maxBrickVoltage "8191";
BA_ "Confidence" SG_ 1655 VC_LVBMS_maxBrickVoltageIndex 0;
BA_ "GenSigSNA" SG_ 1655 VC_LVBMS_maxBrickVoltageIndex "255";
BA_ "Confidence" SG_ 1655 VC_totalLVLoadCurrent 0;
BA_ "Confidence" SG_ 1655 VC_LVPackChargeCurrentLimit 0;
BA_ "Confidence" SG_ 1655 VC_LVPackCurrent 0;
BA_ "Confidence" SG_ 1655 VC_LVBMS_estimatedPackOcv 0;
BA_ "Confidence" SG_ 1655 VC_LVBMS_voltageTarget 0;
BA_ "GenSigSNA" SG_ 1655 VC_LVBMS_voltageTarget "65535";
BA_ "Confidence" SG_ 1655 VC_LVBMS_currentTarget 0;
BA_ "GenSigSNA" SG_ 1655 VC_LVBMS_currentTarget "262143";
BA_ "Confidence" SG_ 1655 VC_LVBMS_maxAllowedChargeCurrent 0;
BA_ "GenSigSNA" SG_ 1655 VC_LVBMS_maxAllowedChargeCurrent "8191";
BA_ "Confidence" SG_ 1655 VC_LVBMS_maxAllowedDischargeCurr 0;
BA_ "GenSigSNA" SG_ 1655 VC_LVBMS_maxAllowedDischargeCurr "8191";
BA_ "SystemSignalLongSymbol" SG_ 1655 VC_LVBMS_maxAllowedDischargeCurr "VC_LVBMS_maxAllowedDischargeCurrent";
BA_ "Confidence" SG_ 1655 VC_LVBMS_MOSCommand 0;
BA_ "Confidence" SG_ 1655 VC_LVBMS_ClearErrorCntrCommand 0;
BA_ "Confidence" SG_ 1655 VC_LVBMS_ClearHistoricFaultComma 0;
BA_ "SystemSignalLongSymbol" SG_ 1655 VC_LVBMS_ClearHistoricFaultComma "VC_LVBMS_ClearHistoricFaultCommand";
BA_ "Confidence" SG_ 1655 VC_LVBMS_ResetLVBMSCommand 0;
BA_ "Confidence" SG_ 1655 VC_LVBMS_EnterHibernationCommand 0;
BA_ "Confidence" SG_ 1655 VC_LVBMS_ECPAState 0;
BA_ "GenSigSNA" SG_ 1655 VC_LVBMS_ECPAState "3";
BA_ "Confidence" SG_ 1655 VC_LVBMS_MOSState 0;
BA_ "GenSigSNA" SG_ 1655 VC_LVBMS_MOSState "3";
BA_ "Confidence" SG_ 1655 VC_LVBMS_VehicleState 0;
BA_ "Confidence" SG_ 1655 VC_LVBMS_LINWakeDisabled 0;
BA_ "Confidence" SG_ 1655 VC_LVBMS_chargeType 0;
BA_ "GenSigSNA" SG_ 1655 VC_LVBMS_chargeType "4";
BA_ "Confidence" SG_ 1655 VC_LVBMS_cellAndArcProtEnabled 0;
BA_ "Confidence" SG_ 1655 VC_LVBMS_avgBrickVoltage 0;
BA_ "GenSigSNA" SG_ 1655 VC_LVBMS_avgBrickVoltage "8191";
BA_ "Confidence" SG_ 1655 VC_LVBMS_minBrickVoltage 0;
BA_ "GenSigSNA" SG_ 1655 VC_LVBMS_minBrickVoltage "8191";
BA_ "Confidence" SG_ 1655 VC_LVBMS_minBrickVoltageIndex 0;
BA_ "GenSigSNA" SG_ 1655 VC_LVBMS_minBrickVoltageIndex "255";
BA_ "Confidence" SG_ 1816 VC_lvbmsStatusLowIndex 0;
BA_ "Confidence" SG_ 1816 VC_LVBMS_SOC 0;
BA_ "GenSigSNA" SG_ 1816 VC_LVBMS_SOC "1023";
BA_ "Confidence" SG_ 1816 VC_LVBMS_SOE 0;
BA_ "GenSigSNA" SG_ 1816 VC_LVBMS_SOE "127";
BA_ "Confidence" SG_ 1816 VC_LVBMS_SOH 0;
BA_ "GenSigSNA" SG_ 1816 VC_LVBMS_SOH "127";
BA_ "Confidence" SG_ 1816 VC_LVBMS_CellOVLevel1 0;
BA_ "Confidence" SG_ 1816 VC_LVBMS_CellOVLevel2 0;
BA_ "Confidence" SG_ 1816 VC_LVBMS_CellOVLevel3 0;
BA_ "Confidence" SG_ 1816 VC_LVBMS_CellUVLevel1 0;
BA_ "Confidence" SG_ 1816 VC_LVBMS_CellUVLevel2 0;
BA_ "Confidence" SG_ 1816 VC_LVBMS_ModuleOTLevel1 0;
BA_ "Confidence" SG_ 1816 VC_LVBMS_PackOVLevel1 0;
BA_ "Confidence" SG_ 1816 VC_LVBMS_PackOVLevel2 0;
BA_ "Confidence" SG_ 1816 VC_LVBMS_DischrgOCLevel1 0;
BA_ "Confidence" SG_ 1816 VC_LVBMS_DischrgOCLevel2 0;
BA_ "Confidence" SG_ 1816 VC_LVBMS_ChrgOCLevel1 0;
BA_ "Confidence" SG_ 1816 VC_LVBMS_ChrgOCLevel2 0;
BA_ "Confidence" SG_ 1816 VC_LVBMS_MOSFETOTLevel1 0;
BA_ "Confidence" SG_ 1816 VC_LVBMS_KBValueLostFault 0;
BA_ "Confidence" SG_ 1816 VC_LVBMS_BalanceCircuitFault 0;
BA_ "Confidence" SG_ 1816 VC_LVBMS_MOSStateFault 0;
BA_ "Confidence" SG_ 1816 VC_LVBMS_NTCTempDiffWarnLevel1 0;
BA_ "Confidence" SG_ 1816 VC_LVBMS_DeepDischargeFlag 0;
BA_ "Confidence" SG_ 1816 VC_LVBMS_SamplingError 0;
BA_ "Confidence" SG_ 1816 VC_LVBMS_MosfetStuckCloseError 0;
BA_ "Confidence" SG_ 1816 VC_LVBMS_MosfetStuckOpenError 0;
BA_ "Confidence" SG_ 1816 VC_LVBMS_AvgSleepCurrent 0;
BA_ "GenSigSNA" SG_ 1816 VC_LVBMS_AvgSleepCurrent "65535";
BA_ "Confidence" SG_ 1816 VC_LVBMS_TimeSlept 0;
BA_ "GenSigSNA" SG_ 1816 VC_LVBMS_TimeSlept "16777215";
BA_ "Confidence" SG_ 1816 VC_LVBMS_SOP 0;
BA_ "GenSigSNA" SG_ 1816 VC_LVBMS_SOP "255";
BA_ "Confidence" SG_ 1816 VC_LVBMS_AhCharged 0;
BA_ "GenSigSNA" SG_ 1816 VC_LVBMS_AhCharged "4294967295";
BA_ "Confidence" SG_ 1816 VC_LVBMS_MinSleepCurrent 0;
BA_ "GenSigSNA" SG_ 1816 VC_LVBMS_MinSleepCurrent "65535";
BA_ "Confidence" SG_ 1816 VC_LVBMS_AhDischarged 0;
BA_ "GenSigSNA" SG_ 1816 VC_LVBMS_AhDischarged "4294967295";
BA_ "Confidence" SG_ 1816 VC_LVBMS_MaxSleepCurrent 0;
BA_ "GenSigSNA" SG_ 1816 VC_LVBMS_MaxSleepCurrent "65535";
BA_ "Confidence" SG_ 1816 VC_LVBMS_sumCellVoltageFiltered 0;
BA_ "GenSigSNA" SG_ 1816 VC_LVBMS_sumCellVoltageFiltered "65535";
BA_ "Confidence" SG_ 1816 VC_LVBMS_maxCellSOC 0;
BA_ "GenSigSNA" SG_ 1816 VC_LVBMS_maxCellSOC "1023";
BA_ "Confidence" SG_ 1816 VC_LVBMS_minCellSOC 0;
BA_ "GenSigSNA" SG_ 1816 VC_LVBMS_minCellSOC "1023";
BA_ "Confidence" SG_ 1816 VC_LVBMS_staticSOCCorrection 0;
BA_ "Confidence" SG_ 1816 VC_LVBMS_dynamicSOCCorrection 0;
BA_ "Confidence" SG_ 1816 VC_LVBMS_usableEnergyAvailable 0;
BA_ "GenSigSNA" SG_ 1816 VC_LVBMS_usableEnergyAvailable "4095";
BA_ "Confidence" SG_ 1816 VC_LVBMS_brakeTelltale 0;
BA_ "Confidence" SG_ 1089 VC_pcsInterfaceMuxIndex 0;
BA_ "Confidence" SG_ 1089 VC_pcsInterfaceCounter 0;
BA_ "Confidence" SG_ 1089 VC_pcsInterfaceChecksum 0;
BA_ "Confidence" SG_ 1089 VC_pcsLVVoltageTarget 0;
BA_ "Confidence" SG_ 1089 VC_pcsLVMinVoltageLimit 0;
BA_ "Confidence" SG_ 1089 VC_pcsLVMaxVoltageLimit 0;
BA_ "Confidence" SG_ 1089 VC_goodForPCSPowerCycle 0;
BA_ "Confidence" SG_ 1089 VC_LVBatteryCannotSupportVehicle 0;
BA_ "Confidence" SG_ 1089 VC_pcsResistanceFiltered 0;
BA_ "GenSigSNA" SG_ 1089 VC_pcsResistanceFiltered "65535";
BA_ "Confidence" SG_ 1089 VC_pcsLVMaxDchrgCurrentLimit 0;
BA_ "Confidence" SG_ 1089 VC_defaultPcsLVVoltageTarget 0;
BA_ "Confidence" SG_ 1089 VC_lvHwProtSelfTestActive 0;
BA_ "Confidence" SG_ 1089 VC_lvBatteryDischargeRequest 0;
BA_ "Confidence" SG_ 1091 VC_pcsManagementChecksum 0;
BA_ "Confidence" SG_ 1091 VC_pcsManagementCounter 0;
BA_ "Confidence" SG_ 1091 VC_pcsManagementMuxIndex 1;
BA_ "Confidence" SG_ 1091 VC_dcdcLVVoltageTargetMax 0;
BA_ "Confidence" SG_ 1091 VC_dcdcLVVoltageTargetMin 0;
BA_ "Confidence" SG_ 1091 VC_dcdcLVInputPowerLimit 0;
BA_ "Confidence" SG_ 1107 VEH_pricebookId 0;
BA_ "Confidence" SG_ 1029 VIN_muxID 0;
BA_ "Confidence" SG_ 1029 VIN_char01 0;
BA_ "Confidence" SG_ 1029 VIN_char02 0;
BA_ "Confidence" SG_ 1029 VIN_char03 0;
BA_ "Confidence" SG_ 1029 VIN_char04 0;
BA_ "Confidence" SG_ 1029 VIN_char05 0;
BA_ "Confidence" SG_ 1029 VIN_char06 0;
BA_ "Confidence" SG_ 1029 VIN_char07 0;
BA_ "Confidence" SG_ 1029 VIN_char08 0;
BA_ "Confidence" SG_ 1029 VIN_char09 0;
BA_ "Confidence" SG_ 1029 VIN_char10 0;
BA_ "Confidence" SG_ 1029 VIN_char11 0;
BA_ "Confidence" SG_ 1029 VIN_char12 0;
BA_ "Confidence" SG_ 1029 VIN_char13 0;
BA_ "Confidence" SG_ 1029 VIN_char14 0;
BA_ "Confidence" SG_ 1029 VIN_char15 0;
BA_ "Confidence" SG_ 1029 VIN_char16 0;
BA_ "Confidence" SG_ 1029 VIN_char17 0;
VAL_ 1017 VCSEC_matrixIndex 8 "AlertMatrix8" 7 "AlertMatrix7" 6 "AlertMatrix6" 5 "AlertMatrix5" 4 "AlertMatrix4" 3 "AlertMatrix3" 2 "AlertMatrix2" 1 "AlertMatrix1" 0 "AlertMatrix0" ;
VAL_ 825 VCSEC_authRejectionReason 5 "AUTHENTICATIONREJECTION_DEVICE_NOT_UNLOCKED_ON_WRIST" 4 "AUTHENTICATIONREJECTION_PASSIVE_DISABLED_AUTOMATION" 3 "AUTHENTICATIONREJECTION_NO_TOKEN" 2 "AUTHENTICATIONREJECTION_PASSIVE_DISABLED" 1 "AUTHENTICATIONREJECTION_DEVICE_STATIONARY" 0 "AUTHENTICATIONREJECTION_NONE" ;
VAL_ 825 VCSEC_operationMode 2 "OPERATION_MODE_FLEET" 1 "OPERATION_MODE_OWNER" 0 "OPERATION_MODE_UNKNOWN" ;
VAL_ 825 VCSEC_vehicleLockStatus 15 "LOCK_STATUS_PASSIVE_INTERNAL_LOCKED" 14 "LOCK_STATUS_PASSIVE_INTERNAL_UNLOCKED" 13 "LOCK_STATUS_CRASH_UNLOCKED" 12 "LOCK_STATUS_ACTIVE_REMOTE_LOCKED" 11 "LOCK_STATUS_ACTIVE_REMOTE_UNLOCKED" 10 "LOCK_STATUS_ACTIVE_UI_LOCKED" 9 "LOCK_STATUS_ACTIVE_UI_UNLOCKED" 8 "LOCK_STATUS_ACTIVE_BLE_LOCKED" 7 "LOCK_STATUS_ACTIVE_BLE_UNLOCKED" 6 "LOCK_STATUS_ACTIVE_SELECTIVE_UNLOCKED" 5 "LOCK_STATUS_PASSIVE_BLE_LOCKED" 4 "LOCK_STATUS_PASSIVE_BLE_UNLOCKED" 3 "LOCK_STATUS_PASSIVE_SELECTIVE_UNLOCKED" 2 "LOCK_STATUS_ACTIVE_NFC_LOCKED" 1 "LOCK_STATUS_ACTIVE_NFC_UNLOCKED" 0 "LOCK_STATUS_SNA" ;
VAL_ 825 VCSEC_authenticationStatus 2 "AUTHENTICATION_AUTHENTICATED_FOR_DRIVE" 1 "AUTHENTICATION_AUTHENTICATED_FOR_UNLOCK" 0 "AUTHENTICATION_NONE" ;
VAL_ 825 VCSEC_chargePortLockStatus 1 "CLOSURE_LOCKED" 0 "CLOSURE_UNLOCKED" ;
VAL_ 825 VCSEC_leftFrontLockStatus 1 "CLOSURE_LOCKED" 0 "CLOSURE_UNLOCKED" ;
VAL_ 825 VCSEC_leftRearLockStatus 1 "CLOSURE_LOCKED" 0 "CLOSURE_UNLOCKED" ;
VAL_ 825 VCSEC_rightFrontLockStatus 1 "CLOSURE_LOCKED" 0 "CLOSURE_UNLOCKED" ;
VAL_ 825 VCSEC_rightRearLockStatus 1 "CLOSURE_LOCKED" 0 "CLOSURE_UNLOCKED" ;
VAL_ 825 VCSEC_trunkLockStatus 1 "CLOSURE_LOCKED" 0 "CLOSURE_UNLOCKED" ;
VAL_ 825 VCSEC_lockRequestType 21 "LOCK_REQUEST_KEYFOB_OPEN_DOOR_REQUEST" 20 "LOCK_REQUEST_PASSIVE_AUTO_PRESENT_DOOR_REQUEST" 19 "LOCK_REQUEST_PASSIVE_INTERNAL_LOCK_PROMOTION" 18 "LOCK_REQUEST_ACTIVE_BLE_LOCK" 17 "LOCK_REQUEST_ACTIVE_BLE_UNLOCK" 16 "LOCK_REQUEST_ACTIVE_NFC_LOCK" 15 "LOCK_REQUEST_ACTIVE_NFC_UNLOCK" 14 "LOCK_REQUEST_ACTIVE_REMOTE_LOCK" 13 "LOCK_REQUEST_ACTIVE_REMOTE_UNLOCK" 12 "LOCK_REQUEST_ACTIVE_UI_BUTTON_LOCK" 11 "LOCK_REQUEST_ACTIVE_UI_BUTTON_UNLOCK" 10 "LOCK_REQUEST_CRASH_UNLOCK" 9 "LOCK_REQUEST_PASSIVE_BLE_LOCK" 8 "LOCK_REQUEST_PASSIVE_BLE_INTERIOR_HANDLE_UNLOCK" 7 "LOCK_REQUEST_PASSIVE_BLE_EXTERIOR_HANDLE_UNLOCK" 6 "LOCK_REQUEST_PASSIVE_BLE_EXTERIOR_CHARGEHANDLEBUTTON_UNLOCK" 5 "LOCK_REQUEST_PASSIVE_BLE_WALKUP_UNLOCK" 4 "LOCK_REQUEST_PASSIVE_DRIVE_AWAY_LOCK" 3 "LOCK_REQUEST_PASSIVE_INTERNAL_HANDLE_UNLOCK" 2 "LOCK_REQUEST_PASSIVE_PARKBUTTON_UNLOCK" 1 "LOCK_REQUEST_PASSIVE_SHIFT_TO_P_UNLOCK" 0 "LOCK_REQUEST_NONE" ;
VAL_ 825 VCSEC_summonRequest 5 "SUMMON_REQUEST_SNA" 4 "SUMMON_REQUEST_STOP" 3 "SUMMON_REQUEST_BACKWARD" 2 "SUMMON_REQUEST_FORWARD" 1 "SUMMON_REQUEST_PRIME" 0 "SUMMON_REQUEST_IDLE" ;
VAL_ 825 VCSEC_3rdPartyPLGRequest 3 "CLOSURE_REQUEST_SNA" 2 "CLOSURE_REQUEST_STOP" 1 "CLOSURE_REQUEST_MOVE" 0 "CLOSURE_REQUEST_NONE" ;
VAL_ 825 VCSEC_3rdPartyFrunkPLGRequest 3 "CLOSURE_REQUEST_SNA" 2 "CLOSURE_REQUEST_STOP" 1 "CLOSURE_REQUEST_MOVE" 0 "CLOSURE_REQUEST_NONE" ;
VAL_ 825 VCSEC_MCUCommandType 5 "MCU_COMMAND_COMMAND5" 4 "MCU_COMMAND_COMMAND4" 3 "MCU_COMMAND_COMMAND3" 2 "MCU_COMMAND_REMOTE_START" 1 "MCU_COMMAND_REMOTE_UNLOCK" 0 "MCU_COMMAND_NONE" ;
VAL_ 825 VCSEC_frunkLockStatus 1 "CLOSURE_LOCKED" 0 "CLOSURE_UNLOCKED" ;
VAL_ 825 VCSEC_alarmStatus 15 "ALARM_STATUS_SNA" 7 "ALARM_STATUS_DEFAULT" 6 "ALARM_STATUS_IMMINENT" 5 "ALARM_STATUS_TRIGGERED_FLASH_INACTIVE" 4 "ALARM_STATUS_ERROR" 3 "ALARM_STATUS_TRIGGERED_FLASH_ACTIVE" 2 "ALARM_STATUS_PARTIAL_ARMED" 1 "ALARM_STATUS_ARMED" 0 "ALARM_STATUS_DISARMED" ;
VAL_ 825 VCSEC_immobilizerState 6 "IMMOBILIZER_STATE_IMMOBILIZED" 5 "IMMOBILIZER_STATE_SEND_NO_GO_AUTH_RESPONSE" 4 "IMMOBILIZER_STATE_SEND_AUTH_RESPONSE" 3 "IMMOBILIZER_STATE_ENCRYPT" 2 "IMMOBILIZER_STATE_ENCRYPT_BEGIN" 1 "IMMOBILIZER_STATE_PREPARE" 0 "IMMOBILIZER_STATE_IDLE" ;
VAL_ 825 VCSEC_lockIndicationRequest 4 "INDICATION_HOLD" 3 "INDICATION_TRIPLE" 2 "INDICATION_DOUBLE" 1 "INDICATION_SINGLE" 0 "INDICATION_NONE_SNA" ;
VAL_ 825 VCSEC_simpleLockStatus 2 "SIMPLE_LOCK_STATUS_LOCKED" 1 "SIMPLE_LOCK_STATUS_UNLOCKED" 0 "SIMPLE_LOCK_STATUS_SNA" ;
VAL_ 825 VCSEC_keyChannelIndexed 15 "SNA" ;
VAL_ 825 VCSEC_remoteStartActive 3 "VCSEC_REMOTE_START_TYPE_SIGNED_COMMAND_PIN_REQUIRED" 2 "VCSEC_REMOTE_START_TYPE_SIGNED_COMMAND" 1 "VCSEC_REMOTE_START_TYPE_LEGACY" 0 "VCSEC_REMOTE_START_TYPE_NONE" ;
VAL_ 1817 VCSEC_debug100msIndex 23 "ConnectionBenchmark2" 22 "ConnectionBenchmark1" 21 "ConnectionBenchmark0" 20 "BLEDeviceDebug" 19 "SerialPortDebug" 14 "NNClassifierDebug" 13 "ProtobufDebug" 12 "RoutableDebug" 10 "NIStateRemote" 9 "NIState2" 8 "NIState0" 7 "BLEBondingState" 5 "Mux5" 3 "LastAdvertRSSI" 2 "UHFReceiver" 1 "Mux1" 0 "Mux0" ;
VAL_ 1817 VCSEC_walkAwayLockKeyState 3 "SECURITY_WALKAWAYLOCKING_NO_KEYS_PRESENT" 2 "SECURITY_WALKAWAYLOCKING_KEY_WAIT_FOR_NO_KEYS_PRESENT" 1 "SECURITY_WALKAWAYLOCKING_KEY_STATE_AWAITING_KEY_LEAVING" 0 "SECURITY_WALKAWAYLOCKING_KEY_STATE_IDLE" ;
VAL_ 1817 VCSEC_walkAwayLockState 5 "SECURITY_WALKAWAYLOCKING_STATE_INHIBITED" 4 "SECURITY_WALKAWAYLOCKING_STATE_DISABLED_DUE_TO_KEY_PRESENT" 3 "SECURITY_WALKAWAYLOCKING_STATE_LOCK_DESIRED" 2 "SECURITY_WALKAWAYLOCKING_STATE_WAITING_FOR_KEY_LEAVING" 1 "SECURITY_WALKAWAYLOCKING_STATE_WALK_AWAY_LOCK_ARMING" 0 "SECURITY_WALKAWAYLOCKING_STATE_IDLE" ;
VAL_ 1817 VCSEC_endpointLayout 2 "VCSEC_ENDPOINT_LAYOUT_3" 1 "VCSEC_ENDPOINT_LAYOUT_2" 0 "VCSEC_ENDPOINT_LAYOUT_1" ;
VAL_ 1817 VCSEC_walkUpUnlockState 4 "WALK_UP_UNLOCK_STATE_DISABLED" 3 "WALK_UP_UNLOCK_STATE_UNLOCK_DESIRED" 2 "WALK_UP_UNLOCK_STATE_AWAITING_KEY" 1 "WALK_UP_UNLOCK_STATE_ARMING" 0 "WALK_UP_UNLOCK_STATE_IDLE" ;
VAL_ 1817 VCSEC_pollingReason 13 "POLLINGREASON_MULTIPLE" 12 "POLLINGREASON_AUTOPILOT" 11 "POLLINGREASON_APPROACH_LIGHTING" 10 "POLLINGREASON_AUTO_PRESENT_HANDLES" 9 "POLLINGREASON_AUTORELOCK" 8 "POLLINGREASON_DRIVE_AWAY_CHECK_FOR_KEY" 7 "POLLINGREASON_AUTO_PRESENT_DOOR" 6 "POLLINGREASON_ACCESSORY_RAIL" 5 "POLLINGREASON_WALK_UP_UNLOCK" 4 "POLLINGREASON_WALK_AWAY_LOCK" 3 "POLLINGREASON_PASSIVE_UNLOCK" 2 "POLLINGREASON_PASSIVE_AUTHENTICATION" 1 "POLLINGREASON_IMMOBILIZER" 0 "POLLINGREASON_NONE" ;
VAL_ 1817 VCSEC_thermalDetectState 3 "VCSEC_THERMALDETECTIONSTATE_TRIPPED" 2 "VCSEC_THERMALDETECTIONSTATE_CONFIRMING_THRESHOLD" 1 "VCSEC_THERMALDETECTIONSTATE_MONITORING" 0 "VCSEC_THERMALDETECTIONSTATE_DISABLED" ;
VAL_ 1817 VCSEC_connection0BondingState 15 "WAIT_FOR_BOND_REJECTED" 14 "BOND" 13 "WAIT_FOR_BOND_REQUEST" 12 "BOND_FAILURE" 11 "PAIRING_REQUESTED" 10 "REJECT_BOND" 9 "WAIT_FOR_SIGNABLE" 8 "SEND_SIGNABLE" 7 "WAIT_FOR_BOND" 6 "WAIT_FOR_PAIRING" 5 "WAIT_FOR_AUTHENTICATE" 4 "SHOULD_BE_BONDED" 3 "BONDED" 2 "NOT_BONDED" 1 "CONNECTED" 0 "NOT_CONNECTED" ;
VAL_ 1817 VCSEC_connection1BondingState 15 "WAIT_FOR_BOND_REJECTED" 14 "BOND" 13 "WAIT_FOR_BOND_REQUEST" 12 "BOND_FAILURE" 11 "PAIRING_REQUESTED" 10 "REJECT_BOND" 9 "WAIT_FOR_SIGNABLE" 8 "SEND_SIGNABLE" 7 "WAIT_FOR_BOND" 6 "WAIT_FOR_PAIRING" 5 "WAIT_FOR_AUTHENTICATE" 4 "SHOULD_BE_BONDED" 3 "BONDED" 2 "NOT_BONDED" 1 "CONNECTED" 0 "NOT_CONNECTED" ;
VAL_ 1817 VCSEC_connection2BondingState 15 "WAIT_FOR_BOND_REJECTED" 14 "BOND" 13 "WAIT_FOR_BOND_REQUEST" 12 "BOND_FAILURE" 11 "PAIRING_REQUESTED" 10 "REJECT_BOND" 9 "WAIT_FOR_SIGNABLE" 8 "SEND_SIGNABLE" 7 "WAIT_FOR_BOND" 6 "WAIT_FOR_PAIRING" 5 "WAIT_FOR_AUTHENTICATE" 4 "SHOULD_BE_BONDED" 3 "BONDED" 2 "NOT_BONDED" 1 "CONNECTED" 0 "NOT_CONNECTED" ;
VAL_ 1817 VCSEC_connection0UWBAvailability 16 "UNAVAILABLE_UNKNOWN_REASON" 15 "UNAVAILABLE_UWB_DISABLED_BY_USER" 14 "PHONE_ERROR" 13 "RADIOCONFIG_NOT_READY" 12 "UPDATE_NOT_READY" 11 "GENEALOGY_NOT_READY" 10 "BLE_CHIP_NOT_READY" 9 "UWB_CHIP_NOT_READY" 8 "UNAVAILABLE_NOT_SELECTED" 7 "UWB_NOT_ENABLED_ON_THE_VEHICLE" 6 "AVAILBLE_BUT_NOT_GAP_BONDED" 5 "UNAVAILABLE_PERMISSION_DENIED" 4 "UNAVAILABLE_UNSUPPORTED_DEVICE" 3 "TEMPORARILY_UNAVAILABLE" 2 "AVAILABLE_BUT_NOT_RANGING_ON_DRIVER_ENDPOINT" 1 "AVAILABLE" 0 "NONE" ;
VAL_ 1817 VCSEC_connection1UWBAvailability 16 "UNAVAILABLE_UNKNOWN_REASON" 15 "UNAVAILABLE_UWB_DISABLED_BY_USER" 14 "PHONE_ERROR" 13 "RADIOCONFIG_NOT_READY" 12 "UPDATE_NOT_READY" 11 "GENEALOGY_NOT_READY" 10 "BLE_CHIP_NOT_READY" 9 "UWB_CHIP_NOT_READY" 8 "UNAVAILABLE_NOT_SELECTED" 7 "UWB_NOT_ENABLED_ON_THE_VEHICLE" 6 "AVAILBLE_BUT_NOT_GAP_BONDED" 5 "UNAVAILABLE_PERMISSION_DENIED" 4 "UNAVAILABLE_UNSUPPORTED_DEVICE" 3 "TEMPORARILY_UNAVAILABLE" 2 "AVAILABLE_BUT_NOT_RANGING_ON_DRIVER_ENDPOINT" 1 "AVAILABLE" 0 "NONE" ;
VAL_ 1817 VCSEC_connection2UWBAvailability 16 "UNAVAILABLE_UNKNOWN_REASON" 15 "UNAVAILABLE_UWB_DISABLED_BY_USER" 14 "PHONE_ERROR" 13 "RADIOCONFIG_NOT_READY" 12 "UPDATE_NOT_READY" 11 "GENEALOGY_NOT_READY" 10 "BLE_CHIP_NOT_READY" 9 "UWB_CHIP_NOT_READY" 8 "UNAVAILABLE_NOT_SELECTED" 7 "UWB_NOT_ENABLED_ON_THE_VEHICLE" 6 "AVAILBLE_BUT_NOT_GAP_BONDED" 5 "UNAVAILABLE_PERMISSION_DENIED" 4 "UNAVAILABLE_UNSUPPORTED_DEVICE" 3 "TEMPORARILY_UNAVAILABLE" 2 "AVAILABLE_BUT_NOT_RANGING_ON_DRIVER_ENDPOINT" 1 "AVAILABLE" 0 "NONE" ;
VAL_ 1817 VCSEC_NISessionStateCenter0 21 "COUNT" 20 "SESSION_INITIATE" 19 "WAIT_FOR_SESSION_INITIATE" 18 "WAIT_FOR_SESSION_STATE_ACTIVE" 17 "UNRECOVERABLE_DEVICE_ERROR" 16 "ERROR_WAIT_FOR_RESET" 15 "WAIT_FOR_RETRY_AFTER_ERROR" 14 "WAIT_FOR_SESSION_DEINIT" 13 "DEINIT_SESSION" 12 "WAIT_FOR_SESSION_STOP" 11 "STOP_SESSION" 10 "RANGING" 9 "WAIT_FOR_RANGING_STARTED_CONFIRMATION" 8 "WAIT_FOR_APPLE_SESSION_INITIATE" 7 "APPLE_SESSION_INITIATE" 6 "WAIT_FOR_APPLE_SHAREABLE_CONFIGURATION_DATA" 5 "SEND_CONFIGURATION_DATA_TO_PHONE" 4 "WAIT_FOR_CONFIGURATION_DATA" 3 "REQUEST_CONFIGURATION_DATA" 2 "WAIT_FOR_CORE_CONFIG_DATA" 1 "APPLY_CORE_CONFIG_DATA" 0 "IDLE" ;
VAL_ 1817 VCSEC_NISessionStateLeft0 21 "COUNT" 20 "SESSION_INITIATE" 19 "WAIT_FOR_SESSION_INITIATE" 18 "WAIT_FOR_SESSION_STATE_ACTIVE" 17 "UNRECOVERABLE_DEVICE_ERROR" 16 "ERROR_WAIT_FOR_RESET" 15 "WAIT_FOR_RETRY_AFTER_ERROR" 14 "WAIT_FOR_SESSION_DEINIT" 13 "DEINIT_SESSION" 12 "WAIT_FOR_SESSION_STOP" 11 "STOP_SESSION" 10 "RANGING" 9 "WAIT_FOR_RANGING_STARTED_CONFIRMATION" 8 "WAIT_FOR_APPLE_SESSION_INITIATE" 7 "APPLE_SESSION_INITIATE" 6 "WAIT_FOR_APPLE_SHAREABLE_CONFIGURATION_DATA" 5 "SEND_CONFIGURATION_DATA_TO_PHONE" 4 "WAIT_FOR_CONFIGURATION_DATA" 3 "REQUEST_CONFIGURATION_DATA" 2 "WAIT_FOR_CORE_CONFIG_DATA" 1 "APPLY_CORE_CONFIG_DATA" 0 "IDLE" ;
VAL_ 1817 VCSEC_NISessionStateRight0 21 "COUNT" 20 "SESSION_INITIATE" 19 "WAIT_FOR_SESSION_INITIATE" 18 "WAIT_FOR_SESSION_STATE_ACTIVE" 17 "UNRECOVERABLE_DEVICE_ERROR" 16 "ERROR_WAIT_FOR_RESET" 15 "WAIT_FOR_RETRY_AFTER_ERROR" 14 "WAIT_FOR_SESSION_DEINIT" 13 "DEINIT_SESSION" 12 "WAIT_FOR_SESSION_STOP" 11 "STOP_SESSION" 10 "RANGING" 9 "WAIT_FOR_RANGING_STARTED_CONFIRMATION" 8 "WAIT_FOR_APPLE_SESSION_INITIATE" 7 "APPLE_SESSION_INITIATE" 6 "WAIT_FOR_APPLE_SHAREABLE_CONFIGURATION_DATA" 5 "SEND_CONFIGURATION_DATA_TO_PHONE" 4 "WAIT_FOR_CONFIGURATION_DATA" 3 "REQUEST_CONFIGURATION_DATA" 2 "WAIT_FOR_CORE_CONFIG_DATA" 1 "APPLY_CORE_CONFIG_DATA" 0 "IDLE" ;
VAL_ 1817 VCSEC_NISessionStateRearLeft0 21 "COUNT" 20 "SESSION_INITIATE" 19 "WAIT_FOR_SESSION_INITIATE" 18 "WAIT_FOR_SESSION_STATE_ACTIVE" 17 "UNRECOVERABLE_DEVICE_ERROR" 16 "ERROR_WAIT_FOR_RESET" 15 "WAIT_FOR_RETRY_AFTER_ERROR" 14 "WAIT_FOR_SESSION_DEINIT" 13 "DEINIT_SESSION" 12 "WAIT_FOR_SESSION_STOP" 11 "STOP_SESSION" 10 "RANGING" 9 "WAIT_FOR_RANGING_STARTED_CONFIRMATION" 8 "WAIT_FOR_APPLE_SESSION_INITIATE" 7 "APPLE_SESSION_INITIATE" 6 "WAIT_FOR_APPLE_SHAREABLE_CONFIGURATION_DATA" 5 "SEND_CONFIGURATION_DATA_TO_PHONE" 4 "WAIT_FOR_CONFIGURATION_DATA" 3 "REQUEST_CONFIGURATION_DATA" 2 "WAIT_FOR_CORE_CONFIG_DATA" 1 "APPLY_CORE_CONFIG_DATA" 0 "IDLE" ;
VAL_ 1817 VCSEC_NISessionStateRearRight0 21 "COUNT" 20 "SESSION_INITIATE" 19 "WAIT_FOR_SESSION_INITIATE" 18 "WAIT_FOR_SESSION_STATE_ACTIVE" 17 "UNRECOVERABLE_DEVICE_ERROR" 16 "ERROR_WAIT_FOR_RESET" 15 "WAIT_FOR_RETRY_AFTER_ERROR" 14 "WAIT_FOR_SESSION_DEINIT" 13 "DEINIT_SESSION" 12 "WAIT_FOR_SESSION_STOP" 11 "STOP_SESSION" 10 "RANGING" 9 "WAIT_FOR_RANGING_STARTED_CONFIRMATION" 8 "WAIT_FOR_APPLE_SESSION_INITIATE" 7 "APPLE_SESSION_INITIATE" 6 "WAIT_FOR_APPLE_SHAREABLE_CONFIGURATION_DATA" 5 "SEND_CONFIGURATION_DATA_TO_PHONE" 4 "WAIT_FOR_CONFIGURATION_DATA" 3 "REQUEST_CONFIGURATION_DATA" 2 "WAIT_FOR_CORE_CONFIG_DATA" 1 "APPLY_CORE_CONFIG_DATA" 0 "IDLE" ;
VAL_ 1817 VCSEC_NISessionStateRear0 21 "COUNT" 20 "SESSION_INITIATE" 19 "WAIT_FOR_SESSION_INITIATE" 18 "WAIT_FOR_SESSION_STATE_ACTIVE" 17 "UNRECOVERABLE_DEVICE_ERROR" 16 "ERROR_WAIT_FOR_RESET" 15 "WAIT_FOR_RETRY_AFTER_ERROR" 14 "WAIT_FOR_SESSION_DEINIT" 13 "DEINIT_SESSION" 12 "WAIT_FOR_SESSION_STOP" 11 "STOP_SESSION" 10 "RANGING" 9 "WAIT_FOR_RANGING_STARTED_CONFIRMATION" 8 "WAIT_FOR_APPLE_SESSION_INITIATE" 7 "APPLE_SESSION_INITIATE" 6 "WAIT_FOR_APPLE_SHAREABLE_CONFIGURATION_DATA" 5 "SEND_CONFIGURATION_DATA_TO_PHONE" 4 "WAIT_FOR_CONFIGURATION_DATA" 3 "REQUEST_CONFIGURATION_DATA" 2 "WAIT_FOR_CORE_CONFIG_DATA" 1 "APPLY_CORE_CONFIG_DATA" 0 "IDLE" ;
VAL_ 1817 VCSEC_NISessionStateCenter1 21 "COUNT" 20 "SESSION_INITIATE" 19 "WAIT_FOR_SESSION_INITIATE" 18 "WAIT_FOR_SESSION_STATE_ACTIVE" 17 "UNRECOVERABLE_DEVICE_ERROR" 16 "ERROR_WAIT_FOR_RESET" 15 "WAIT_FOR_RETRY_AFTER_ERROR" 14 "WAIT_FOR_SESSION_DEINIT" 13 "DEINIT_SESSION" 12 "WAIT_FOR_SESSION_STOP" 11 "STOP_SESSION" 10 "RANGING" 9 "WAIT_FOR_RANGING_STARTED_CONFIRMATION" 8 "WAIT_FOR_APPLE_SESSION_INITIATE" 7 "APPLE_SESSION_INITIATE" 6 "WAIT_FOR_APPLE_SHAREABLE_CONFIGURATION_DATA" 5 "SEND_CONFIGURATION_DATA_TO_PHONE" 4 "WAIT_FOR_CONFIGURATION_DATA" 3 "REQUEST_CONFIGURATION_DATA" 2 "WAIT_FOR_CORE_CONFIG_DATA" 1 "APPLY_CORE_CONFIG_DATA" 0 "IDLE" ;
VAL_ 1817 VCSEC_NISessionStateLeft1 21 "COUNT" 20 "SESSION_INITIATE" 19 "WAIT_FOR_SESSION_INITIATE" 18 "WAIT_FOR_SESSION_STATE_ACTIVE" 17 "UNRECOVERABLE_DEVICE_ERROR" 16 "ERROR_WAIT_FOR_RESET" 15 "WAIT_FOR_RETRY_AFTER_ERROR" 14 "WAIT_FOR_SESSION_DEINIT" 13 "DEINIT_SESSION" 12 "WAIT_FOR_SESSION_STOP" 11 "STOP_SESSION" 10 "RANGING" 9 "WAIT_FOR_RANGING_STARTED_CONFIRMATION" 8 "WAIT_FOR_APPLE_SESSION_INITIATE" 7 "APPLE_SESSION_INITIATE" 6 "WAIT_FOR_APPLE_SHAREABLE_CONFIGURATION_DATA" 5 "SEND_CONFIGURATION_DATA_TO_PHONE" 4 "WAIT_FOR_CONFIGURATION_DATA" 3 "REQUEST_CONFIGURATION_DATA" 2 "WAIT_FOR_CORE_CONFIG_DATA" 1 "APPLY_CORE_CONFIG_DATA" 0 "IDLE" ;
VAL_ 1817 VCSEC_NISessionStateRight1 21 "COUNT" 20 "SESSION_INITIATE" 19 "WAIT_FOR_SESSION_INITIATE" 18 "WAIT_FOR_SESSION_STATE_ACTIVE" 17 "UNRECOVERABLE_DEVICE_ERROR" 16 "ERROR_WAIT_FOR_RESET" 15 "WAIT_FOR_RETRY_AFTER_ERROR" 14 "WAIT_FOR_SESSION_DEINIT" 13 "DEINIT_SESSION" 12 "WAIT_FOR_SESSION_STOP" 11 "STOP_SESSION" 10 "RANGING" 9 "WAIT_FOR_RANGING_STARTED_CONFIRMATION" 8 "WAIT_FOR_APPLE_SESSION_INITIATE" 7 "APPLE_SESSION_INITIATE" 6 "WAIT_FOR_APPLE_SHAREABLE_CONFIGURATION_DATA" 5 "SEND_CONFIGURATION_DATA_TO_PHONE" 4 "WAIT_FOR_CONFIGURATION_DATA" 3 "REQUEST_CONFIGURATION_DATA" 2 "WAIT_FOR_CORE_CONFIG_DATA" 1 "APPLY_CORE_CONFIG_DATA" 0 "IDLE" ;
VAL_ 1817 VCSEC_NISessionStateRearLeft1 21 "COUNT" 20 "SESSION_INITIATE" 19 "WAIT_FOR_SESSION_INITIATE" 18 "WAIT_FOR_SESSION_STATE_ACTIVE" 17 "UNRECOVERABLE_DEVICE_ERROR" 16 "ERROR_WAIT_FOR_RESET" 15 "WAIT_FOR_RETRY_AFTER_ERROR" 14 "WAIT_FOR_SESSION_DEINIT" 13 "DEINIT_SESSION" 12 "WAIT_FOR_SESSION_STOP" 11 "STOP_SESSION" 10 "RANGING" 9 "WAIT_FOR_RANGING_STARTED_CONFIRMATION" 8 "WAIT_FOR_APPLE_SESSION_INITIATE" 7 "APPLE_SESSION_INITIATE" 6 "WAIT_FOR_APPLE_SHAREABLE_CONFIGURATION_DATA" 5 "SEND_CONFIGURATION_DATA_TO_PHONE" 4 "WAIT_FOR_CONFIGURATION_DATA" 3 "REQUEST_CONFIGURATION_DATA" 2 "WAIT_FOR_CORE_CONFIG_DATA" 1 "APPLY_CORE_CONFIG_DATA" 0 "IDLE" ;
VAL_ 1817 VCSEC_NISessionStateRearRight1 21 "COUNT" 20 "SESSION_INITIATE" 19 "WAIT_FOR_SESSION_INITIATE" 18 "WAIT_FOR_SESSION_STATE_ACTIVE" 17 "UNRECOVERABLE_DEVICE_ERROR" 16 "ERROR_WAIT_FOR_RESET" 15 "WAIT_FOR_RETRY_AFTER_ERROR" 14 "WAIT_FOR_SESSION_DEINIT" 13 "DEINIT_SESSION" 12 "WAIT_FOR_SESSION_STOP" 11 "STOP_SESSION" 10 "RANGING" 9 "WAIT_FOR_RANGING_STARTED_CONFIRMATION" 8 "WAIT_FOR_APPLE_SESSION_INITIATE" 7 "APPLE_SESSION_INITIATE" 6 "WAIT_FOR_APPLE_SHAREABLE_CONFIGURATION_DATA" 5 "SEND_CONFIGURATION_DATA_TO_PHONE" 4 "WAIT_FOR_CONFIGURATION_DATA" 3 "REQUEST_CONFIGURATION_DATA" 2 "WAIT_FOR_CORE_CONFIG_DATA" 1 "APPLY_CORE_CONFIG_DATA" 0 "IDLE" ;
VAL_ 1817 VCSEC_NISessionStateRear1 21 "COUNT" 20 "SESSION_INITIATE" 19 "WAIT_FOR_SESSION_INITIATE" 18 "WAIT_FOR_SESSION_STATE_ACTIVE" 17 "UNRECOVERABLE_DEVICE_ERROR" 16 "ERROR_WAIT_FOR_RESET" 15 "WAIT_FOR_RETRY_AFTER_ERROR" 14 "WAIT_FOR_SESSION_DEINIT" 13 "DEINIT_SESSION" 12 "WAIT_FOR_SESSION_STOP" 11 "STOP_SESSION" 10 "RANGING" 9 "WAIT_FOR_RANGING_STARTED_CONFIRMATION" 8 "WAIT_FOR_APPLE_SESSION_INITIATE" 7 "APPLE_SESSION_INITIATE" 6 "WAIT_FOR_APPLE_SHAREABLE_CONFIGURATION_DATA" 5 "SEND_CONFIGURATION_DATA_TO_PHONE" 4 "WAIT_FOR_CONFIGURATION_DATA" 3 "REQUEST_CONFIGURATION_DATA" 2 "WAIT_FOR_CORE_CONFIG_DATA" 1 "APPLY_CORE_CONFIG_DATA" 0 "IDLE" ;
VAL_ 1817 VCSEC_NISessionStateCenter2 21 "COUNT" 20 "SESSION_INITIATE" 19 "WAIT_FOR_SESSION_INITIATE" 18 "WAIT_FOR_SESSION_STATE_ACTIVE" 17 "UNRECOVERABLE_DEVICE_ERROR" 16 "ERROR_WAIT_FOR_RESET" 15 "WAIT_FOR_RETRY_AFTER_ERROR" 14 "WAIT_FOR_SESSION_DEINIT" 13 "DEINIT_SESSION" 12 "WAIT_FOR_SESSION_STOP" 11 "STOP_SESSION" 10 "RANGING" 9 "WAIT_FOR_RANGING_STARTED_CONFIRMATION" 8 "WAIT_FOR_APPLE_SESSION_INITIATE" 7 "APPLE_SESSION_INITIATE" 6 "WAIT_FOR_APPLE_SHAREABLE_CONFIGURATION_DATA" 5 "SEND_CONFIGURATION_DATA_TO_PHONE" 4 "WAIT_FOR_CONFIGURATION_DATA" 3 "REQUEST_CONFIGURATION_DATA" 2 "WAIT_FOR_CORE_CONFIG_DATA" 1 "APPLY_CORE_CONFIG_DATA" 0 "IDLE" ;
VAL_ 1817 VCSEC_NISessionStateLeft2 21 "COUNT" 20 "SESSION_INITIATE" 19 "WAIT_FOR_SESSION_INITIATE" 18 "WAIT_FOR_SESSION_STATE_ACTIVE" 17 "UNRECOVERABLE_DEVICE_ERROR" 16 "ERROR_WAIT_FOR_RESET" 15 "WAIT_FOR_RETRY_AFTER_ERROR" 14 "WAIT_FOR_SESSION_DEINIT" 13 "DEINIT_SESSION" 12 "WAIT_FOR_SESSION_STOP" 11 "STOP_SESSION" 10 "RANGING" 9 "WAIT_FOR_RANGING_STARTED_CONFIRMATION" 8 "WAIT_FOR_APPLE_SESSION_INITIATE" 7 "APPLE_SESSION_INITIATE" 6 "WAIT_FOR_APPLE_SHAREABLE_CONFIGURATION_DATA" 5 "SEND_CONFIGURATION_DATA_TO_PHONE" 4 "WAIT_FOR_CONFIGURATION_DATA" 3 "REQUEST_CONFIGURATION_DATA" 2 "WAIT_FOR_CORE_CONFIG_DATA" 1 "APPLY_CORE_CONFIG_DATA" 0 "IDLE" ;
VAL_ 1817 VCSEC_NISessionStateRight2 21 "COUNT" 20 "SESSION_INITIATE" 19 "WAIT_FOR_SESSION_INITIATE" 18 "WAIT_FOR_SESSION_STATE_ACTIVE" 17 "UNRECOVERABLE_DEVICE_ERROR" 16 "ERROR_WAIT_FOR_RESET" 15 "WAIT_FOR_RETRY_AFTER_ERROR" 14 "WAIT_FOR_SESSION_DEINIT" 13 "DEINIT_SESSION" 12 "WAIT_FOR_SESSION_STOP" 11 "STOP_SESSION" 10 "RANGING" 9 "WAIT_FOR_RANGING_STARTED_CONFIRMATION" 8 "WAIT_FOR_APPLE_SESSION_INITIATE" 7 "APPLE_SESSION_INITIATE" 6 "WAIT_FOR_APPLE_SHAREABLE_CONFIGURATION_DATA" 5 "SEND_CONFIGURATION_DATA_TO_PHONE" 4 "WAIT_FOR_CONFIGURATION_DATA" 3 "REQUEST_CONFIGURATION_DATA" 2 "WAIT_FOR_CORE_CONFIG_DATA" 1 "APPLY_CORE_CONFIG_DATA" 0 "IDLE" ;
VAL_ 1817 VCSEC_NISessionStateRearLeft2 21 "COUNT" 20 "SESSION_INITIATE" 19 "WAIT_FOR_SESSION_INITIATE" 18 "WAIT_FOR_SESSION_STATE_ACTIVE" 17 "UNRECOVERABLE_DEVICE_ERROR" 16 "ERROR_WAIT_FOR_RESET" 15 "WAIT_FOR_RETRY_AFTER_ERROR" 14 "WAIT_FOR_SESSION_DEINIT" 13 "DEINIT_SESSION" 12 "WAIT_FOR_SESSION_STOP" 11 "STOP_SESSION" 10 "RANGING" 9 "WAIT_FOR_RANGING_STARTED_CONFIRMATION" 8 "WAIT_FOR_APPLE_SESSION_INITIATE" 7 "APPLE_SESSION_INITIATE" 6 "WAIT_FOR_APPLE_SHAREABLE_CONFIGURATION_DATA" 5 "SEND_CONFIGURATION_DATA_TO_PHONE" 4 "WAIT_FOR_CONFIGURATION_DATA" 3 "REQUEST_CONFIGURATION_DATA" 2 "WAIT_FOR_CORE_CONFIG_DATA" 1 "APPLY_CORE_CONFIG_DATA" 0 "IDLE" ;
VAL_ 1817 VCSEC_NISessionStateRearRight2 21 "COUNT" 20 "SESSION_INITIATE" 19 "WAIT_FOR_SESSION_INITIATE" 18 "WAIT_FOR_SESSION_STATE_ACTIVE" 17 "UNRECOVERABLE_DEVICE_ERROR" 16 "ERROR_WAIT_FOR_RESET" 15 "WAIT_FOR_RETRY_AFTER_ERROR" 14 "WAIT_FOR_SESSION_DEINIT" 13 "DEINIT_SESSION" 12 "WAIT_FOR_SESSION_STOP" 11 "STOP_SESSION" 10 "RANGING" 9 "WAIT_FOR_RANGING_STARTED_CONFIRMATION" 8 "WAIT_FOR_APPLE_SESSION_INITIATE" 7 "APPLE_SESSION_INITIATE" 6 "WAIT_FOR_APPLE_SHAREABLE_CONFIGURATION_DATA" 5 "SEND_CONFIGURATION_DATA_TO_PHONE" 4 "WAIT_FOR_CONFIGURATION_DATA" 3 "REQUEST_CONFIGURATION_DATA" 2 "WAIT_FOR_CORE_CONFIG_DATA" 1 "APPLY_CORE_CONFIG_DATA" 0 "IDLE" ;
VAL_ 1817 VCSEC_NISessionStateRear2 21 "COUNT" 20 "SESSION_INITIATE" 19 "WAIT_FOR_SESSION_INITIATE" 18 "WAIT_FOR_SESSION_STATE_ACTIVE" 17 "UNRECOVERABLE_DEVICE_ERROR" 16 "ERROR_WAIT_FOR_RESET" 15 "WAIT_FOR_RETRY_AFTER_ERROR" 14 "WAIT_FOR_SESSION_DEINIT" 13 "DEINIT_SESSION" 12 "WAIT_FOR_SESSION_STOP" 11 "STOP_SESSION" 10 "RANGING" 9 "WAIT_FOR_RANGING_STARTED_CONFIRMATION" 8 "WAIT_FOR_APPLE_SESSION_INITIATE" 7 "APPLE_SESSION_INITIATE" 6 "WAIT_FOR_APPLE_SHAREABLE_CONFIGURATION_DATA" 5 "SEND_CONFIGURATION_DATA_TO_PHONE" 4 "WAIT_FOR_CONFIGURATION_DATA" 3 "REQUEST_CONFIGURATION_DATA" 2 "WAIT_FOR_CORE_CONFIG_DATA" 1 "APPLY_CORE_CONFIG_DATA" 0 "IDLE" ;
VAL_ 1817 VCSEC_NISessionStateLeft3 21 "COUNT" 20 "SESSION_INITIATE" 19 "WAIT_FOR_SESSION_INITIATE" 18 "WAIT_FOR_SESSION_STATE_ACTIVE" 17 "UNRECOVERABLE_DEVICE_ERROR" 16 "ERROR_WAIT_FOR_RESET" 15 "WAIT_FOR_RETRY_AFTER_ERROR" 14 "WAIT_FOR_SESSION_DEINIT" 13 "DEINIT_SESSION" 12 "WAIT_FOR_SESSION_STOP" 11 "STOP_SESSION" 10 "RANGING" 9 "WAIT_FOR_RANGING_STARTED_CONFIRMATION" 8 "WAIT_FOR_APPLE_SESSION_INITIATE" 7 "APPLE_SESSION_INITIATE" 6 "WAIT_FOR_APPLE_SHAREABLE_CONFIGURATION_DATA" 5 "SEND_CONFIGURATION_DATA_TO_PHONE" 4 "WAIT_FOR_CONFIGURATION_DATA" 3 "REQUEST_CONFIGURATION_DATA" 2 "WAIT_FOR_CORE_CONFIG_DATA" 1 "APPLY_CORE_CONFIG_DATA" 0 "IDLE" ;
VAL_ 1817 VCSEC_NISessionStateRight3 21 "COUNT" 20 "SESSION_INITIATE" 19 "WAIT_FOR_SESSION_INITIATE" 18 "WAIT_FOR_SESSION_STATE_ACTIVE" 17 "UNRECOVERABLE_DEVICE_ERROR" 16 "ERROR_WAIT_FOR_RESET" 15 "WAIT_FOR_RETRY_AFTER_ERROR" 14 "WAIT_FOR_SESSION_DEINIT" 13 "DEINIT_SESSION" 12 "WAIT_FOR_SESSION_STOP" 11 "STOP_SESSION" 10 "RANGING" 9 "WAIT_FOR_RANGING_STARTED_CONFIRMATION" 8 "WAIT_FOR_APPLE_SESSION_INITIATE" 7 "APPLE_SESSION_INITIATE" 6 "WAIT_FOR_APPLE_SHAREABLE_CONFIGURATION_DATA" 5 "SEND_CONFIGURATION_DATA_TO_PHONE" 4 "WAIT_FOR_CONFIGURATION_DATA" 3 "REQUEST_CONFIGURATION_DATA" 2 "WAIT_FOR_CORE_CONFIG_DATA" 1 "APPLY_CORE_CONFIG_DATA" 0 "IDLE" ;
VAL_ 1817 VCSEC_NISessionStateRearRight3 21 "COUNT" 20 "SESSION_INITIATE" 19 "WAIT_FOR_SESSION_INITIATE" 18 "WAIT_FOR_SESSION_STATE_ACTIVE" 17 "UNRECOVERABLE_DEVICE_ERROR" 16 "ERROR_WAIT_FOR_RESET" 15 "WAIT_FOR_RETRY_AFTER_ERROR" 14 "WAIT_FOR_SESSION_DEINIT" 13 "DEINIT_SESSION" 12 "WAIT_FOR_SESSION_STOP" 11 "STOP_SESSION" 10 "RANGING" 9 "WAIT_FOR_RANGING_STARTED_CONFIRMATION" 8 "WAIT_FOR_APPLE_SESSION_INITIATE" 7 "APPLE_SESSION_INITIATE" 6 "WAIT_FOR_APPLE_SHAREABLE_CONFIGURATION_DATA" 5 "SEND_CONFIGURATION_DATA_TO_PHONE" 4 "WAIT_FOR_CONFIGURATION_DATA" 3 "REQUEST_CONFIGURATION_DATA" 2 "WAIT_FOR_CORE_CONFIG_DATA" 1 "APPLY_CORE_CONFIG_DATA" 0 "IDLE" ;
VAL_ 1817 VCSEC_NISessionStateRearLeft3 21 "COUNT" 20 "SESSION_INITIATE" 19 "WAIT_FOR_SESSION_INITIATE" 18 "WAIT_FOR_SESSION_STATE_ACTIVE" 17 "UNRECOVERABLE_DEVICE_ERROR" 16 "ERROR_WAIT_FOR_RESET" 15 "WAIT_FOR_RETRY_AFTER_ERROR" 14 "WAIT_FOR_SESSION_DEINIT" 13 "DEINIT_SESSION" 12 "WAIT_FOR_SESSION_STOP" 11 "STOP_SESSION" 10 "RANGING" 9 "WAIT_FOR_RANGING_STARTED_CONFIRMATION" 8 "WAIT_FOR_APPLE_SESSION_INITIATE" 7 "APPLE_SESSION_INITIATE" 6 "WAIT_FOR_APPLE_SHAREABLE_CONFIGURATION_DATA" 5 "SEND_CONFIGURATION_DATA_TO_PHONE" 4 "WAIT_FOR_CONFIGURATION_DATA" 3 "REQUEST_CONFIGURATION_DATA" 2 "WAIT_FOR_CORE_CONFIG_DATA" 1 "APPLY_CORE_CONFIG_DATA" 0 "IDLE" ;
VAL_ 1817 VCSEC_NISessionStateCenter3 21 "COUNT" 20 "SESSION_INITIATE" 19 "WAIT_FOR_SESSION_INITIATE" 18 "WAIT_FOR_SESSION_STATE_ACTIVE" 17 "UNRECOVERABLE_DEVICE_ERROR" 16 "ERROR_WAIT_FOR_RESET" 15 "WAIT_FOR_RETRY_AFTER_ERROR" 14 "WAIT_FOR_SESSION_DEINIT" 13 "DEINIT_SESSION" 12 "WAIT_FOR_SESSION_STOP" 11 "STOP_SESSION" 10 "RANGING" 9 "WAIT_FOR_RANGING_STARTED_CONFIRMATION" 8 "WAIT_FOR_APPLE_SESSION_INITIATE" 7 "APPLE_SESSION_INITIATE" 6 "WAIT_FOR_APPLE_SHAREABLE_CONFIGURATION_DATA" 5 "SEND_CONFIGURATION_DATA_TO_PHONE" 4 "WAIT_FOR_CONFIGURATION_DATA" 3 "REQUEST_CONFIGURATION_DATA" 2 "WAIT_FOR_CORE_CONFIG_DATA" 1 "APPLY_CORE_CONFIG_DATA" 0 "IDLE" ;
VAL_ 793 VCSEC_infoIndex 255 "END" 41 "SUBCOMPONENT14" 40 "SUBCOMPONENT13" 39 "SUBCOMPONENT12" 38 "SUBCOMPONENT11" 37 "SUBCOMPONENT10" 36 "SUBCOMPONENT9" 35 "SUBCOMPONENT8" 34 "SUBCOMPONENT7" 33 "SUBCOMPONENT6" 32 "SUBCOMPONENT5" 31 "SUBCOMPONENT4" 24 "SUBCOMPONENT3" 23 "SUBCOMPONENT2" 20 "UDS_PROTOCOL_BOOTCRC" 19 "VERSION_DEPRECATED" 18 "BOOTLOADER_GITHASH" 17 "APP_GITHASH" 16 "SUBCOMPONENT1" 15 "BOOTLOADER_CRC" 14 "BOOTLOADER_SVN" 13 "APP_CRC" 11 "PCBAID_ASSYID_USAGEID" 10 "BUILD_HWID_COMPONENTID" 9 "DEPRECATED_9" 8 "DEPRECATED_8" 7 "DEPRECATED_7" 6 "DEPRECATED_6" 5 "DEPRECATED_5" 4 "DEPRECATED_4" 3 "DEPRECATED_3" 2 "DEPRECATED_2" 1 "DEPRECATED_1" 0 "DEPRECATED_0" ;
VAL_ 793 VCSEC_infoBuildType 4 "INFO_MFG_BUILD" 3 "INFO_TRACEABLE_CI_BUILD" 2 "INFO_LOCAL_BUILD" 1 "INFO_PLATFORM_BUILD" 0 "INFO_UNKNOWN_BUILD" ;
VAL_ 793 VCSEC_infoAssemblyId 255 "ASSEMBLY_SNA" 1 "ASSEMBLY1" ;
VAL_ 505 VCSEC_chargePortRequest 3 "REQUEST_SNA" 2 "REQUEST_CLOSE" 1 "REQUEST_OPEN" 0 "REQUEST_NONE" ;
VAL_ 505 VCSEC_frontLeftClosureRequest 6 "POWERED_CLOSURE_REQUEST_CLOSE" 5 "POWERED_CLOSURE_REQUEST_OPEN_REDUCED" 4 "POWERED_CLOSURE_REQUEST_QUICK_OPEN" 3 "POWERED_CLOSURE_REQUEST_OPEN" 2 "POWERED_CLOSURE_REQUEST_STOP" 1 "POWERED_CLOSURE_REQUEST_MOVE" 0 "POWERED_CLOSURE_REQUEST_NONE" ;
VAL_ 505 VCSEC_frontRightClosureRequest 6 "POWERED_CLOSURE_REQUEST_CLOSE" 5 "POWERED_CLOSURE_REQUEST_OPEN_REDUCED" 4 "POWERED_CLOSURE_REQUEST_QUICK_OPEN" 3 "POWERED_CLOSURE_REQUEST_OPEN" 2 "POWERED_CLOSURE_REQUEST_STOP" 1 "POWERED_CLOSURE_REQUEST_MOVE" 0 "POWERED_CLOSURE_REQUEST_NONE" ;
VAL_ 505 VCSEC_rearLeftClosureRequest 6 "POWERED_CLOSURE_REQUEST_CLOSE" 5 "POWERED_CLOSURE_REQUEST_OPEN_REDUCED" 4 "POWERED_CLOSURE_REQUEST_QUICK_OPEN" 3 "POWERED_CLOSURE_REQUEST_OPEN" 2 "POWERED_CLOSURE_REQUEST_STOP" 1 "POWERED_CLOSURE_REQUEST_MOVE" 0 "POWERED_CLOSURE_REQUEST_NONE" ;
VAL_ 505 VCSEC_rearRightClosureRequest 6 "POWERED_CLOSURE_REQUEST_CLOSE" 5 "POWERED_CLOSURE_REQUEST_OPEN_REDUCED" 4 "POWERED_CLOSURE_REQUEST_QUICK_OPEN" 3 "POWERED_CLOSURE_REQUEST_OPEN" 2 "POWERED_CLOSURE_REQUEST_STOP" 1 "POWERED_CLOSURE_REQUEST_MOVE" 0 "POWERED_CLOSURE_REQUEST_NONE" ;
VAL_ 505 VCSEC_rearTrunkClosureRequest 6 "POWERED_CLOSURE_REQUEST_CLOSE" 5 "POWERED_CLOSURE_REQUEST_OPEN_REDUCED" 4 "POWERED_CLOSURE_REQUEST_QUICK_OPEN" 3 "POWERED_CLOSURE_REQUEST_OPEN" 2 "POWERED_CLOSURE_REQUEST_STOP" 1 "POWERED_CLOSURE_REQUEST_MOVE" 0 "POWERED_CLOSURE_REQUEST_NONE" ;
VAL_ 505 VCSEC_frontLeftRequestReason 7 "POWERED_CLOSURE_REQUEST_TAP_TO_OPEN" 6 "POWERED_CLOSURE_REQUEST_REASON_UI_REQUEST" 5 "POWERED_CLOSURE_REQUEST_UI_STOP_ALL" 4 "POWERED_CLOSURE_REQUEST_KEYFOB_UNLOCK_OPEN" 3 "POWERED_CLOSURE_REQUEST_REASON_AUTO_PRESENT" 2 "POWERED_CLOSURE_REQUEST_REASON_CLOSE_ALL" 1 "POWERED_CLOSURE_REQUEST_REASON_RKE" 0 "POWERED_CLOSURE_REQUEST_REASON_NONE" ;
VAL_ 505 VCSEC_frontRightRequestReason 7 "POWERED_CLOSURE_REQUEST_TAP_TO_OPEN" 6 "POWERED_CLOSURE_REQUEST_REASON_UI_REQUEST" 5 "POWERED_CLOSURE_REQUEST_UI_STOP_ALL" 4 "POWERED_CLOSURE_REQUEST_KEYFOB_UNLOCK_OPEN" 3 "POWERED_CLOSURE_REQUEST_REASON_AUTO_PRESENT" 2 "POWERED_CLOSURE_REQUEST_REASON_CLOSE_ALL" 1 "POWERED_CLOSURE_REQUEST_REASON_RKE" 0 "POWERED_CLOSURE_REQUEST_REASON_NONE" ;
VAL_ 505 VCSEC_rearLeftRequestReason 7 "POWERED_CLOSURE_REQUEST_TAP_TO_OPEN" 6 "POWERED_CLOSURE_REQUEST_REASON_UI_REQUEST" 5 "POWERED_CLOSURE_REQUEST_UI_STOP_ALL" 4 "POWERED_CLOSURE_REQUEST_KEYFOB_UNLOCK_OPEN" 3 "POWERED_CLOSURE_REQUEST_REASON_AUTO_PRESENT" 2 "POWERED_CLOSURE_REQUEST_REASON_CLOSE_ALL" 1 "POWERED_CLOSURE_REQUEST_REASON_RKE" 0 "POWERED_CLOSURE_REQUEST_REASON_NONE" ;
VAL_ 505 VCSEC_rearRightRequestReason 7 "POWERED_CLOSURE_REQUEST_TAP_TO_OPEN" 6 "POWERED_CLOSURE_REQUEST_REASON_UI_REQUEST" 5 "POWERED_CLOSURE_REQUEST_UI_STOP_ALL" 4 "POWERED_CLOSURE_REQUEST_KEYFOB_UNLOCK_OPEN" 3 "POWERED_CLOSURE_REQUEST_REASON_AUTO_PRESENT" 2 "POWERED_CLOSURE_REQUEST_REASON_CLOSE_ALL" 1 "POWERED_CLOSURE_REQUEST_REASON_RKE" 0 "POWERED_CLOSURE_REQUEST_REASON_NONE" ;
VAL_ 505 VCSEC_rearTrunkRequestReason 7 "POWERED_CLOSURE_REQUEST_TAP_TO_OPEN" 6 "POWERED_CLOSURE_REQUEST_REASON_UI_REQUEST" 5 "POWERED_CLOSURE_REQUEST_UI_STOP_ALL" 4 "POWERED_CLOSURE_REQUEST_KEYFOB_UNLOCK_OPEN" 3 "POWERED_CLOSURE_REQUEST_REASON_AUTO_PRESENT" 2 "POWERED_CLOSURE_REQUEST_REASON_CLOSE_ALL" 1 "POWERED_CLOSURE_REQUEST_REASON_RKE" 0 "POWERED_CLOSURE_REQUEST_REASON_NONE" ;
VAL_ 505 VCSEC_driveAttemptedWithoutAuth 10 "SHOW_B_PILLAR_NFC_CARD_TAP" 9 "SHOW_CENTER_NFC_CARD_TAP" 8 "SHOW_BRING_PHONE_CLOSER_BPILLAR_VARIANT" 7 "SHOW_BRING_PHONE_CLOSER_CENTER_VARIANT" 6 "SHOW_APP_DOWNLOAD_AND_PHONEKEY_PAIR_BPILLAR_VARIANT" 5 "SHOW_APP_DOWNLOAD_AND_PHONEKEY_PAIR_CENTER_VARIANT" 4 "SHOW_DEVICE_DISCONNECTED_GENERIC_BPILLAR_VARIANT" 3 "SHOW_DEVICE_DISCONNECTED_GENERIC_CENTER_VARIANT" 2 "SHOW_DEVICE_DISCONNECTED_IOS_BPILLAR_VARIANT" 1 "SHOW_DEVICE_DISCONNECTED_IOS_CENTER_VARIANT" 0 "NO_NFC_POPUP_DESIRED" ;
VAL_ 505 VCSEC_closeAllStatus 2 "CLOSEALL_STATE_CANCELABLE" 1 "CLOSEALL_STATE_AVAILABLE" 0 "CLOSEALL_STATE_NOT_AVAILABLE" ;
VAL_ 505 VCSEC_snapshotRequested 15 "EXTERNAL_THERMALS_HIGH" 14 "AUTO_FRUNK_FALSE_BEEP" 13 "AUTO_FRUNK" 12 "AUTHENTICATION_REJECTION_DEVICE_STATIONARY" 11 "AUTO_TRUNK" 10 "RSSI_NN_ALGO_FALSE_POSITIVE" 9 "RSSI_THRESHOLD_ALGO_FALSE_POSITIVE" 8 "RAW_RSSI_ECU_LOG_HANDLE_PULL" 7 "AUTO_TRUNK_FALSE_BEEP" 6 "UNASSIGNED_6" 5 "UNASSIGNED_5" 4 "AUTO_PRESENT_DOOR_CLOSE_WITHOUT_PEDESTRIAN_DETECTED" 3 "AUTO_PRESENT_DOOR_CLOSE_TIMEOUT" 2 "AUTHED_WITHOUT_HANDLE_PULL" 1 "HANDLE_PULL_WITHOUT_AUTH" 0 "NONE" ;
VAL_ 505 VCSEC_chargeportRequestReason 4 "VCSEC_CHARGEPORT_REQUEST_REASON_LONG_PULL_DOOR_HANDLE" 3 "VCSEC_CHARGEPORT_REQUEST_REASON_BLE_CHARGE_HANDLE" 2 "VCSEC_CHARGEPORT_REQUEST_REASON_UHF" 1 "VCSEC_CHARGEPORT_REQUEST_REASON_RKE" 0 "VCSEC_CHARGEPORT_REQUEST_REASON_NONE" ;
VAL_ 505 VCSEC_frontTrunkClosureRequest 6 "POWERED_CLOSURE_REQUEST_CLOSE" 5 "POWERED_CLOSURE_REQUEST_OPEN_REDUCED" 4 "POWERED_CLOSURE_REQUEST_QUICK_OPEN" 3 "POWERED_CLOSURE_REQUEST_OPEN" 2 "POWERED_CLOSURE_REQUEST_STOP" 1 "POWERED_CLOSURE_REQUEST_MOVE" 0 "POWERED_CLOSURE_REQUEST_NONE" ;
VAL_ 505 VCSEC_frontTrunkRequestReason 7 "POWERED_CLOSURE_REQUEST_TAP_TO_OPEN" 6 "POWERED_CLOSURE_REQUEST_REASON_UI_REQUEST" 5 "POWERED_CLOSURE_REQUEST_UI_STOP_ALL" 4 "POWERED_CLOSURE_REQUEST_KEYFOB_UNLOCK_OPEN" 3 "POWERED_CLOSURE_REQUEST_REASON_AUTO_PRESENT" 2 "POWERED_CLOSURE_REQUEST_REASON_CLOSE_ALL" 1 "POWERED_CLOSURE_REQUEST_REASON_RKE" 0 "POWERED_CLOSURE_REQUEST_REASON_NONE" ;
VAL_ 281 VCSEC_activeImmobilizerAuthLevel 3 "IMMOBILIZER_AUTH_LEVEL_MANUAL_RECOVERY" 2 "IMMOBILIZER_AUTH_LEVEL_AUTONOMY" 1 "IMMOBILIZER_AUTH_LEVEL_USER_DRIVE" 0 "IMMOBILIZER_AUTH_LEVEL_NONE" ;
VAL_ 281 VCSEC_smartTrunkLightRequest 3 "VCSEC_LIGHT_REQUEST_TYPE_DIM" 2 "VCSEC_LIGHT_REQUEST_TYPE_BLINK" 1 "VCSEC_LIGHT_REQUEST_TYPE_ON" 0 "VCSEC_LIGHT_REQUEST_TYPE_NONE" ;
VAL_ 281 VCSEC_smartTrunkSoundRequest 2 "VCSEC_SOUND_REQUEST_TYPE_NEAR" 1 "VCSEC_SOUND_REQUEST_TYPE_VICINITY" 0 "VCSEC_SOUND_REQUEST_TYPE_NONE" ;
VAL_ 281 VCSEC_chargeHandleRequestModel 8 "VCSEC_CHARGE_HANDLE_MODEL_SC_CCS2" 7 "VCSEC_CHARGE_HANDLE_MODEL_SC_NACS" 6 "VCSEC_CHARGE_HANDLE_MODEL_WC3_TYPE2" 5 "VCSEC_CHARGE_HANDLE_MODEL_UMC3_TYPE_2" 4 "VCSEC_CHARGE_HANDLE_MODEL_UMC3_GB" 3 "VCSEC_CHARGE_HANDLE_MODEL_UMC3_NACS" 2 "VCSEC_CHARGE_HANDLE_MODEL_WC3_NACS" 0 "VCSEC_CHARGE_HANDLE_MODEL_UNKNOWN" ;
VAL_ 281 VCSEC_mobileToAPRequest 4 "VCSEC_MOBILE_TO_AP_REQUEST_MAX" 2 "VCSEC_MOBILE_TO_AP_REQUEST_DISENGAGE_AUTONOMY" 1 "VCSEC_MOBILE_TO_AP_REQUEST_EMERGENCY_PULL_OVER" 0 "VCSEC_MOBILE_TO_AP_REQUEST_NONE" ;
VAL_ 1850 VC_LVBMS_brickMeasurementsMultip 2 "Mux2" 1 "Mux1" 0 "Mux0" ;
VAL_ 1850 VC_LVBMS_brickVoltage1 8191 "SNA" ;
VAL_ 1850 VC_LVBMS_brickVoltage2 8191 "SNA" ;
VAL_ 1850 VC_LVBMS_brickVoltage3 8191 "SNA" ;
VAL_ 1850 VC_LVBMS_brickVoltage4 8191 "SNA" ;
VAL_ 1850 VC_LVBMS_brickBalancingAh1 16777215 "SNA" ;
VAL_ 1850 VC_LVBMS_brickBalancingAh2 16777215 "SNA" ;
VAL_ 1850 VC_LVBMS_brickBalancingState1 1 "LVBMS_BALANCING_STATE_ACTIVE" 0 "LVBMS_BALANCING_STATE_INACTIVE" ;
VAL_ 1850 VC_LVBMS_brickBalancingState2 1 "LVBMS_BALANCING_STATE_ACTIVE" 0 "LVBMS_BALANCING_STATE_INACTIVE" ;
VAL_ 1850 VC_LVBMS_brickBalancingAh3 16777215 "SNA" ;
VAL_ 1850 VC_LVBMS_brickBalancingAh4 16777215 "SNA" ;
VAL_ 1850 VC_LVBMS_brickBalancingState3 1 "LVBMS_BALANCING_STATE_ACTIVE" 0 "LVBMS_BALANCING_STATE_INACTIVE" ;
VAL_ 1850 VC_LVBMS_brickBalancingState4 1 "LVBMS_BALANCING_STATE_ACTIVE" 0 "LVBMS_BALANCING_STATE_INACTIVE" ;
VAL_ 1655 VC_lvbmsStatusHighIndex 5 "INVALID" 4 "CELL_VITALS_2_AND_STATE_AND_COMMANDS" 3 "TARGETS" 2 "PCS_INTERFACE" 1 "CELL_VITALS_1" 0 "PACK_VITALS_1" ;
VAL_ 1655 VC_LVBMS_packCurrent 4194303 "SNA" ;
VAL_ 1655 VC_LVBMS_packVoltage 65535 "SNA" ;
VAL_ 1655 VC_LVBMS_packTemperature 511 "SNA" ;
VAL_ 1655 VC_LVBMS_MOSTemperature 4095 "SNA" ;
VAL_ 1655 VC_LVBMS_sumCellVoltage 65535 "SNA" 65534 "INVALID" ;
VAL_ 1655 VC_LVBMS_maxBrickVoltage 8191 "SNA" ;
VAL_ 1655 VC_LVBMS_maxBrickVoltageIndex 255 "SNA" ;
VAL_ 1655 VC_LVBMS_voltageTarget 65535 "SNA" ;
VAL_ 1655 VC_LVBMS_currentTarget 262143 "SNA" ;
VAL_ 1655 VC_LVBMS_maxAllowedChargeCurrent 8191 "SNA" ;
VAL_ 1655 VC_LVBMS_maxAllowedDischargeCurr 8191 "SNA" ;
VAL_ 1655 VC_LVBMS_ECPAState 3 "LVBMS_ECPA_STATE_SNA" 2 "LVBMS_ECPA_STATE_INVALID" 1 "LVBMS_ECPA_STATE_CLOSED" 0 "LVBMS_ECPA_STATE_OPEN" ;
VAL_ 1655 VC_LVBMS_MOSState 3 "LVBMS_MOS_STATE_SNA" 2 "LVBMS_MOS_STATE_INVALID" 1 "LVBMS_MOS_STATE_CLOSED" 0 "LVBMS_MOS_STATE_OPEN" ;
VAL_ 1655 VC_LVBMS_VehicleState 3 "LVBMS_VEHICLE_STATE_OFF" 2 "LVBMS_VEHICLE_STATE_CONDITIONING" 1 "LVBMS_VEHICLE_STATE_ACCESSORY" 0 "LVBMS_VEHICLE_STATE_DRIVE" ;
VAL_ 1655 VC_LVBMS_LINWakeDisabled 1 "LVBMS_LIN_WAKE_DISABLED" 0 "LVBMS_LIN_WAKE_ENABLED" ;
VAL_ 1655 VC_LVBMS_chargeType 4 "LVBMS_CHARGE_SNA" 3 "LVBMS_CHARGE_COMPLETE" 2 "LVBMS_CHARGE_CONSTANT_VOLTAGE" 1 "LVBMS_CHARGE_CONSTANT_CURRENT" 0 "LVBMS_CHARGE_UNDEFINED" ;
VAL_ 1655 VC_LVBMS_avgBrickVoltage 8191 "SNA" ;
VAL_ 1655 VC_LVBMS_minBrickVoltage 8191 "SNA" ;
VAL_ 1655 VC_LVBMS_minBrickVoltageIndex 255 "SNA" ;
VAL_ 1816 VC_lvbmsStatusLowIndex 5 "INVALID" 4 "PACK_VITALS_2" 3 "THROUGHPUT_3" 2 "THROUGHPUT_2" 1 "THROUGHPUT_1" 0 "STATE_AND_FAULTS" ;
VAL_ 1816 VC_LVBMS_SOC 1023 "SNA" ;
VAL_ 1816 VC_LVBMS_SOE 127 "SNA" ;
VAL_ 1816 VC_LVBMS_SOH 127 "SNA" ;
VAL_ 1816 VC_LVBMS_AvgSleepCurrent 65535 "SNA" ;
VAL_ 1816 VC_LVBMS_TimeSlept 16777215 "SNA" ;
VAL_ 1816 VC_LVBMS_SOP 255 "SNA" ;
VAL_ 1816 VC_LVBMS_AhCharged 4294967295 "SNA" ;
VAL_ 1816 VC_LVBMS_MinSleepCurrent 65535 "SNA" ;
VAL_ 1816 VC_LVBMS_AhDischarged 4294967295 "SNA" ;
VAL_ 1816 VC_LVBMS_MaxSleepCurrent 65535 "SNA" ;
VAL_ 1816 VC_LVBMS_sumCellVoltageFiltered 65535 "SNA" 65534 "INVALID" ;
VAL_ 1816 VC_LVBMS_maxCellSOC 1023 "SNA" ;
VAL_ 1816 VC_LVBMS_minCellSOC 1023 "SNA" ;
VAL_ 1816 VC_LVBMS_staticSOCCorrection 1 "LVBMS_CORRECTION_STATE_ACTIVE" 0 "LVBMS_CORRECTION_STATE_INACTIVE" ;
VAL_ 1816 VC_LVBMS_dynamicSOCCorrection 1 "LVBMS_CORRECTION_STATE_ACTIVE" 0 "LVBMS_CORRECTION_STATE_INACTIVE" ;
VAL_ 1816 VC_LVBMS_usableEnergyAvailable 4095 "SNA" ;
VAL_ 1816 VC_LVBMS_brakeTelltale 2 "DI_BRAKE_TELLTALE_OFF" 1 "DI_BRAKE_TELLTALE_YELLOW" 0 "DI_BRAKE_TELLTALE_RED" ;
VAL_ 1089 VC_pcsInterfaceMuxIndex 1 "1" 0 "0" ;
VAL_ 1089 VC_pcsResistanceFiltered 65535 "SNA" ;
VAL_ 1091 VC_pcsManagementMuxIndex 0 "INDEX_0" ;
VAL_ 1091 VC_dcdcLVVoltageTargetMax 1023 "UNRESTRICTED" ;
VAL_ 1091 VC_dcdcLVVoltageTargetMin 0 "UNRESTRICTED" ;
VAL_ 1091 VC_dcdcLVInputPowerLimit 255 "UNRESTRICTED" ;
VAL_ 1029 VIN_muxID 18 "VIN_PAGE_3" 17 "VIN_PAGE_2" 16 "VIN_PAGE_1" ;
